VERSION ""

NS_ :

BS_:

BU_: VCU BCM SS IPC ABS ACU

BO_ 872 GW_EDS_Fault: 8 VCU
 SG_ EDS_MotTempSenFault : 0|1@0+ (1,0) [0|1] ""  IPC
 SG_ EDS_EDSOverTempAlarm : 4|1@0+ (1,0) [0|1] ""  IPC
 SG_ EDS_EDSOverTempFault : 5|1@0+ (1,0) [0|1] ""  IPC
 SG_ EDS_LV_VotagtFault : 6|1@0+ (1,0) [0|1] ""  IPC
 SG_ EDS_PhashOverCurrentSWFault : 7|1@0+ (1,0) [0|1] ""  IPC
 SG_ EDS_EDSCurrentSenVFault : 8|1@0+ (1,0) [0|1] ""  IPC
 SG_ EDS_EDSCurrentSenWFault : 9|1@0+ (1,0) [0|1] ""  IPC
 SG_ EDS_EDSHVOverVoltageAlarm : 10|1@0+ (1,0) [0|1] ""  IPC
 SG_ EDS_EDSHVOverVoltageFault : 11|1@0+ (1,0) [0|1] ""  IPC
 SG_ EDS_EDSHVUnderVoltageAlarm : 12|1@0+ (1,0) [0|1] ""  IPC
 SG_ EDS_EDSHVUnderVoltageFault : 13|1@0+ (1,0) [0|1] ""  IPC
 SG_ EDS_MotOverTempAlarm : 14|1@0+ (1,0) [0|1] ""  IPC
 SG_ EDS_MotOverTempFault : 15|1@0+ (1,0) [0|1] ""  IPC
 SG_ EDS_EDSDisChgFault : 16|1@0+ (1,0) [0|1] ""  IPC
 SG_ EDS_EDSHVSenFault : 17|1@0+ (1,0) [0|1] ""  IPC
 SG_ EDS_12VOverVoltageAlarm : 18|1@0+ (1,0) [0|1] ""  IPC
 SG_ EDS_12VUnderVoltageAlarm : 19|1@0+ (1,0) [0|1] ""  IPC
 SG_ EDS_MotOverAlarm : 20|1@0+ (1,0) [0|1] ""  IPC
 SG_ EDS_MotOverFault : 21|1@0+ (1,0) [0|1] ""  IPC
 SG_ EDS_PhashOverCurrentHWFault : 22|1@0+ (1,0) [0|1] ""  IPC
 SG_ EDS_EDSCurrentSenUFault : 23|1@0+ (1,0) [0|1] ""  IPC
 SG_ EDS_VCULostFault : 24|1@0+ (1,0) [0|1] ""  IPC
 SG_ EDS_BMSLostFault : 25|1@0+ (1,0) [0|1] ""  IPC
 SG_ EDS_MotRotSenFault : 26|1@0+ (1,0) [0|1] ""  IPC
 SG_ EDS_MotBlockedFault : 27|1@0+ (1,0) [0|1] ""  IPC
 SG_ EDS_EDSChksumFault : 28|1@0+ (1,0) [0|1] ""  IPC
 SG_ EDS_MotTrqLimtFault : 29|1@0+ (1,0) [0|1] ""  IPC
 SG_ EDS_VCUChksumFault : 30|1@0+ (1,0) [0|1] ""  IPC
 SG_ EDS_EDSEnableFault : 31|1@0+ (1,0) [0|1] ""  IPC
 SG_ EDS_IGBTFault : 38|1@0+ (1,0) [0|1] ""  IPC
 SG_ EDS_CANBUSOFFFault : 39|1@0+ (1,0) [0|1] ""  IPC
 SG_ EDS_EDSTempSensorErr : 43|1@0+ (1,0) [0|1] ""  IPC
 SG_ EDS_HWCapOverVolt : 44|1@0+ (1,0) [0|1] ""  IPC
 SG_ EDS_SWCapOverVolt : 45|1@0+ (1,0) [0|1] ""  IPC
 SG_ EDS_EDSMemoryFlt : 46|1@0+ (1,0) [0|1] ""  IPC
 SG_ EDS_InitMode : 47|1@0+ (1,0) [0|1] ""  IPC
 SG_ EDS_MotorSN : 51|4@0+ (1,0) [0|1] ""  IPC
 SG_ EDS_EDSFaultCode : 63|8@0+ (1,0) [0|255] ""  IPC

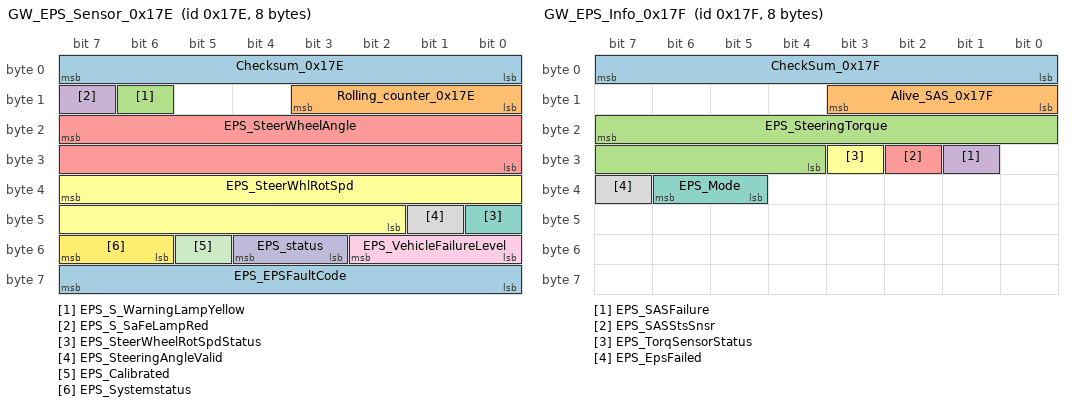
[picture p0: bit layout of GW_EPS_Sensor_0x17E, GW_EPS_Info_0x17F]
BO_ 382 GW_EPS_Sensor_0x17E: 8 VCU
 SG_ Checksum_0x17E : 7|8@0+ (1,0) [0|255] ""  BCM,IPC,ABS,ACU
 SG_ Rolling_counter_0x17E : 11|4@0+ (1,0) [0|15] ""  BCM,IPC,ABS,ACU
 SG_ EPS_S_WarningLampYellow : 14|1@0+ (1,0) [0|1] ""  BCM,IPC,ABS,ACU
 SG_ EPS_S_SaFeLampRed : 15|1@0+ (1,0) [0|1] ""  BCM,IPC,ABS,ACU
 SG_ EPS_SteerWheelAngle : 23|16@0+ (0.0238,-780) [-780|779.7] "deg"  BCM,IPC,ABS,ACU
 SG_ EPS_SteerWhlRotSpd : 39|14@0+ (0.125,-1024) [-1024|1023.75] "degs"  BCM,IPC,ABS,ACU
 SG_ EPS_SteerWheelRotSpdStatus : 40|1@0+ (1,0) [0|1] ""  BCM,IPC,ABS,ACU
 SG_ EPS_SteeringAngleValid : 41|1@0+ (1,0) [0|1] ""  BCM,IPC,ABS,ACU
 SG_ EPS_VehicleFailureLevel : 50|3@0+ (1,0) [0|7] ""  BCM,IPC,ABS,ACU
 SG_ EPS_status : 52|2@0+ (1,0) [0|3] ""  BCM,IPC,ABS,ACU
 SG_ EPS_Calibrated : 53|1@0+ (1,0) [0|1] ""  BCM,IPC,ABS,ACU
 SG_ EPS_Systemstatus : 55|2@0+ (1,0) [0|3] ""  BCM,IPC,ABS,ACU
 SG_ EPS_EPSFaultCode : 63|8@0+ (1,0) [0|63] ""  BCM,IPC,ABS,ACU

BO_ 383 GW_EPS_Info_0x17F: 8 VCU
 SG_ CheckSum_0x17F : 7|8@0+ (1,0) [0|255] ""  BCM,IPC,ABS,ACU
 SG_ Alive_SAS_0x17F : 11|4@0+ (1,0) [0|15] ""  BCM,IPC,ABS,ACU
 SG_ EPS_SteeringTorque : 23|12@0+ (0.01,-10.24) [-10.24|10.23] "N*m"  BCM,IPC,ABS,ACU
 SG_ EPS_SASFailure : 25|1@0+ (1,0) [0|1] ""  BCM,IPC,ABS,ACU
 SG_ EPS_SASStsSnsr : 26|1@0+ (1,0) [0|1] ""  BCM,IPC,ABS,ACU
 SG_ EPS_TorqSensorStatus : 27|1@0+ (1,0) [0|1] ""  BCM,IPC,ABS,ACU
 SG_ EPS_Mode : 38|2@0+ (1,0) [0|3] ""  BCM,IPC,ABS,ACU
 SG_ EPS_EpsFailed : 39|1@0+ (1,0) [0|1] ""  BCM,IPC,ABS,ACU

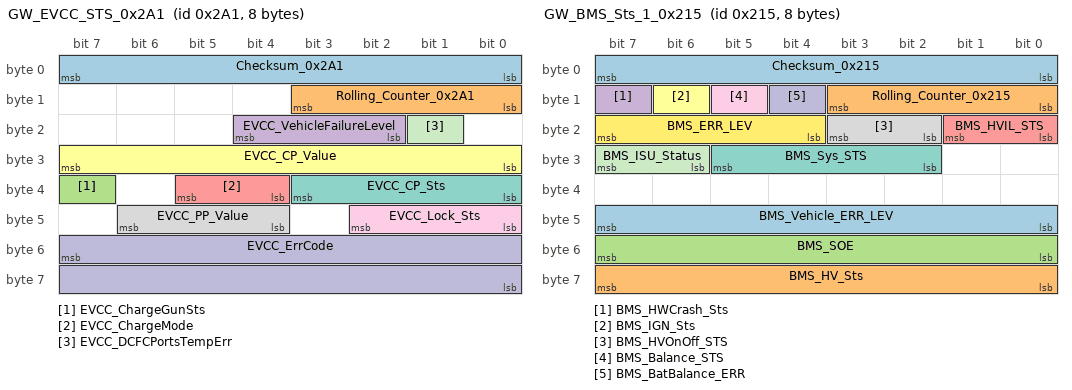
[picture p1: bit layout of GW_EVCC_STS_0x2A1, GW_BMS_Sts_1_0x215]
BO_ 673 GW_EVCC_STS_0x2A1: 8 VCU
 SG_ Checksum_0x2A1 : 7|8@0+ (1,0) [0|255] ""  IPC
 SG_ Rolling_Counter_0x2A1 : 11|4@0+ (1,0) [0|15] ""  IPC
 SG_ EVCC_ChargeGunSts : 39|1@0+ (1,0) [0|1] ""  IPC
 SG_ EVCC_VehicleFailureLevel : 20|3@0+ (1,0) [0|7] ""  IPC
 SG_ EVCC_ChargeMode : 37|2@0+ (1,0) [0|3] ""  IPC
 SG_ EVCC_CP_Value : 31|8@0+ (1,0) [0|100] "%"  IPC
 SG_ EVCC_CP_Sts : 35|4@0+ (1,0) [0|15] ""  IPC
 SG_ EVCC_PP_Value : 46|3@0+ (1,0) [0|7] ""  IPC
 SG_ EVCC_Lock_Sts : 42|3@0+ (1,0) [0|7] ""  IPC
 SG_ EVCC_ErrCode : 55|16@0+ (1,0) [0|65535] ""  IPC
 SG_ EVCC_DCFCPortsTempErr : 17|1@0+ (1,0) [0|1] ""  IPC

BO_ 992 GW_EVCC_HMI_charging_0x3E0: 8 VCU
 SG_ Checksum_0x3E0 : 7|8@0+ (1,0) [0|255] ""  IPC
 SG_ Rolling_Counter_0x3E0 : 11|4@0+ (1,0) [0|15] ""  IPC
 SG_ EVCC_IPC_Ack_ChgSche_stt : 27|2@0+ (1,0) [0|3] ""  IPC
 SG_ EVCC_IPC_Ack_TargetSOC : 39|8@0+ (1,0) [0|100] "%"  IPC

BO_ 537 GW_EVCC_PT_Control_0x219: 8 VCU
 SG_ Checksum_0x219 : 7|8@0+ (1,0) [0|255] ""  BCM,IPC
 SG_ Rolling_Counter_0x219 : 11|4@0+ (1,0) [0|15] ""  BCM,IPC
 SG_ EVCC_ChargeAllow : 54|1@0+ (1,0) [0|1] ""  BCM,IPC
 SG_ EVCC_ChrSOCLitFb : 49|10@0+ (0.1,0) [0|1000] "%"  BCM,IPC

BO_ 293 GW_BMS_Power_0x125: 8 VCU
 SG_ Checksum_0x125 : 7|8@0+ (1,0) [0|255] ""  IPC
 SG_ Rolling_Counter_0x125 : 11|4@0+ (1,0) [0|15] ""  IPC
 SG_ BMS_Actual_ChgPower : 38|15@0+ (0.01,0) [0|100] "Kw"  IPC
 SG_ BMS_Actual_DisChgPower : 54|15@0+ (0.01,0) [0|100] "Kw"  IPC

BO_ 534 GW_BMS_ChgParamReq_0x216: 8 VCU
 SG_ Checksum_0x216 : 7|8@0+ (1,0) [0|255] ""  IPC
 SG_ Rolling_Counter_0x216 : 11|4@0+ (1,0) [0|15] ""  IPC
 SG_ BMS_RemainChargeTime : 21|14@0+ (1,0) [0|16383] "min"  IPC
 SG_ BMS_ChgVoltage_REQ : 37|14@0+ (0.1,0) [0|800] "V"  IPC
 SG_ BMS_ChgCurrent_REQ : 55|16@0+ (0.1,0) [0|1500] "A"  IPC

BO_ 533 GW_BMS_Sts_1_0x215: 8 VCU
 SG_ Checksum_0x215 : 7|8@0+ (1,0) [0|255] ""  BCM,IPC
 SG_ Rolling_Counter_0x215 : 11|4@0+ (1,0) [0|15] ""  BCM,IPC
 SG_ BMS_SOE : 55|8@0+ (0.5,0) [0|100] "%" Vector__XXX
 SG_ BMS_HWCrash_Sts : 15|1@0+ (1,0) [0|1] "" Vector__XXX
 SG_ BMS_HVIL_STS : 17|2@0+ (1,0) [0|3] ""  IPC
 SG_ BMS_IGN_Sts : 14|1@0+ (1,0) [0|1] ""  IPC
 SG_ BMS_Sys_STS : 29|4@0+ (1,0) [0|15] ""  IPC
 SG_ BMS_HVOnOff_STS : 19|2@0+ (1,0) [0|3] ""  IPC
 SG_ BMS_Balance_STS : 13|1@0+ (1,0) [0|1] ""  IPC
 SG_ BMS_BatBalance_ERR : 12|1@0+ (1,0) [0|1] ""  IPC
 SG_ BMS_ISU_Status : 31|2@0+ (1,0) [0|3] ""  IPC
 SG_ BMS_ERR_LEV : 23|4@0+ (1,0) [0|15] ""  IPC
 SG_ BMS_Vehicle_ERR_LEV : 47|8@0+ (1,0) [0|15] ""  IPC
 SG_ BMS_HV_Sts : 63|8@0+ (1,0) [0|255] ""  IPC

BO_ 1171 GW_BMS_WarnMsg_0x493: 8 VCU
 SG_ BMS_Warning_Flag_Reserved_08 : 16|1@0+ (1,0) [0|1] ""  IPC
 SG_ BMS_Warning_Flag_Reserved_07 : 17|1@0+ (1,0) [0|1] ""  IPC
 SG_ BMS_Warning_Flag_Reserved_11 : 47|8@0+ (1,0) [0|255] ""  IPC
 SG_ BMS_Warning_Flag_Reserved_10 : 39|8@0+ (1,0) [0|255] ""  IPC
 SG_ BMS_Warning_Flag_Reserved_09 : 31|8@0+ (1,0) [0|255] ""  IPC
 SG_ BMS_Warning_Flag_Reserved_13 : 63|8@0+ (1,0) [0|255] ""  IPC
 SG_ BMS_Warning_Flag_Reserved_12 : 55|8@0+ (1,0) [0|255] ""  IPC
 SG_ BMS_Warning_Flag_Reserved_06 : 18|1@0+ (1,0) [0|1] ""  IPC
 SG_ BMS_Warning_Flag_Reserved_05 : 19|1@0+ (1,0) [0|1] ""  IPC
 SG_ BMS_Warning_Flag_Reserved_04 : 20|1@0+ (1,0) [0|1] ""  IPC
 SG_ BMS_MalfunctionSts : 21|1@0+ (1,0) [0|1] ""  IPC
 SG_ BMS_LowBattery : 23|2@0+ (1,0) [0|3] ""  IPC
 SG_ BMS_BatteryReplacement : 15|1@0+ (1,0) [0|1] ""  IPC
 SG_ BMS_PackTempSts : 13|2@0+ (1,0) [0|3] ""  IPC
 SG_ BMS_ThermalRunaway : 14|1@0+ (1,0) [0|1] ""  IPC
 SG_ Rolling_Counter_0x493 : 11|4@0+ (1,0) [0|15] ""  IPC
 SG_ Checksum_0x493 : 7|8@0+ (1,0) [0|255] ""  IPC

BO_ 372 GW_BMS_CurMeas_0x174: 8 VCU
 SG_ Checksum_0x174 : 7|8@0+ (1,0) [0|255] ""  IPC
 SG_ Rolling_Counter_0x174 : 11|4@0+ (1,0) [0|15] ""  IPC
 SG_ BMS_PackCur_MEAS : 23|16@0+ (0.1,-3276.8) [-3276.8|3276.7] "A"  IPC
 SG_ BMS_AllowDischgCurr : 39|16@0+ (0.1,0) [0|1500] "A"  IPC
 SG_ BMS_AllowDischgCurrPeak : 55|16@0+ (0.1,0) [0|1500] "A"  IPC

BO_ 374 GW_BMS_HVMeas1_0x176: 8 VCU
 SG_ Checksum_0x176 : 7|8@0+ (1,0) [0|255] ""  IPC
 SG_ Rolling_Counter_0x176 : 11|4@0+ (1,0) [0|15] ""  IPC
 SG_ BMS_HVLinkVol_MEAS : 39|16@0+ (0.1,0) [0|800] "V"  IPC
 SG_ BMS_HVPackVol_MEAS : 23|16@0+ (0.1,0) [0|800] "V"  IPC

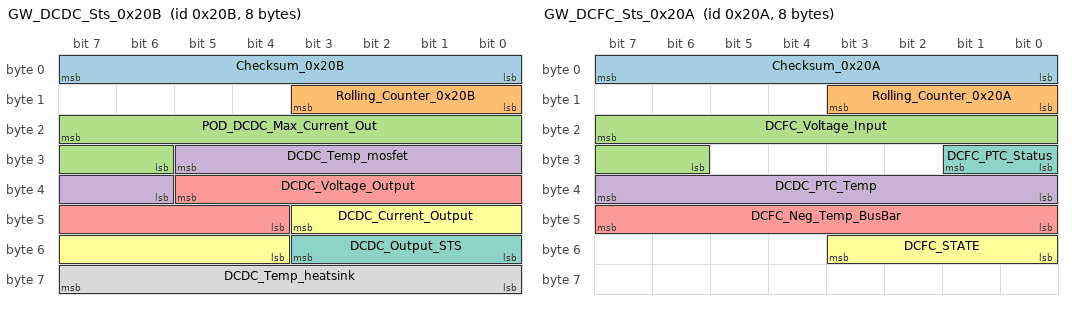
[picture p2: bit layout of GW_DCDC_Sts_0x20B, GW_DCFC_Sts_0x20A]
BO_ 523 GW_DCDC_Sts_0x20B: 8 VCU
 SG_ Checksum_0x20B : 7|8@0+ (1,0) [0|255] ""  IPC
 SG_ Rolling_Counter_0x20B : 11|4@0+ (1,0) [0|15] ""  IPC
 SG_ POD_DCDC_Max_Current_Out : 23|10@0+ (1,0) [0|1000] "A"  IPC
 SG_ DCDC_Temp_mosfet : 29|8@0+ (1,-40) [-40|215] ""  IPC
 SG_ DCDC_Voltage_Output : 37|10@0+ (0.1,0) [0|40] "V"  IPC
 SG_ DCDC_Current_Output : 43|8@0+ (1,0) [0|255] "A"  IPC
 SG_ DCDC_Output_STS : 51|4@0+ (1,0) [0|15] ""  IPC
 SG_ DCDC_Temp_heatsink : 63|8@0+ (1,-40) [-40|215] ""  IPC

BO_ 1030 GW_Error_Level_DCDC_0x406: 8 VCU
 SG_ Checksum_0x406 : 7|8@0+ (1,0) [0|255] ""  IPC
 SG_ Rolling_Counter_0x406 : 11|4@0+ (1,0) [0|15] ""  IPC
 SG_ DCDC_FaultLevel : 19|4@0+ (1,0) [0|15] ""  IPC
 SG_ DCFC_FaultLevel : 23|4@0+ (1,0) [0|15] ""  IPC

BO_ 522 GW_DCFC_Sts_0x20A: 8 VCU
 SG_ Checksum_0x20A : 7|8@0+ (1,0) [0|255] ""  IPC
 SG_ Rolling_Counter_0x20A : 11|4@0+ (1,0) [0|15] ""  IPC
 SG_ DCFC_Voltage_Input : 23|10@0+ (1,0) [0|1000] "V"  IPC
 SG_ DCDC_PTC_Temp : 39|8@0+ (1,-40) [-40|215] ""  IPC
 SG_ DCFC_Neg_Temp_BusBar : 47|8@0+ (1,-40) [-40|215] ""  IPC
 SG_ DCFC_STATE : 51|4@0+ (1,0) [0|15] ""  IPC
 SG_ DCFC_PTC_Status : 25|2@0+ (1,0) [0|3] ""  IPC

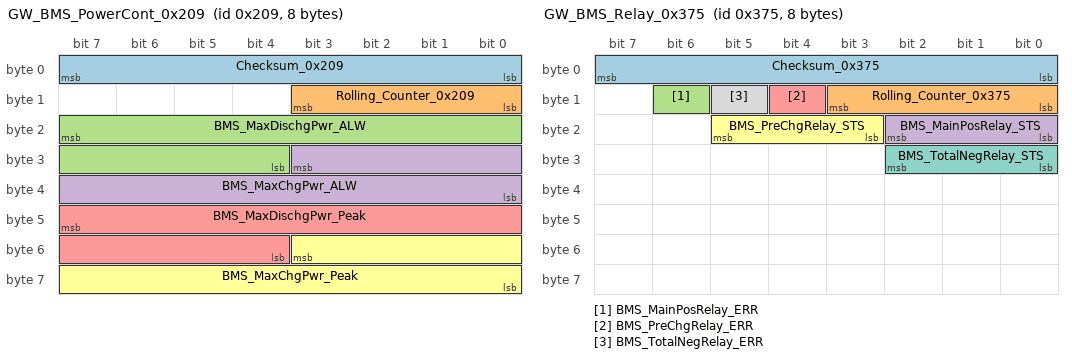
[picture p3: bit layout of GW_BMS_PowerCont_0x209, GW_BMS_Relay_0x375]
BO_ 521 GW_BMS_PowerCont_0x209: 8 VCU
 SG_ Checksum_0x209 : 7|8@0+ (1,0) [0|255] ""  IPC
 SG_ Rolling_Counter_0x209 : 11|4@0+ (1,0) [0|15] ""  IPC
 SG_ BMS_MaxDischgPwr_ALW : 23|12@0+ (0.1,0) [0|400] "KW"  IPC
 SG_ BMS_MaxChgPwr_ALW : 27|12@0+ (0.1,0) [0|400] "KW"  IPC
 SG_ BMS_MaxDischgPwr_Peak : 47|12@0+ (0.2,0) [0|800] "kw"  IPC
 SG_ BMS_MaxChgPwr_Peak : 51|12@0+ (0.2,0) [0|800] "kw"  IPC

BO_ 818 GW_BMS_PackInfo_0x332: 8 VCU
 SG_ Checksum_0x332 : 7|8@0+ (1,0) [0|255] ""  IPC
 SG_ Rolling_Counter_0x332 : 11|4@0+ (1,0) [0|15] ""  IPC
 SG_ BMS_PackTemp_Infor : 39|8@0+ (1,-40) [-40|215] ""  IPC
 SG_ BMS_PackCNom : 23|16@0+ (0.1,0) [0|6553.5] "kwh"  IPC

BO_ 816 GW_BMS_HistData_0x330: 8 VCU
 SG_ Checksum_0x330 : 7|8@0+ (1,0) [0|255] ""  IPC
 SG_ Rolling_Counter_0x330 : 11|4@0+ (1,0) [0|15] ""  IPC
 SG_ BMS_ContactorAging : 23|8@0+ (1,0) [0|100] "%"  IPC

BO_ 375 GW_BMS_HVMeas2_0x177: 8 VCU
 SG_ Checksum_0x177 : 7|8@0+ (1,0) [0|255] ""  IPC
 SG_ Rolling_Counter_0x177 : 11|4@0+ (1,0) [0|15] ""  IPC
 SG_ BMS_HVBusVol_MEAS : 23|16@0+ (0.1,0) [0|800] "V"  IPC
 SG_ BMS_HVFuseVol_MEAS : 39|16@0+ (0.1,0) [0|800] "V"  IPC

BO_ 532 GW_BMS_Sts_0x214: 8 VCU
 SG_ Checksum_0x214 : 7|8@0+ (1,0) [0|255] ""  BCM,IPC
 SG_ Rolling_Counter_0x214 : 11|4@0+ (1,0) [0|15] ""  BCM,IPC
 SG_ BMS_Display_SOC : 21|10@0+ (0.1,0) [0|100] "%"  BCM,IPC
 SG_ BMS_SocActual_EST : 25|10@0+ (0.1,0) [0|100] "percent"  BCM,IPC
 SG_ BMS_SOH : 47|8@0+ (0.5,0) [0|100] "%"  BCM,IPC

BO_ 885 GW_BMS_Relay_0x375: 8 VCU
 SG_ Checksum_0x375 : 7|8@0+ (1,0) [0|255] ""  IPC
 SG_ Rolling_Counter_0x375 : 11|4@0+ (1,0) [0|15] ""  IPC
 SG_ BMS_MainPosRelay_ERR : 14|1@0+ (1,0) [0|1] ""  IPC
 SG_ BMS_MainPosRelay_STS : 18|3@0+ (1,0) [0|7] ""  IPC
 SG_ BMS_PreChgRelay_ERR : 12|1@0+ (1,0) [0|1] ""  IPC
 SG_ BMS_PreChgRelay_STS : 21|3@0+ (1,0) [0|7] ""  IPC
 SG_ BMS_TotalNegRelay_STS : 26|3@0+ (1,0) [0|7] ""  IPC
 SG_ BMS_TotalNegRelay_ERR : 13|1@0+ (1,0) [0|1] ""  IPC

BO_ 773 GW_BMS_Insulation_0x305: 8 VCU
 SG_ Checksum_0x305 : 7|8@0+ (1,0) [0|255] ""  IPC
 SG_ Rolling_Counter_0x305 : 11|4@0+ (1,0) [0|15] ""  IPC
 SG_ BMS_VCU_Insulation_Mon_Sts : 15|1@0+ (1,0) [0|1] ""  IPC
 SG_ BMS_PackInsuRes : 23|16@0+ (1,0) [0|60000] "kOhm"  IPC

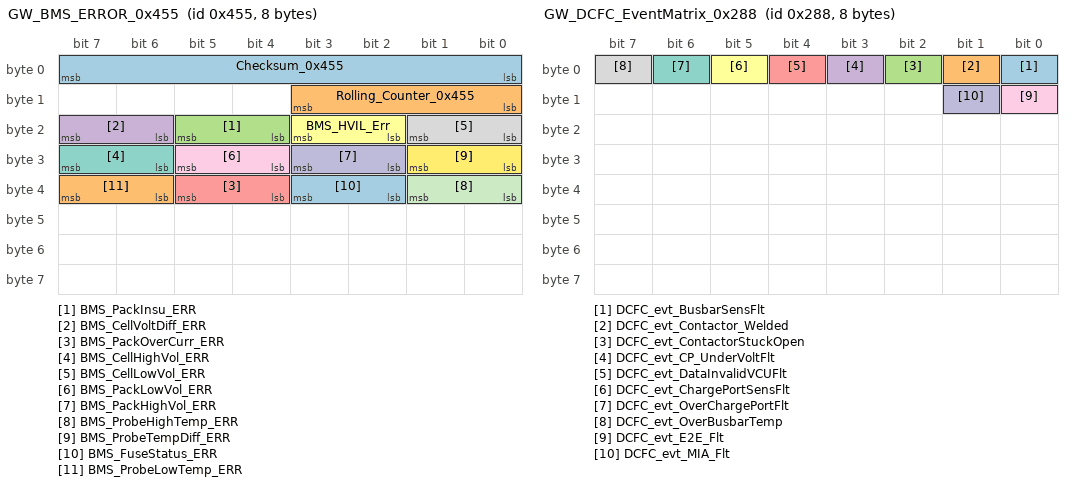
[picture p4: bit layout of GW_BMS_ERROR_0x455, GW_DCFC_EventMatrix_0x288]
BO_ 1109 GW_BMS_ERROR_0x455: 8 VCU
 SG_ Checksum_0x455 : 7|8@0+ (1,0) [0|255] ""  BCM,IPC
 SG_ Rolling_Counter_0x455 : 11|4@0+ (1,0) [0|15] ""  BCM,IPC
 SG_ BMS_PackInsu_ERR : 21|2@0+ (1,0) [0|3] ""  BCM,IPC
 SG_ BMS_CellVoltDiff_ERR : 23|2@0+ (1,0) [0|3] ""  BCM,IPC
 SG_ BMS_PackOverCurr_ERR : 37|2@0+ (1,0) [0|3] ""  BCM,IPC
 SG_ BMS_HVIL_Err : 19|2@0+ (1,0) [0|3] ""  BCM,IPC
 SG_ BMS_CellHighVol_ERR : 31|2@0+ (1,0) [0|3] ""  BCM,IPC
 SG_ BMS_CellLowVol_ERR : 17|2@0+ (1,0) [0|3] ""  BCM,IPC
 SG_ BMS_PackLowVol_ERR : 29|2@0+ (1,0) [0|3] ""  BCM,IPC
 SG_ BMS_PackHighVol_ERR : 27|2@0+ (1,0) [0|3] ""  BCM,IPC
 SG_ BMS_ProbeHighTemp_ERR : 33|2@0+ (1,0) [0|3] ""  BCM,IPC
 SG_ BMS_ProbeTempDiff_ERR : 25|2@0+ (1,0) [0|3] ""  BCM,IPC
 SG_ BMS_FuseStatus_ERR : 35|2@0+ (1,0) [0|1] ""  BCM,IPC
 SG_ BMS_ProbeLowTemp_ERR : 39|2@0+ (1,0) [0|3] ""  BCM,IPC

BO_ 646 GW_DCFC_IO1_0x286: 8 VCU
 SG_ Checksum_0x286 : 7|8@0+ (1,0) [0|255] ""  IPC
 SG_ Rolling_Counter_0x286 : 11|4@0+ (1,0) [0|15] ""  IPC
 SG_ DCFC_OUT_DC_V : 23|16@0+ (0.1,0) [0|6553.5] "V"  IPC
 SG_ DCFC_OUT_DC_I : 39|14@0+ (0.1,0) [0|1000] "A"  IPC
 SG_ DCFC_DCCharge_line_V : 55|16@0+ (0.1,0) [0|6553.5] "V"  IPC

BO_ 647 GW_DCDC_EventMatrix_0x287: 8 VCU
 SG_ DCDC_evt_BUS_OFF : 0|1@0+ (1,0) [0|1] ""  IPC
 SG_ DCDC_evt_MIA : 1|1@0+ (1,0) [0|1] ""  IPC
 SG_ DCDC_evt_E2E : 2|1@0+ (1,0) [0|1] ""  IPC
 SG_ DCDC_evt_Calibration_Flt : 3|1@0+ (1,0) [0|1] ""  IPC
 SG_ DCDC_evt_flash_Failure : 4|1@0+ (1,0) [0|1] ""  IPC
 SG_ DCDC_evt_FaultLatchCircuit : 5|1@0+ (1,0) [0|1] ""  IPC
 SG_ DCDC_evt_HV_VoltSensFlt : 6|1@0+ (1,0) [0|1] ""  IPC
 SG_ DCDC_evt_HV_OverVoltFlt : 7|1@0+ (1,0) [0|1] ""  IPC
 SG_ DCDC_evt_HV_UnderVoltFlt : 8|1@0+ (1,0) [0|1] ""  IPC
 SG_ DCDC_evt_LV_VoltSensFlt : 9|1@0+ (1,0) [0|1] ""  IPC
 SG_ DCDC_evt_LVBatt_OverVoltFlt : 10|1@0+ (1,0) [0|1] ""  IPC
 SG_ DCDC_evt_LVBatt_UnderVoltFlt : 11|1@0+ (1,0) [0|1] ""  IPC
 SG_ DCDC_evt_LVBatt_SensorFlt : 12|1@0+ (1,0) [0|1] ""  IPC
 SG_ DCDC_evt_LV_RedundancyFlt : 13|1@0+ (1,0) [0|1] ""  IPC
 SG_ DCDC_evt_LV_CurrSensFlt : 14|1@0+ (1,0) [0|1] ""  IPC
 SG_ DCDC_evt_LV_OverCurr : 15|1@0+ (1,0) [0|1] ""  IPC
 SG_ DCDC_evt_ReverseCurrFlt : 16|1@0+ (1,0) [0|1] ""  IPC
 SG_ DCDC_evt_Heater_TempSensorFlt : 17|1@0+ (1,0) [0|1] ""  IPC
 SG_ DCDC_evt_Mosfet_TempSensorFlt : 18|1@0+ (1,0) [0|1] ""  IPC
 SG_ DCDC_evt_Mosfet_OverTemp : 19|1@0+ (1,0) [0|1] ""  IPC
 SG_ DCDC_evt_HeatSink_TempSensorFlt : 20|1@0+ (1,0) [0|1] ""  IPC
 SG_ DCDC_evt_HeatSink_OverTemp : 21|1@0+ (1,0) [0|1] ""  IPC
 SG_ DCDC_evt_Heater_OverTempFlt : 22|1@0+ (1,0) [0|1] ""  IPC
 SG_ DCDC_evt_Heater_ShortIGBTFlt : 23|1@0+ (1,0) [0|1] ""  IPC
 SG_ DCDC_evt_LV_ShortOutputFlt : 24|1@0+ (1,0) [0|1] ""  IPC
 SG_ DCDC_evt_sw_BMS_CrashFlt : 25|1@0+ (1,0) [0|1] ""  IPC
 SG_ DCDC_evt_BMS_HVILFlt : 26|1@0+ (1,0) [0|1] ""  IPC

BO_ 648 GW_DCFC_EventMatrix_0x288: 8 VCU
 SG_ DCFC_evt_BusbarSensFlt : 0|1@0+ (1,0) [0|1] ""  IPC
 SG_ DCFC_evt_Contactor_Welded : 1|1@0+ (1,0) [0|1] ""  IPC
 SG_ DCFC_evt_ContactorStuckOpen : 2|1@0+ (1,0) [0|1] ""  IPC
 SG_ DCFC_evt_CP_UnderVoltFlt : 3|1@0+ (1,0) [0|1] ""  IPC
 SG_ DCFC_evt_DataInvalidVCUFlt : 4|1@0+ (1,0) [0|1] ""  IPC
 SG_ DCFC_evt_ChargePortSensFlt : 5|1@0+ (1,0) [0|1] ""  IPC
 SG_ DCFC_evt_OverChargePortFlt : 6|1@0+ (1,0) [0|1] ""  IPC
 SG_ DCFC_evt_OverBusbarTemp : 7|1@0+ (1,0) [0|1] ""  IPC
 SG_ DCFC_evt_E2E_Flt : 8|1@0+ (1,0) [0|1] ""  IPC
 SG_ DCFC_evt_MIA_Flt : 9|1@0+ (1,0) [0|1] ""  IPC

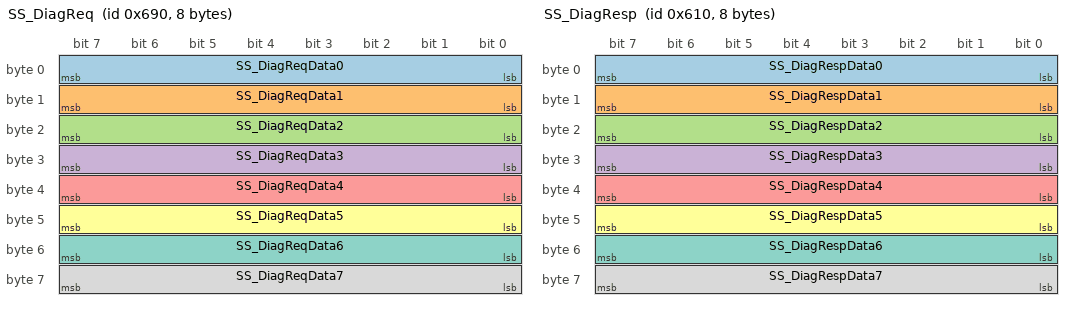
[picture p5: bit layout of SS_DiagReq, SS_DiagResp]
BO_ 1680 SS_DiagReq: 8 VCU
 SG_ SS_DiagReqData0 : 7|8@0+ (1,0) [0|255] ""  SS
 SG_ SS_DiagReqData1 : 15|8@0+ (1,0) [0|255] ""  SS
 SG_ SS_DiagReqData2 : 23|8@0+ (1,0) [0|255] ""  SS
 SG_ SS_DiagReqData3 : 31|8@0+ (1,0) [0|255] ""  SS
 SG_ SS_DiagReqData4 : 39|8@0+ (1,0) [0|255] ""  SS
 SG_ SS_DiagReqData5 : 47|8@0+ (1,0) [0|255] ""  SS
 SG_ SS_DiagReqData6 : 55|8@0+ (1,0) [0|255] ""  SS
 SG_ SS_DiagReqData7 : 63|8@0+ (1,0) [0|255] ""  SS

BO_ 1552 SS_DiagResp: 8 SS
 SG_ SS_DiagRespData0 : 7|8@0+ (1,0) [0|255] ""  VCU,IPC
 SG_ SS_DiagRespData1 : 15|8@0+ (1,0) [0|255] ""  VCU,IPC
 SG_ SS_DiagRespData2 : 23|8@0+ (1,0) [0|255] ""  VCU,IPC
 SG_ SS_DiagRespData3 : 31|8@0+ (1,0) [0|255] ""  VCU,IPC
 SG_ SS_DiagRespData4 : 39|8@0+ (1,0) [0|255] ""  VCU,IPC
 SG_ SS_DiagRespData5 : 47|8@0+ (1,0) [0|255] ""  VCU,IPC
 SG_ SS_DiagRespData6 : 55|8@0+ (1,0) [0|255] ""  VCU,IPC
 SG_ SS_DiagRespData7 : 63|8@0+ (1,0) [0|255] ""  VCU,IPC

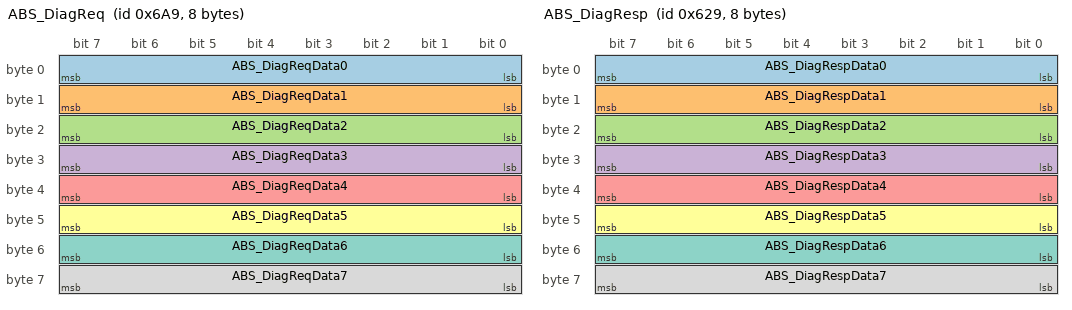
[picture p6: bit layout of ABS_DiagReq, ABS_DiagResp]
BO_ 1705 ABS_DiagReq: 8 VCU
 SG_ ABS_DiagReqData0 : 7|8@0+ (1,0) [0|255] ""  ABS
 SG_ ABS_DiagReqData1 : 15|8@0+ (1,0) [0|255] ""  ABS
 SG_ ABS_DiagReqData2 : 23|8@0+ (1,0) [0|255] ""  ABS
 SG_ ABS_DiagReqData3 : 31|8@0+ (1,0) [0|255] ""  ABS
 SG_ ABS_DiagReqData4 : 39|8@0+ (1,0) [0|255] ""  ABS
 SG_ ABS_DiagReqData5 : 47|8@0+ (1,0) [0|255] ""  ABS
 SG_ ABS_DiagReqData6 : 55|8@0+ (1,0) [0|255] ""  ABS
 SG_ ABS_DiagReqData7 : 63|8@0+ (1,0) [0|255] ""  ABS

BO_ 1577 ABS_DiagResp: 8 ABS
 SG_ ABS_DiagRespData0 : 7|8@0+ (1,0) [0|255] ""  VCU,IPC
 SG_ ABS_DiagRespData1 : 15|8@0+ (1,0) [0|255] ""  VCU,IPC
 SG_ ABS_DiagRespData2 : 23|8@0+ (1,0) [0|255] ""  VCU,IPC
 SG_ ABS_DiagRespData3 : 31|8@0+ (1,0) [0|255] ""  VCU,IPC
 SG_ ABS_DiagRespData4 : 39|8@0+ (1,0) [0|255] ""  VCU,IPC
 SG_ ABS_DiagRespData5 : 47|8@0+ (1,0) [0|255] ""  VCU,IPC
 SG_ ABS_DiagRespData6 : 55|8@0+ (1,0) [0|255] ""  VCU,IPC
 SG_ ABS_DiagRespData7 : 63|8@0+ (1,0) [0|255] ""  VCU,IPC

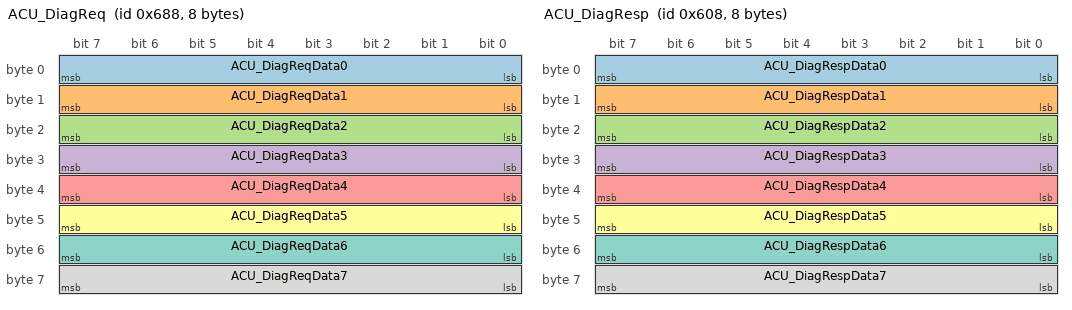
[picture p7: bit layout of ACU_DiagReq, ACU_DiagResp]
BO_ 1672 ACU_DiagReq: 8 VCU
 SG_ ACU_DiagReqData0 : 7|8@0+ (1,0) [0|255] ""  ACU
 SG_ ACU_DiagReqData1 : 15|8@0+ (1,0) [0|255] ""  ACU
 SG_ ACU_DiagReqData2 : 23|8@0+ (1,0) [0|255] ""  ACU
 SG_ ACU_DiagReqData3 : 31|8@0+ (1,0) [0|255] ""  ACU
 SG_ ACU_DiagReqData4 : 39|8@0+ (1,0) [0|255] ""  ACU
 SG_ ACU_DiagReqData5 : 47|8@0+ (1,0) [0|255] ""  ACU
 SG_ ACU_DiagReqData6 : 55|8@0+ (1,0) [0|255] ""  ACU
 SG_ ACU_DiagReqData7 : 63|8@0+ (1,0) [0|255] ""  ACU

BO_ 1544 ACU_DiagResp: 8 ACU
 SG_ ACU_DiagRespData0 : 7|8@0+ (1,0) [0|255] ""  VCU,IPC
 SG_ ACU_DiagRespData1 : 15|8@0+ (1,0) [0|255] ""  VCU,IPC
 SG_ ACU_DiagRespData2 : 23|8@0+ (1,0) [0|255] ""  VCU,IPC
 SG_ ACU_DiagRespData3 : 31|8@0+ (1,0) [0|255] ""  VCU,IPC
 SG_ ACU_DiagRespData4 : 39|8@0+ (1,0) [0|255] ""  VCU,IPC
 SG_ ACU_DiagRespData5 : 47|8@0+ (1,0) [0|255] ""  VCU,IPC
 SG_ ACU_DiagRespData6 : 55|8@0+ (1,0) [0|255] ""  VCU,IPC
 SG_ ACU_DiagRespData7 : 63|8@0+ (1,0) [0|255] ""  VCU,IPC

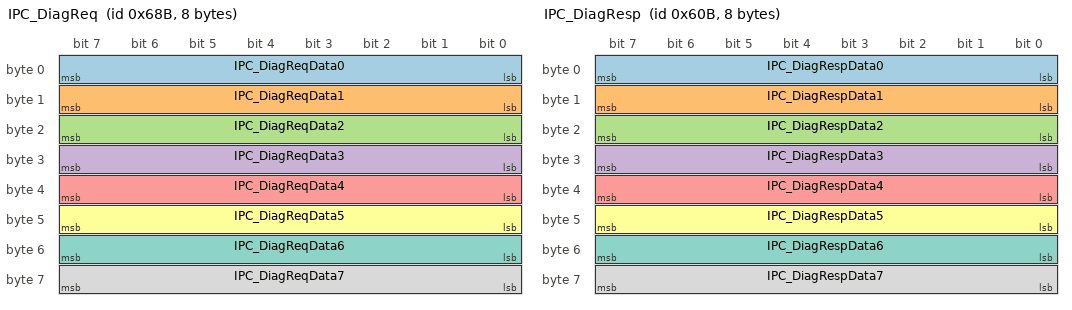
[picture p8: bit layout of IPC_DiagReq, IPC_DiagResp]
BO_ 1675 IPC_DiagReq: 8 VCU
 SG_ IPC_DiagReqData0 : 7|8@0+ (1,0) [0|255] ""  IPC
 SG_ IPC_DiagReqData1 : 15|8@0+ (1,0) [0|255] ""  IPC
 SG_ IPC_DiagReqData2 : 23|8@0+ (1,0) [0|255] ""  IPC
 SG_ IPC_DiagReqData3 : 31|8@0+ (1,0) [0|255] ""  IPC
 SG_ IPC_DiagReqData4 : 39|8@0+ (1,0) [0|255] ""  IPC
 SG_ IPC_DiagReqData5 : 47|8@0+ (1,0) [0|255] ""  IPC
 SG_ IPC_DiagReqData6 : 55|8@0+ (1,0) [0|255] ""  IPC
 SG_ IPC_DiagReqData7 : 63|8@0+ (1,0) [0|255] ""  IPC

BO_ 1547 IPC_DiagResp: 8 IPC
 SG_ IPC_DiagRespData0 : 7|8@0+ (1,0) [0|255] ""  VCU
 SG_ IPC_DiagRespData1 : 15|8@0+ (1,0) [0|255] ""  VCU
 SG_ IPC_DiagRespData2 : 23|8@0+ (1,0) [0|255] ""  VCU
 SG_ IPC_DiagRespData3 : 31|8@0+ (1,0) [0|255] ""  VCU
 SG_ IPC_DiagRespData4 : 39|8@0+ (1,0) [0|255] ""  VCU
 SG_ IPC_DiagRespData5 : 47|8@0+ (1,0) [0|255] ""  VCU
 SG_ IPC_DiagRespData6 : 55|8@0+ (1,0) [0|255] ""  VCU
 SG_ IPC_DiagRespData7 : 63|8@0+ (1,0) [0|255] ""  VCU

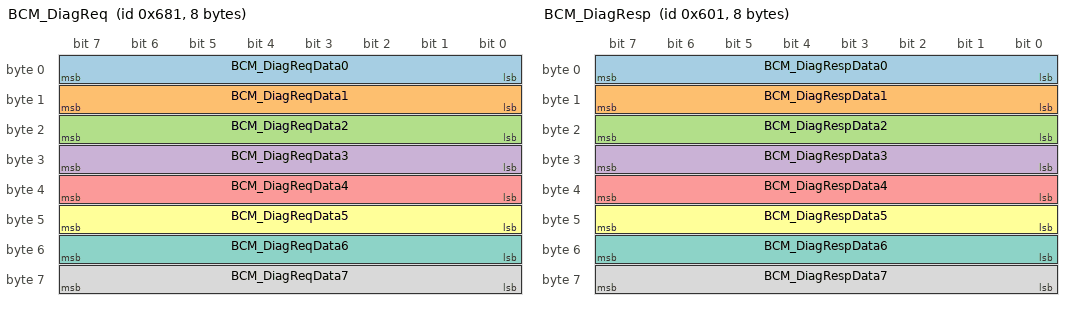
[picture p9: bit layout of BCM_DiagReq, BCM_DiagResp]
BO_ 1665 BCM_DiagReq: 8 VCU
 SG_ BCM_DiagReqData0 : 7|8@0+ (1,0) [0|255] ""  BCM
 SG_ BCM_DiagReqData1 : 15|8@0+ (1,0) [0|255] ""  BCM
 SG_ BCM_DiagReqData2 : 23|8@0+ (1,0) [0|255] ""  BCM
 SG_ BCM_DiagReqData3 : 31|8@0+ (1,0) [0|255] ""  BCM
 SG_ BCM_DiagReqData4 : 39|8@0+ (1,0) [0|255] ""  BCM
 SG_ BCM_DiagReqData5 : 47|8@0+ (1,0) [0|255] ""  BCM
 SG_ BCM_DiagReqData6 : 55|8@0+ (1,0) [0|255] ""  BCM
 SG_ BCM_DiagReqData7 : 63|8@0+ (1,0) [0|255] ""  BCM

BO_ 1537 BCM_DiagResp: 8 BCM
 SG_ BCM_DiagRespData0 : 7|8@0+ (1,0) [0|255] ""  VCU,IPC
 SG_ BCM_DiagRespData1 : 15|8@0+ (1,0) [0|255] ""  VCU,IPC
 SG_ BCM_DiagRespData2 : 23|8@0+ (1,0) [0|255] ""  VCU,IPC
 SG_ BCM_DiagRespData3 : 31|8@0+ (1,0) [0|255] ""  VCU,IPC
 SG_ BCM_DiagRespData4 : 39|8@0+ (1,0) [0|255] ""  VCU,IPC
 SG_ BCM_DiagRespData5 : 47|8@0+ (1,0) [0|255] ""  VCU,IPC
 SG_ BCM_DiagRespData6 : 55|8@0+ (1,0) [0|255] ""  VCU,IPC
 SG_ BCM_DiagRespData7 : 63|8@0+ (1,0) [0|255] ""  VCU,IPC

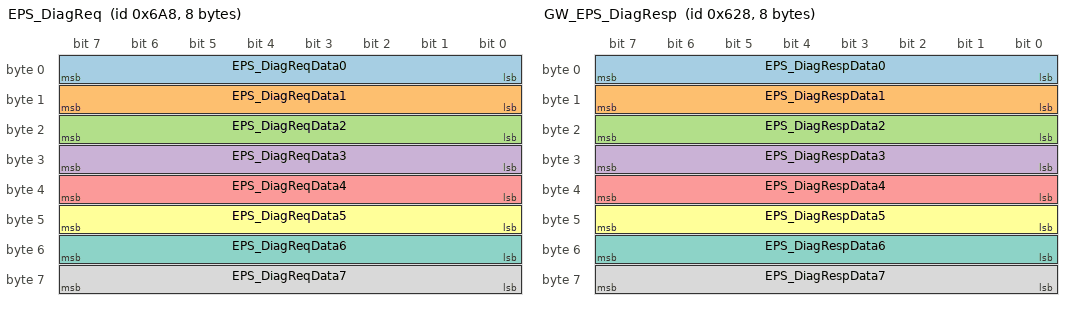
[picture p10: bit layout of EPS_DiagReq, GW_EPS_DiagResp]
BO_ 1704 EPS_DiagReq: 8 IPC
 SG_ EPS_DiagReqData0 : 7|8@0+ (1,0) [0|255] ""  VCU
 SG_ EPS_DiagReqData1 : 15|8@0+ (1,0) [0|255] ""  VCU
 SG_ EPS_DiagReqData2 : 23|8@0+ (1,0) [0|255] ""  VCU
 SG_ EPS_DiagReqData3 : 31|8@0+ (1,0) [0|255] ""  VCU
 SG_ EPS_DiagReqData4 : 39|8@0+ (1,0) [0|255] ""  VCU
 SG_ EPS_DiagReqData5 : 47|8@0+ (1,0) [0|255] ""  VCU
 SG_ EPS_DiagReqData6 : 55|8@0+ (1,0) [0|255] ""  VCU
 SG_ EPS_DiagReqData7 : 63|8@0+ (1,0) [0|255] ""  VCU

BO_ 1576 GW_EPS_DiagResp: 8 VCU
 SG_ EPS_DiagRespData0 : 7|8@0+ (1,0) [0|255] ""  IPC
 SG_ EPS_DiagRespData1 : 15|8@0+ (1,0) [0|255] ""  IPC
 SG_ EPS_DiagRespData2 : 23|8@0+ (1,0) [0|255] ""  IPC
 SG_ EPS_DiagRespData3 : 31|8@0+ (1,0) [0|255] ""  IPC
 SG_ EPS_DiagRespData4 : 39|8@0+ (1,0) [0|255] ""  IPC
 SG_ EPS_DiagRespData5 : 47|8@0+ (1,0) [0|255] ""  IPC
 SG_ EPS_DiagRespData6 : 55|8@0+ (1,0) [0|255] ""  IPC
 SG_ EPS_DiagRespData7 : 63|8@0+ (1,0) [0|255] ""  IPC

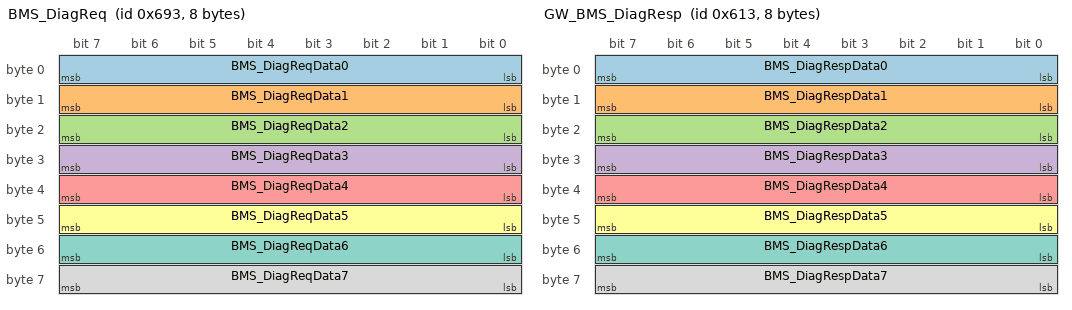
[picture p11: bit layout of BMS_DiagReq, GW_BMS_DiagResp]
BO_ 1683 BMS_DiagReq: 8 IPC
 SG_ BMS_DiagReqData0 : 7|8@0+ (1,0) [0|255] ""  VCU
 SG_ BMS_DiagReqData1 : 15|8@0+ (1,0) [0|255] ""  VCU
 SG_ BMS_DiagReqData2 : 23|8@0+ (1,0) [0|255] ""  VCU
 SG_ BMS_DiagReqData3 : 31|8@0+ (1,0) [0|255] ""  VCU
 SG_ BMS_DiagReqData4 : 39|8@0+ (1,0) [0|255] ""  VCU
 SG_ BMS_DiagReqData5 : 47|8@0+ (1,0) [0|255] ""  VCU
 SG_ BMS_DiagReqData6 : 55|8@0+ (1,0) [0|255] ""  VCU
 SG_ BMS_DiagReqData7 : 63|8@0+ (1,0) [0|255] ""  VCU

BO_ 1555 GW_BMS_DiagResp: 8 VCU
 SG_ BMS_DiagRespData0 : 7|8@0+ (1,0) [0|255] ""  IPC
 SG_ BMS_DiagRespData1 : 15|8@0+ (1,0) [0|255] ""  IPC
 SG_ BMS_DiagRespData2 : 23|8@0+ (1,0) [0|255] ""  IPC
 SG_ BMS_DiagRespData3 : 31|8@0+ (1,0) [0|255] ""  IPC
 SG_ BMS_DiagRespData4 : 39|8@0+ (1,0) [0|255] ""  IPC
 SG_ BMS_DiagRespData5 : 47|8@0+ (1,0) [0|255] ""  IPC
 SG_ BMS_DiagRespData6 : 55|8@0+ (1,0) [0|255] ""  IPC
 SG_ BMS_DiagRespData7 : 63|8@0+ (1,0) [0|255] ""  IPC

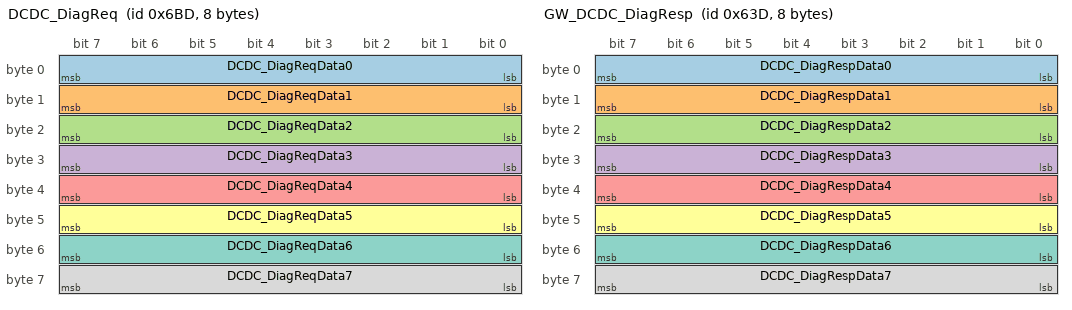
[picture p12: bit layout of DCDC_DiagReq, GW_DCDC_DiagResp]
BO_ 1725 DCDC_DiagReq: 8 IPC
 SG_ DCDC_DiagReqData0 : 7|8@0+ (1,0) [0|255] ""  VCU
 SG_ DCDC_DiagReqData1 : 15|8@0+ (1,0) [0|255] ""  VCU
 SG_ DCDC_DiagReqData2 : 23|8@0+ (1,0) [0|255] ""  VCU
 SG_ DCDC_DiagReqData3 : 31|8@0+ (1,0) [0|255] ""  VCU
 SG_ DCDC_DiagReqData4 : 39|8@0+ (1,0) [0|255] ""  VCU
 SG_ DCDC_DiagReqData5 : 47|8@0+ (1,0) [0|255] ""  VCU
 SG_ DCDC_DiagReqData6 : 55|8@0+ (1,0) [0|255] ""  VCU
 SG_ DCDC_DiagReqData7 : 63|8@0+ (1,0) [0|255] ""  VCU

BO_ 1597 GW_DCDC_DiagResp: 8 VCU
 SG_ DCDC_DiagRespData0 : 7|8@0+ (1,0) [0|255] ""  IPC
 SG_ DCDC_DiagRespData1 : 15|8@0+ (1,0) [0|255] ""  IPC
 SG_ DCDC_DiagRespData2 : 23|8@0+ (1,0) [0|255] ""  IPC
 SG_ DCDC_DiagRespData3 : 31|8@0+ (1,0) [0|255] ""  IPC
 SG_ DCDC_DiagRespData4 : 39|8@0+ (1,0) [0|255] ""  IPC
 SG_ DCDC_DiagRespData5 : 47|8@0+ (1,0) [0|255] ""  IPC
 SG_ DCDC_DiagRespData6 : 55|8@0+ (1,0) [0|255] ""  IPC
 SG_ DCDC_DiagRespData7 : 63|8@0+ (1,0) [0|255] ""  IPC

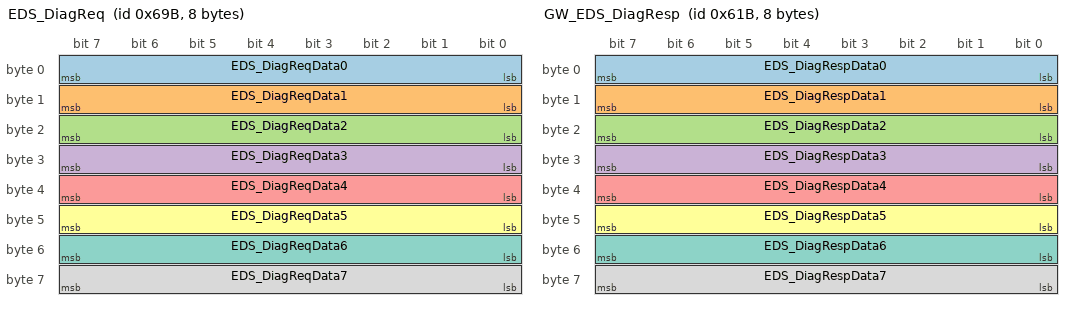
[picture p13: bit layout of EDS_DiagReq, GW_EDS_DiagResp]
BO_ 1691 EDS_DiagReq: 8 IPC
 SG_ EDS_DiagReqData0 : 7|8@0+ (1,0) [0|255] ""  VCU
 SG_ EDS_DiagReqData1 : 15|8@0+ (1,0) [0|255] ""  VCU
 SG_ EDS_DiagReqData2 : 23|8@0+ (1,0) [0|255] ""  VCU
 SG_ EDS_DiagReqData3 : 31|8@0+ (1,0) [0|255] ""  VCU
 SG_ EDS_DiagReqData4 : 39|8@0+ (1,0) [0|255] ""  VCU
 SG_ EDS_DiagReqData5 : 47|8@0+ (1,0) [0|255] ""  VCU
 SG_ EDS_DiagReqData6 : 55|8@0+ (1,0) [0|255] ""  VCU
 SG_ EDS_DiagReqData7 : 63|8@0+ (1,0) [0|255] ""  VCU

BO_ 1563 GW_EDS_DiagResp: 8 VCU
 SG_ EDS_DiagRespData0 : 7|8@0+ (1,0) [0|255] ""  IPC
 SG_ EDS_DiagRespData1 : 15|8@0+ (1,0) [0|255] ""  IPC
 SG_ EDS_DiagRespData2 : 23|8@0+ (1,0) [0|255] ""  IPC
 SG_ EDS_DiagRespData3 : 31|8@0+ (1,0) [0|255] ""  IPC
 SG_ EDS_DiagRespData4 : 39|8@0+ (1,0) [0|255] ""  IPC
 SG_ EDS_DiagRespData5 : 47|8@0+ (1,0) [0|255] ""  IPC
 SG_ EDS_DiagRespData6 : 55|8@0+ (1,0) [0|255] ""  IPC
 SG_ EDS_DiagRespData7 : 63|8@0+ (1,0) [0|255] ""  IPC

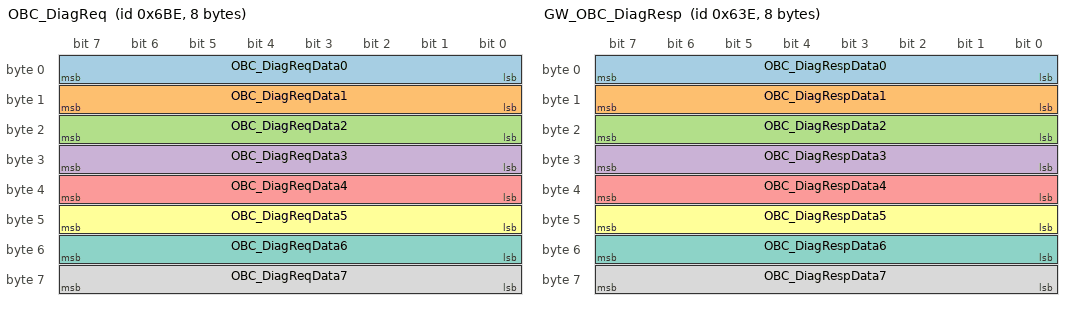
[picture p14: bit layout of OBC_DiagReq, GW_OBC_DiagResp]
BO_ 1726 OBC_DiagReq: 8 IPC
 SG_ OBC_DiagReqData0 : 7|8@0+ (1,0) [0|255] ""  VCU
 SG_ OBC_DiagReqData1 : 15|8@0+ (1,0) [0|255] ""  VCU
 SG_ OBC_DiagReqData2 : 23|8@0+ (1,0) [0|255] ""  VCU
 SG_ OBC_DiagReqData3 : 31|8@0+ (1,0) [0|255] ""  VCU
 SG_ OBC_DiagReqData4 : 39|8@0+ (1,0) [0|255] ""  VCU
 SG_ OBC_DiagReqData5 : 47|8@0+ (1,0) [0|255] ""  VCU
 SG_ OBC_DiagReqData6 : 55|8@0+ (1,0) [0|255] ""  VCU
 SG_ OBC_DiagReqData7 : 63|8@0+ (1,0) [0|255] ""  VCU

BO_ 1598 GW_OBC_DiagResp: 8 VCU
 SG_ OBC_DiagRespData0 : 7|8@0+ (1,0) [0|255] ""  IPC
 SG_ OBC_DiagRespData1 : 15|8@0+ (1,0) [0|255] ""  IPC
 SG_ OBC_DiagRespData2 : 23|8@0+ (1,0) [0|255] ""  IPC
 SG_ OBC_DiagRespData3 : 31|8@0+ (1,0) [0|255] ""  IPC
 SG_ OBC_DiagRespData4 : 39|8@0+ (1,0) [0|255] ""  IPC
 SG_ OBC_DiagRespData5 : 47|8@0+ (1,0) [0|255] ""  IPC
 SG_ OBC_DiagRespData6 : 55|8@0+ (1,0) [0|255] ""  IPC
 SG_ OBC_DiagRespData7 : 63|8@0+ (1,0) [0|255] ""  IPC

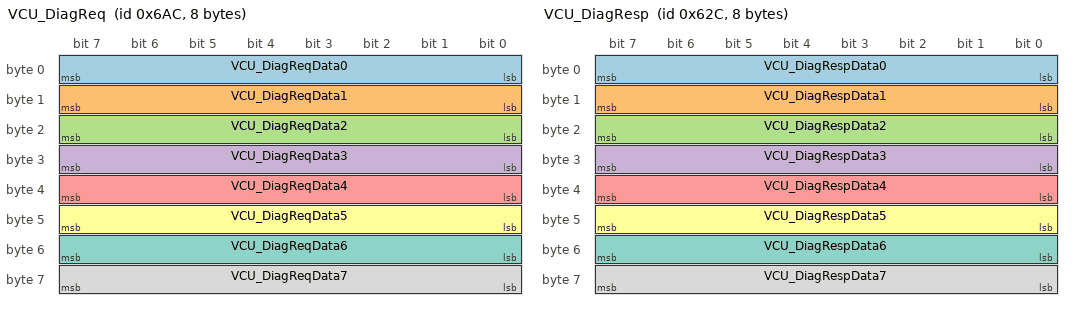
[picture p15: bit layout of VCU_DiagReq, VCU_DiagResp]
BO_ 1708 VCU_DiagReq: 8 IPC
 SG_ VCU_DiagReqData0 : 7|8@0+ (1,0) [0|255] ""  VCU
 SG_ VCU_DiagReqData1 : 15|8@0+ (1,0) [0|255] ""  VCU
 SG_ VCU_DiagReqData2 : 23|8@0+ (1,0) [0|255] ""  VCU
 SG_ VCU_DiagReqData3 : 31|8@0+ (1,0) [0|255] ""  VCU
 SG_ VCU_DiagReqData4 : 39|8@0+ (1,0) [0|255] ""  VCU
 SG_ VCU_DiagReqData5 : 47|8@0+ (1,0) [0|255] ""  VCU
 SG_ VCU_DiagReqData6 : 55|8@0+ (1,0) [0|255] ""  VCU
 SG_ VCU_DiagReqData7 : 63|8@0+ (1,0) [0|255] ""  VCU

BO_ 1580 VCU_DiagResp: 8 VCU
 SG_ VCU_DiagRespData0 : 7|8@0+ (1,0) [0|255] ""  IPC
 SG_ VCU_DiagRespData1 : 15|8@0+ (1,0) [0|255] ""  IPC
 SG_ VCU_DiagRespData2 : 23|8@0+ (1,0) [0|255] ""  IPC
 SG_ VCU_DiagRespData3 : 31|8@0+ (1,0) [0|255] ""  IPC
 SG_ VCU_DiagRespData4 : 39|8@0+ (1,0) [0|255] ""  IPC
 SG_ VCU_DiagRespData5 : 47|8@0+ (1,0) [0|255] ""  IPC
 SG_ VCU_DiagRespData6 : 55|8@0+ (1,0) [0|255] ""  IPC
 SG_ VCU_DiagRespData7 : 63|8@0+ (1,0) [0|255] ""  IPC

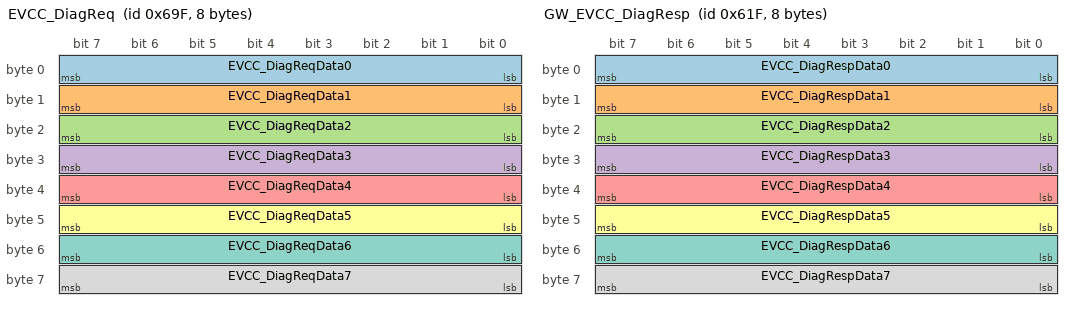
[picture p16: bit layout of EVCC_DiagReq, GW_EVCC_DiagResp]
BO_ 1695 EVCC_DiagReq: 8 IPC
 SG_ EVCC_DiagReqData0 : 7|8@0+ (1,0) [0|255] ""  VCU
 SG_ EVCC_DiagReqData1 : 15|8@0+ (1,0) [0|255] ""  VCU
 SG_ EVCC_DiagReqData2 : 23|8@0+ (1,0) [0|255] ""  VCU
 SG_ EVCC_DiagReqData3 : 31|8@0+ (1,0) [0|255] ""  VCU
 SG_ EVCC_DiagReqData4 : 39|8@0+ (1,0) [0|255] ""  VCU
 SG_ EVCC_DiagReqData5 : 47|8@0+ (1,0) [0|255] ""  VCU
 SG_ EVCC_DiagReqData6 : 55|8@0+ (1,0) [0|255] ""  VCU
 SG_ EVCC_DiagReqData7 : 63|8@0+ (1,0) [0|255] ""  VCU

BO_ 1567 GW_EVCC_DiagResp: 8 VCU
 SG_ EVCC_DiagRespData0 : 7|8@0+ (1,0) [0|255] ""  IPC
 SG_ EVCC_DiagRespData1 : 15|8@0+ (1,0) [0|255] ""  IPC
 SG_ EVCC_DiagRespData2 : 23|8@0+ (1,0) [0|255] ""  IPC
 SG_ EVCC_DiagRespData3 : 31|8@0+ (1,0) [0|255] ""  IPC
 SG_ EVCC_DiagRespData4 : 39|8@0+ (1,0) [0|255] ""  IPC
 SG_ EVCC_DiagRespData5 : 47|8@0+ (1,0) [0|255] ""  IPC
 SG_ EVCC_DiagRespData6 : 55|8@0+ (1,0) [0|255] ""  IPC
 SG_ EVCC_DiagRespData7 : 63|8@0+ (1,0) [0|255] ""  IPC

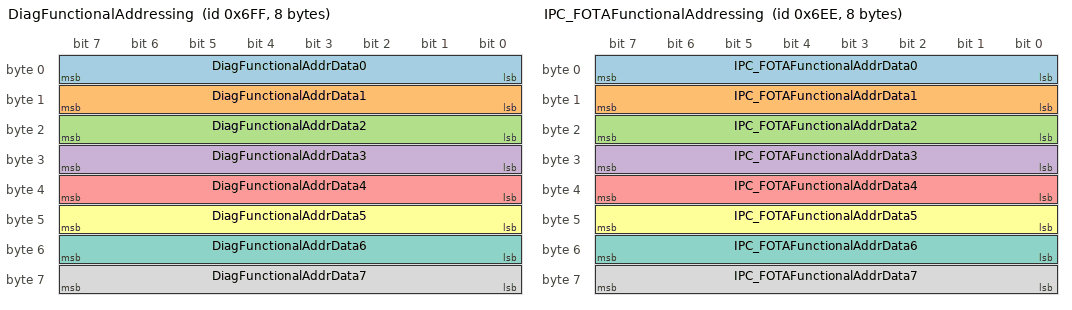
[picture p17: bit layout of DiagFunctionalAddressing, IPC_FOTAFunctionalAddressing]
BO_ 1791 DiagFunctionalAddressing: 8 VCU
 SG_ DiagFunctionalAddrData0 : 7|8@0+ (1,0) [0|255] ""  BCM,SS,IPC,ABS,ACU
 SG_ DiagFunctionalAddrData1 : 15|8@0+ (1,0) [0|255] ""  BCM,SS,IPC,ABS,ACU
 SG_ DiagFunctionalAddrData2 : 23|8@0+ (1,0) [0|255] ""  BCM,SS,IPC,ABS,ACU
 SG_ DiagFunctionalAddrData3 : 31|8@0+ (1,0) [0|255] ""  BCM,SS,IPC,ABS,ACU
 SG_ DiagFunctionalAddrData4 : 39|8@0+ (1,0) [0|255] ""  BCM,SS,IPC,ABS,ACU
 SG_ DiagFunctionalAddrData5 : 47|8@0+ (1,0) [0|255] ""  BCM,SS,IPC,ABS,ACU
 SG_ DiagFunctionalAddrData6 : 55|8@0+ (1,0) [0|255] ""  BCM,SS,IPC,ABS,ACU
 SG_ DiagFunctionalAddrData7 : 63|8@0+ (1,0) [0|255] ""  BCM,SS,IPC,ABS,ACU

BO_ 1774 IPC_FOTAFunctionalAddressing: 8 IPC
 SG_ IPC_FOTAFunctionalAddrData0 : 7|8@0+ (1,0) [0|255] ""  VCU
 SG_ IPC_FOTAFunctionalAddrData1 : 15|8@0+ (1,0) [0|255] ""  VCU
 SG_ IPC_FOTAFunctionalAddrData2 : 23|8@0+ (1,0) [0|255] ""  VCU
 SG_ IPC_FOTAFunctionalAddrData3 : 31|8@0+ (1,0) [0|255] ""  VCU
 SG_ IPC_FOTAFunctionalAddrData4 : 39|8@0+ (1,0) [0|255] ""  VCU
 SG_ IPC_FOTAFunctionalAddrData5 : 47|8@0+ (1,0) [0|255] ""  VCU
 SG_ IPC_FOTAFunctionalAddrData6 : 55|8@0+ (1,0) [0|255] ""  VCU
 SG_ IPC_FOTAFunctionalAddrData7 : 63|8@0+ (1,0) [0|255] ""  VCU

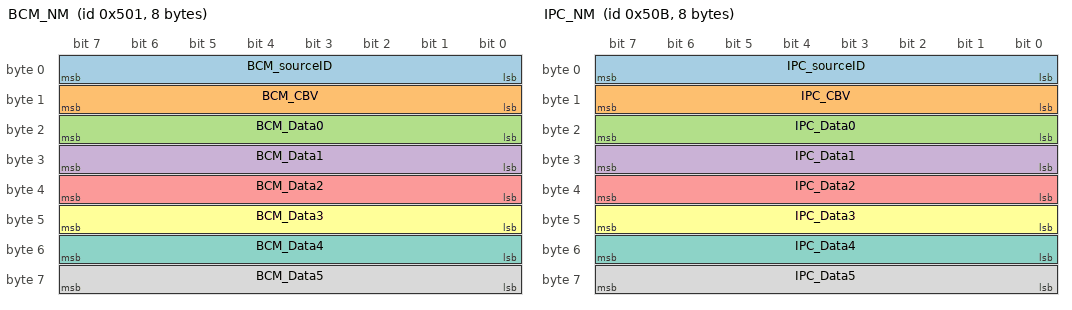
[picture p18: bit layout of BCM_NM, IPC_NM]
BO_ 1281 BCM_NM: 8 BCM
 SG_ BCM_sourceID : 7|8@0+ (1,0) [0|255] ""  VCU,SS,IPC
 SG_ BCM_CBV : 15|8@0+ (1,0) [0|255] ""  VCU,SS,IPC
 SG_ BCM_Data0 : 23|8@0+ (1,0) [0|255] ""  VCU,SS,IPC
 SG_ BCM_Data1 : 31|8@0+ (1,0) [0|255] ""  VCU,SS,IPC
 SG_ BCM_Data2 : 39|8@0+ (1,0) [0|255] ""  VCU,SS,IPC
 SG_ BCM_Data3 : 47|8@0+ (1,0) [0|255] ""  VCU,SS,IPC
 SG_ BCM_Data4 : 55|8@0+ (1,0) [0|255] ""  VCU,SS,IPC
 SG_ BCM_Data5 : 63|8@0+ (1,0) [0|255] ""  VCU,SS,IPC

BO_ 1291 IPC_NM: 8 IPC
 SG_ IPC_sourceID : 7|8@0+ (1,0) [0|255] ""  VCU,BCM,SS
 SG_ IPC_CBV : 15|8@0+ (1,0) [0|255] ""  VCU,BCM,SS
 SG_ IPC_Data0 : 23|8@0+ (1,0) [0|255] ""  VCU,BCM,SS
 SG_ IPC_Data1 : 31|8@0+ (1,0) [0|255] ""  VCU,BCM,SS
 SG_ IPC_Data2 : 39|8@0+ (1,0) [0|255] ""  VCU,BCM,SS
 SG_ IPC_Data3 : 47|8@0+ (1,0) [0|255] ""  VCU,BCM,SS
 SG_ IPC_Data4 : 55|8@0+ (1,0) [0|255] ""  VCU,BCM,SS
 SG_ IPC_Data5 : 63|8@0+ (1,0) [0|255] ""  VCU,BCM,SS

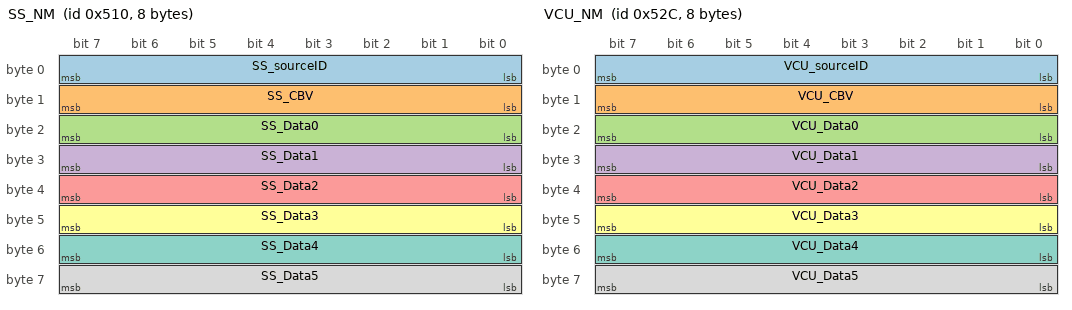
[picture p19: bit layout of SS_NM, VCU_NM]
BO_ 1296 SS_NM: 8 SS
 SG_ SS_sourceID : 7|8@0+ (1,0) [0|255] ""  VCU,BCM,IPC
 SG_ SS_CBV : 15|8@0+ (1,0) [0|255] ""  VCU,BCM,IPC
 SG_ SS_Data0 : 23|8@0+ (1,0) [0|255] ""  VCU,BCM,IPC
 SG_ SS_Data1 : 31|8@0+ (1,0) [0|255] ""  VCU,BCM,IPC
 SG_ SS_Data2 : 39|8@0+ (1,0) [0|255] ""  VCU,BCM,IPC
 SG_ SS_Data3 : 47|8@0+ (1,0) [0|255] ""  VCU,BCM,IPC
 SG_ SS_Data4 : 55|8@0+ (1,0) [0|255] ""  VCU,BCM,IPC
 SG_ SS_Data5 : 63|8@0+ (1,0) [0|255] ""  VCU,BCM,IPC

BO_ 1324 VCU_NM: 8 VCU
 SG_ VCU_sourceID : 7|8@0+ (1,0) [0|255] ""  BCM,SS,IPC
 SG_ VCU_CBV : 15|8@0+ (1,0) [0|255] ""  BCM,SS,IPC
 SG_ VCU_Data0 : 23|8@0+ (1,0) [0|255] ""  BCM,SS,IPC
 SG_ VCU_Data1 : 31|8@0+ (1,0) [0|255] ""  BCM,SS,IPC
 SG_ VCU_Data2 : 39|8@0+ (1,0) [0|255] ""  BCM,SS,IPC
 SG_ VCU_Data3 : 47|8@0+ (1,0) [0|255] ""  BCM,SS,IPC
 SG_ VCU_Data4 : 55|8@0+ (1,0) [0|255] ""  BCM,SS,IPC
 SG_ VCU_Data5 : 63|8@0+ (1,0) [0|255] ""  BCM,SS,IPC

CM_ SG_ 872 EDS_MotTempSenFault "Motor temperature sensor Failure    电机温度传感器故障";
CM_ SG_ 872 EDS_EDSOverTempAlarm "EDS overtemperature alarmEDS过温报警";
CM_ SG_ 872 EDS_EDSOverTempFault "EDS over-temperature FaultEDS过温故障";
CM_ SG_ 872 EDS_LV_VotagtFault "EDS low voltage power supply FailureEDS低压供电故障";
CM_ SG_ 872 EDS_PhashOverCurrentSWFault "Phase current overcurrent software Fault相电流过流软件故障";
CM_ SG_ 872 EDS_EDSCurrentSenVFault "EDS current V sensor FaultEDS电流V传感器故障";
CM_ SG_ 872 EDS_EDSCurrentSenWFault "EDS current W sensor FaultEDS电流W传感器故障";
CM_ SG_ 872 EDS_EDSHVOverVoltageAlarm "High voltage bus voltage alarm高压母线电压过高报警";
CM_ SG_ 872 EDS_EDSHVOverVoltageFault "High voltage bus voltage Fault高压母线电压过高故障";
CM_ SG_ 872 EDS_EDSHVUnderVoltageAlarm "High voltage bus voltage low alarm   高压母线电压过低报警";
CM_ SG_ 872 EDS_EDSHVUnderVoltageFault "Low voltage Fault oF high voltage bus  高压母线电压过低故障";
CM_ SG_ 872 EDS_MotOverTempAlarm "Motor overtemperature alarm电机过温报警";
CM_ SG_ 872 EDS_MotOverTempFault "Motor overtemperature Fault  电机过温故障";
CM_ SG_ 872 EDS_EDSDisChgFault "EDS active discharge FaultEDS主动放电故障";
CM_ SG_ 872 EDS_EDSHVSenFault "EDS high pressure sensor FaultEDS高压传感器故障";
CM_ SG_ 872 EDS_12VOverVoltageAlarm "12V input voltage high alarm12V输入电压过高报警";
CM_ SG_ 872 EDS_12VUnderVoltageAlarm "12V input voltage low alarm12V输入电压过低报警";
CM_ SG_ 872 EDS_MotOverAlarm "High motor speed alarm 电机速度过高报警";
CM_ SG_ 872 EDS_MotOverFault "High motor speed Fault  电机速度过高故障";
CM_ SG_ 872 EDS_PhashOverCurrentHWFault "Phase current overcurrent hardware Failure相电流过流硬件故障";
CM_ SG_ 872 EDS_EDSCurrentSenUFault "EDS current U sensor FaultEDS电流U传感器故障";
CM_ SG_ 872 EDS_VCULostFault "VCU lost communication FailureVCU丢失通信故障";
CM_ SG_ 872 EDS_BMSLostFault "BMS lost Communication FailureBMS丢失通信故障";
CM_ SG_ 872 EDS_MotRotSenFault "Motor transFormer Fault电机变压器故障";
CM_ SG_ 872 EDS_MotBlockedFault "Motor blocking Fault  电机堵转故障";
CM_ SG_ 872 EDS_EDSChksumFault "EDS Torque request checksum error messageEDS扭矩请求checksum报错";
CM_ SG_ 872 EDS_MotTrqLimtFault "Motor torque limit Fault 电机限扭故障";
CM_ SG_ 872 EDS_VCUChksumFault "VCU Checksum error";
CM_ SG_ 872 EDS_EDSEnableFault "EDS enable FailureEDS使能故障";
CM_ SG_ 872 EDS_IGBTFault "IGBT FaultIGBT故障";
CM_ SG_ 872 EDS_CANBUSOFFFault "CAN BUSOFF FaultCAN BUSOFF故障";
CM_ SG_ 872 EDS_EDSTempSensorErr "Controller temperature sensor Failure   控制器温度传感器故障";
CM_ SG_ 872 EDS_HWCapOverVolt "SoFtware detects capacitor overvoltage硬件检测电容过压";
CM_ SG_ 872 EDS_SWCapOverVolt "SoFtware testing capacitor over voltage   软件检测电容过压";
CM_ SG_ 872 EDS_EDSMemoryFlt "Controller memory unit Failure控制器存储单元故障";
CM_ SG_ 872 EDS_InitMode "EDS initializationEDS初始化";
CM_ SG_ 872 EDS_MotorSN "Motor serial number电机序号";
CM_ SG_ 872 EDS_EDSFaultCode "EDSFaultCodeEDS故障码";
CM_ SG_ 382 Checksum_0x17E "Check sum";
CM_ SG_ 382 Rolling_counter_0x17E "Rolling Counter";
CM_ SG_ 382 EPS_S_WarningLampYellow "The warning lamp (yellow)警告灯";
CM_ SG_ 382 EPS_S_SaFeLampRed "The saFe lamp (red)安全指示灯";
CM_ SG_ 382 EPS_SteerWheelAngle "The current angle oF the steering wheel(Positive, to leFt Negative, to right)";
CM_ SG_ 382 EPS_SteerWhlRotSpd "The current rotation speed oF the steering wheel.";
CM_ SG_ 382 EPS_SteerWheelRotSpdStatus "The status oF SteerWheelRotSpd    方向盘转速有效性";
CM_ SG_ 382 EPS_SteeringAngleValid "steeing angle singal valid转角信号有效性";
CM_ SG_ 382 EPS_VehicleFailureLevel "EPS Vehicle Failure Level";
CM_ SG_ 382 EPS_status "EPS statusEPS_状态";
CM_ SG_ 382 EPS_Calibrated "SAS calibration state oF steer angle sensor转向角传感器的SAS校准状态";
CM_ SG_ 382 EPS_Systemstatus "EPS system statusEPS系统状态";
CM_ SG_ 382 EPS_EPSFaultCode "EPSFaultCodeEPSEPS故障码";
CM_ SG_ 383 CheckSum_0x17F "CheckSum_0x17F校验和";
CM_ SG_ 383 Alive_SAS_0x17F "RollingCounter_0x17F循环计数";
CM_ SG_ 383 EPS_SteeringTorque "Steering torque (Positive, to left Negative, to right)";
CM_ SG_ 383 EPS_SASFailure "Angle sensor disabled";
CM_ SG_ 383 EPS_SASStsSnsr "the flag of  SAS status Punch:Steering angle status";
CM_ SG_ 383 EPS_TorqSensorStatus "Validation bit of torsion bar torque";
CM_ SG_ 383 EPS_Mode "Electric steering mode";
CM_ SG_ 383 EPS_EpsFailed "EPS Failed bit";
CM_ SG_ 673 Checksum_0x2A1 "Checksum";
CM_ SG_ 673 Rolling_Counter_0x2A1 "Rolling_Counter";
CM_ SG_ 673 EVCC_ChargeGunSts "charge gun statue";
CM_ SG_ 673 EVCC_VehicleFailureLevel "EVCC error level";
CM_ SG_ 673 EVCC_ChargeMode "charge mode DC";
CM_ SG_ 673 EVCC_CP_Value "CP dutyvalue";
CM_ SG_ 673 EVCC_CP_Sts "CP State";
CM_ SG_ 673 EVCC_PP_Value "PP resistance value or state";
CM_ SG_ 673 EVCC_Lock_Sts "lock state";
CM_ SG_ 673 EVCC_ErrCode "VCU_Error code";
CM_ SG_ 673 EVCC_DCFCPortsTempErr "Fast charge ports over temperature error";
CM_ SG_ 992 Checksum_0x3E0 "Checksum";
CM_ SG_ 992 Rolling_Counter_0x3E0 "Rolling counter";
CM_ SG_ 992 EVCC_IPC_Ack_ChgSche_stt "Status Enabled/ Disabled of Schedule Charging acknowledged by EVCC base on request from IPC IPC_ChargeScheduleSet.When this signal value = Enabled, EVCC to follow IPC,IPC_ChargingRequest = Start / Stop to start/ stop charging or stop charging when reach target SOC / battery full / chag.error.";
CM_ SG_ 992 EVCC_IPC_Ack_TargetSOC "Target SOC acknowledged by EVCC base on request from IPC";
CM_ SG_ 537 Checksum_0x219 "Checksum";
CM_ SG_ 537 Rolling_Counter_0x219 "Rolling Counter";
CM_ SG_ 537 EVCC_ChargeAllow "The flag of VCU allows BMS charging";
CM_ SG_ 537 EVCC_ChrSOCLitFb "SOC charging limit FeedbackSOC充电限制反馈";
CM_ SG_ 293 Checksum_0x125 "Checksum";
CM_ SG_ 293 Rolling_Counter_0x125 "Rolling Counter";
CM_ SG_ 293 BMS_Actual_ChgPower "Actual charging power实际充电功率";
CM_ SG_ 293 BMS_Actual_DisChgPower "BMS Allowed output power实际放电功率";
CM_ SG_ 534 Checksum_0x216 "Checksum";
CM_ SG_ 534 Rolling_Counter_0x216 "Rolling_Counter";
CM_ SG_ 534 BMS_RemainChargeTime "Charge remaining time (VCU - IPC)";
CM_ SG_ 534 BMS_ChgVoltage_REQ "BMS requires charging voltage";
CM_ SG_ 534 BMS_ChgCurrent_REQ "BMS requires charging current";
CM_ SG_ 533 Checksum_0x215 "Checksum";
CM_ SG_ 533 Rolling_Counter_0x215 "Rolling Counter";
CM_ SG_ 533 BMS_SOE "BMS State Of Enegy";
CM_ SG_ 533 BMS_HWCrash_Sts "Battery Pack Hardware Crash signal Status";
CM_ SG_ 533 BMS_HVIL_STS "The HVIL state of BMS";
CM_ SG_ 533 BMS_IGN_Sts "the ignition signal status (on/off)";
CM_ SG_ 533 BMS_Sys_STS "BMS_Status(Self-test after BMS wake-up)";
CM_ SG_ 533 BMS_HVOnOff_STS "BMS High Voltage Status(BMS_HVOnOff_STS to be received by all modules,Used as a flash programming pre-condition (replacement for engine running)";
CM_ SG_ 533 BMS_Balance_STS "BMS Balance Status";
CM_ SG_ 533 BMS_BatBalance_ERR "Battery Balance Error indicates Balancing switch is short or open";
CM_ SG_ 533 BMS_ISU_Status "Insulation status";
CM_ SG_ 533 BMS_ERR_LEV "BMSFailure Level";
CM_ SG_ 533 BMS_Vehicle_ERR_LEV "BMS Vehicle Failure Level";
CM_ SG_ 533 BMS_HV_Sts "BMS High Voltage Status";
CM_ SG_ 1171 BMS_Warning_Flag_Reserved_08 "Warning signal";
CM_ SG_ 1171 BMS_Warning_Flag_Reserved_07 "Warning signal";
CM_ SG_ 1171 BMS_Warning_Flag_Reserved_11 "Warning signal";
CM_ SG_ 1171 BMS_Warning_Flag_Reserved_10 "Warning signal";
CM_ SG_ 1171 BMS_Warning_Flag_Reserved_09 "Warning signal";
CM_ SG_ 1171 BMS_Warning_Flag_Reserved_13 "Warning signal";
CM_ SG_ 1171 BMS_Warning_Flag_Reserved_12 "Warning signal";
CM_ SG_ 1171 BMS_Warning_Flag_Reserved_06 "Warning signal";
CM_ SG_ 1171 BMS_Warning_Flag_Reserved_05 "Warning signal";
CM_ SG_ 1171 BMS_Warning_Flag_Reserved_04 "Warning signal";
CM_ SG_ 1171 BMS_MalfunctionSts "Malfunction status of battery for MHU display";
CM_ SG_ 1171 BMS_LowBattery "Low Battery Warning";
CM_ SG_ 1171 BMS_BatteryReplacement "Separate signal to indicate the battery replacement information(Battery replacement MHU)";
CM_ SG_ 1171 BMS_PackTempSts "Pack temperature warning";
CM_ SG_ 1171 BMS_ThermalRunaway "Thermalrunaway";
CM_ SG_ 1171 Rolling_Counter_0x493 "Rolling Counter";
CM_ SG_ 1171 Checksum_0x493 "Checksum";
CM_ SG_ 372 Checksum_0x174 "Checksum";
CM_ SG_ 372 Rolling_Counter_0x174 "Rolling_Counter";
CM_ SG_ 372 BMS_PackCur_MEAS "Pack Current";
CM_ SG_ 372 BMS_AllowDischgCurr "continuous maximum allowable discharge current of battery";
CM_ SG_ 372 BMS_AllowDischgCurrPeak "Peak maximum allowable discharge current of battery";
CM_ SG_ 374 Checksum_0x176 "Checksum";
CM_ SG_ 374 Rolling_Counter_0x176 "Rolling Counter";
CM_ SG_ 374 BMS_HVLinkVol_MEAS "Link Voltage";
CM_ SG_ 374 BMS_HVPackVol_MEAS "Pack Voltage";
CM_ SG_ 523 Checksum_0x20B "Checksum";
CM_ SG_ 523 Rolling_Counter_0x20B "Rolling counterRolling counter";
CM_ SG_ 523 POD_DCDC_Max_Current_Out "DCDC Current OutputDCDC Current Output";
CM_ SG_ 523 DCDC_Temp_mosfet "DCDC Mosfet tempDCDC Mosfet temp";
CM_ SG_ 523 DCDC_Voltage_Output "DCDC Output VoltageDCDC Output Voltage";
CM_ SG_ 523 DCDC_Current_Output "DCDC Output CurrentDCDC Output Current";
CM_ SG_ 523 DCDC_Output_STS "Status of DCDCStatus of DCDC";
CM_ SG_ 523 DCDC_Temp_heatsink "heatsink Temperatureheatsink Temperature";
CM_ SG_ 1030 Checksum_0x406 "Checksum";
CM_ SG_ 1030 Rolling_Counter_0x406 "Rolling counter";
CM_ SG_ 1030 DCDC_FaultLevel "DCDC error level";
CM_ SG_ 1030 DCFC_FaultLevel "DCFC error level";
CM_ SG_ 522 Checksum_0x20A "Checksum";
CM_ SG_ 522 Rolling_Counter_0x20A "Rolling counter";
CM_ SG_ 522 DCFC_Voltage_Input "FC voltage";
CM_ SG_ 522 DCDC_PTC_Temp "PTC temp";
CM_ SG_ 522 DCFC_Neg_Temp_BusBar "Busbar P temp";
CM_ SG_ 522 DCFC_STATE "DCFC contactor status";
CM_ SG_ 522 DCFC_PTC_Status "VCU indicate PTC on or off status";
CM_ SG_ 521 Checksum_0x209 "Checksum";
CM_ SG_ 521 Rolling_Counter_0x209 "Rolling_Counter";
CM_ SG_ 521 BMS_MaxDischgPwr_ALW "Allow Max Discharge Power";
CM_ SG_ 521 BMS_MaxChgPwr_ALW "Allow Max Regenerative Power";
CM_ SG_ 521 BMS_MaxDischgPwr_Peak "Peak Discharge Power";
CM_ SG_ 521 BMS_MaxChgPwr_Peak "Peak Regenerative Power";
CM_ SG_ 818 Checksum_0x332 "Checksum";
CM_ SG_ 818 Rolling_Counter_0x332 "Rolling Counter";
CM_ SG_ 818 BMS_PackTemp_Infor "Pack Temperature";
CM_ SG_ 818 BMS_PackCNom "Nominal capacity of the battery pack";
CM_ SG_ 816 Checksum_0x330 "Checksum";
CM_ SG_ 816 Rolling_Counter_0x330 "Rolling Counter";
CM_ SG_ 816 BMS_ContactorAging "Aging condition of contactor";
CM_ SG_ 375 Checksum_0x177 "Checksum";
CM_ SG_ 375 Rolling_Counter_0x177 "Rolling Counter";
CM_ SG_ 375 BMS_HVBusVol_MEAS "BUS Voltage, it is informative";
CM_ SG_ 375 BMS_HVFuseVol_MEAS "Measure voltage after fuse to identify the fuse is blown or not";
CM_ SG_ 532 Checksum_0x214 "Checksum";
CM_ SG_ 532 Rolling_Counter_0x214 "Rolling Counter";
CM_ SG_ 532 BMS_Display_SOC "Display SOC";
CM_ SG_ 532 BMS_SocActual_EST "Actual SOC";
CM_ SG_ 532 BMS_SOH "BMS State Of Health";
CM_ SG_ 885 Checksum_0x375 "Checksum";
CM_ SG_ 885 Rolling_Counter_0x375 "Rolling Counter";
CM_ SG_ 885 BMS_MainPosRelay_ERR "Main Position Relay Error";
CM_ SG_ 885 BMS_MainPosRelay_STS "Main Positive Relay Status";
CM_ SG_ 885 BMS_PreChgRelay_ERR "Precahrge relay is not working properly";
CM_ SG_ 885 BMS_PreChgRelay_STS "PreCharge Relay Status";
CM_ SG_ 885 BMS_TotalNegRelay_STS "Main Negative Relay Status";
CM_ SG_ 885 BMS_TotalNegRelay_ERR "Main Negative Relay Error";
CM_ SG_ 773 Checksum_0x305 "Checksum";
CM_ SG_ 773 Rolling_Counter_0x305 "Rolling Counter";
CM_ SG_ 773 BMS_VCU_Insulation_Mon_Sts "Feedback for the Insulation Monitoring signal";
CM_ SG_ 773 BMS_PackInsuRes "Minimum value of BCU_PosInsuRes and BCU_NegInsuRes";
CM_ SG_ 1109 Checksum_0x455 "Checksum";
CM_ SG_ 1109 Rolling_Counter_0x455 "Rolling Counter";
CM_ SG_ 1109 BMS_PackInsu_ERR "Insulation check lines have problems, short to ground or short to bat";
CM_ SG_ 1109 BMS_CellVoltDiff_ERR "max and min cell voltage difference is too large";
CM_ SG_ 1109 BMS_PackOverCurr_ERR "When the over current is detected during charging and discharging for the given period of time, then the BMS_Packovercurr_err will set";
CM_ SG_ 1109 BMS_HVIL_Err "High Voltage Interlock loop circuit error";
CM_ SG_ 1109 BMS_CellHighVol_ERR "Over voltage of the cell is detected";
CM_ SG_ 1109 BMS_CellLowVol_ERR "under voltage of the cell is detected";
CM_ SG_ 1109 BMS_PackLowVol_ERR "Pack voltage is lower than the permittable values";
CM_ SG_ 1109 BMS_PackHighVol_ERR "Pack voltage is higher than the permittable values";
CM_ SG_ 1109 BMS_ProbeHighTemp_ERR "Over temperature of the cell is detected";
CM_ SG_ 1109 BMS_ProbeTempDiff_ERR "The difference in temperture between max and min is beyound the permissable limit";
CM_ SG_ 1109 BMS_FuseStatus_ERR "Fuse and Pyro fuse blowup status";
CM_ SG_ 1109 BMS_ProbeLowTemp_ERR "Under Temperature of the cell is detected";
CM_ SG_ 646 Checksum_0x286 "Checksum";
CM_ SG_ 646 Rolling_Counter_0x286 "Rolling Counter";
CM_ SG_ 646 DCFC_OUT_DC_V "Output Voltage Value of DC High VoltageOutput Voltage Value of DC High Voltage";
CM_ SG_ 646 DCFC_OUT_DC_I "Output Current Value of DC Hight VoltageOutput Current Value of DC Hight Voltage";
CM_ SG_ 646 DCFC_DCCharge_line_V "The voltage between positive and negative DC fast charging high voltage linesThe voltage between positive and negative DC fast charging high voltage lines";
CM_ SG_ 647 DCDC_evt_BUS_OFF "bus off";
CM_ SG_ 647 DCDC_evt_MIA "Not receive Message";
CM_ SG_ 647 DCDC_evt_E2E "wrong check sum or rolling counter";
CM_ SG_ 647 DCDC_evt_Calibration_Flt "chek value calib in flash out of range";
CM_ SG_ 647 DCDC_evt_flash_Failure "not comunication with extern flash";
CM_ SG_ 647 DCDC_evt_FaultLatchCircuit "one of hw error then raise";
CM_ SG_ 647 DCDC_evt_HV_VoltSensFlt "measure value input HV out of range";
CM_ SG_ 647 DCDC_evt_HV_OverVoltFlt "over HV voltage";
CM_ SG_ 647 DCDC_evt_HV_UnderVoltFlt "input hv low or high";
CM_ SG_ 647 DCDC_evt_LV_VoltSensFlt "sensor measure value out lv out of range";
CM_ SG_ 647 DCDC_evt_LVBatt_OverVoltFlt "lv out voltage low or high";
CM_ SG_ 647 DCDC_evt_LVBatt_UnderVoltFlt "LV Bat Under Voltage";
CM_ SG_ 647 DCDC_evt_LVBatt_SensorFlt "sensor measure value battery lv out of range";
CM_ SG_ 647 DCDC_evt_LV_RedundancyFlt "Differential voltage of LV";
CM_ SG_ 647 DCDC_evt_LV_CurrSensFlt "Sensor measure lv current out of range";
CM_ SG_ 647 DCDC_evt_LV_OverCurr "lv current over";
CM_ SG_ 647 DCDC_evt_ReverseCurrFlt "reverse current fault";
CM_ SG_ 647 DCDC_evt_Heater_TempSensorFlt "over temperature heat";
CM_ SG_ 647 DCDC_evt_Mosfet_TempSensorFlt "over temperature fet";
CM_ SG_ 647 DCDC_evt_Mosfet_OverTemp "over temperature fet";
CM_ SG_ 647 DCDC_evt_HeatSink_TempSensorFlt "over temperature heat sink";
CM_ SG_ 647 DCDC_evt_HeatSink_OverTemp "over temperature heat sink";
CM_ SG_ 647 DCDC_evt_Heater_OverTempFlt "ADC fault";
CM_ SG_ 647 DCDC_evt_Heater_ShortIGBTFlt "Clock fault";
CM_ SG_ 647 DCDC_evt_LV_ShortOutputFlt "Mem fault";
CM_ SG_ 647 DCDC_evt_sw_BMS_CrashFlt "BMS crash";
CM_ SG_ 647 DCDC_evt_BMS_HVILFlt "BMS HV fault";
CM_ SG_ 648 DCFC_evt_BusbarSensFlt "busbar temp out of rangr";
CM_ SG_ 648 DCFC_evt_Contactor_Welded "Contactor weld";
CM_ SG_ 648 DCFC_evt_ContactorStuckOpen "contactor stuck open";
CM_ SG_ 648 DCFC_evt_CP_UnderVoltFlt "Charge port over voltage";
CM_ SG_ 648 DCFC_evt_DataInvalidVCUFlt "Data Invalid VCU fault";
CM_ SG_ 648 DCFC_evt_ChargePortSensFlt "Charge port voltage out of range";
CM_ SG_ 648 DCFC_evt_OverChargePortFlt "Charge port over voltage";
CM_ SG_ 648 DCFC_evt_OverBusbarTemp "busbar over temp";
CM_ SG_ 648 DCFC_evt_E2E_Flt "wrong check sum or rolling counter";
CM_ SG_ 648 DCFC_evt_MIA_Flt "Not receive Message";
CM_ SG_ 1680 SS_DiagReqData0 "Data0";
CM_ SG_ 1680 SS_DiagReqData1 "Data1";
CM_ SG_ 1680 SS_DiagReqData2 "Data2";
CM_ SG_ 1680 SS_DiagReqData3 "Data3";
CM_ SG_ 1680 SS_DiagReqData4 "Data4";
CM_ SG_ 1680 SS_DiagReqData5 "Data5";
CM_ SG_ 1680 SS_DiagReqData6 "Data6";
CM_ SG_ 1680 SS_DiagReqData7 "Data7";
CM_ SG_ 1552 SS_DiagRespData0 "Data0";
CM_ SG_ 1552 SS_DiagRespData1 "Data1";
CM_ SG_ 1552 SS_DiagRespData2 "Data2";
CM_ SG_ 1552 SS_DiagRespData3 "Data3";
CM_ SG_ 1552 SS_DiagRespData4 "Data4";
CM_ SG_ 1552 SS_DiagRespData5 "Data5";
CM_ SG_ 1552 SS_DiagRespData6 "Data6";
CM_ SG_ 1552 SS_DiagRespData7 "Data7";
CM_ SG_ 1705 ABS_DiagReqData0 "Data0";
CM_ SG_ 1705 ABS_DiagReqData1 "Data1";
CM_ SG_ 1705 ABS_DiagReqData2 "Data2";
CM_ SG_ 1705 ABS_DiagReqData3 "Data3";
CM_ SG_ 1705 ABS_DiagReqData4 "Data4";
CM_ SG_ 1705 ABS_DiagReqData5 "Data5";
CM_ SG_ 1705 ABS_DiagReqData6 "Data6";
CM_ SG_ 1705 ABS_DiagReqData7 "Data7";
CM_ SG_ 1577 ABS_DiagRespData0 "Data0";
CM_ SG_ 1577 ABS_DiagRespData1 "Data1";
CM_ SG_ 1577 ABS_DiagRespData2 "Data2";
CM_ SG_ 1577 ABS_DiagRespData3 "Data3";
CM_ SG_ 1577 ABS_DiagRespData4 "Data4";
CM_ SG_ 1577 ABS_DiagRespData5 "Data5";
CM_ SG_ 1577 ABS_DiagRespData6 "Data6";
CM_ SG_ 1577 ABS_DiagRespData7 "Data7";
CM_ SG_ 1672 ACU_DiagReqData0 "Data0";
CM_ SG_ 1672 ACU_DiagReqData1 "Data1";
CM_ SG_ 1672 ACU_DiagReqData2 "Data2";
CM_ SG_ 1672 ACU_DiagReqData3 "Data3";
CM_ SG_ 1672 ACU_DiagReqData4 "Data4";
CM_ SG_ 1672 ACU_DiagReqData5 "Data5";
CM_ SG_ 1672 ACU_DiagReqData6 "Data6";
CM_ SG_ 1672 ACU_DiagReqData7 "Data7";
CM_ SG_ 1544 ACU_DiagRespData0 "Data0";
CM_ SG_ 1544 ACU_DiagRespData1 "Data1";
CM_ SG_ 1544 ACU_DiagRespData2 "Data2";
CM_ SG_ 1544 ACU_DiagRespData3 "Data3";
CM_ SG_ 1544 ACU_DiagRespData4 "Data4";
CM_ SG_ 1544 ACU_DiagRespData5 "Data5";
CM_ SG_ 1544 ACU_DiagRespData6 "Data6";
CM_ SG_ 1544 ACU_DiagRespData7 "Data7";
CM_ SG_ 1675 IPC_DiagReqData0 "Data0";
CM_ SG_ 1675 IPC_DiagReqData1 "Data1";
CM_ SG_ 1675 IPC_DiagReqData2 "Data2";
CM_ SG_ 1675 IPC_DiagReqData3 "Data3";
CM_ SG_ 1675 IPC_DiagReqData4 "Data4";
CM_ SG_ 1675 IPC_DiagReqData5 "Data5";
CM_ SG_ 1675 IPC_DiagReqData6 "Data6";
CM_ SG_ 1675 IPC_DiagReqData7 "Data7";
CM_ SG_ 1547 IPC_DiagRespData0 "Data0";
CM_ SG_ 1547 IPC_DiagRespData1 "Data1";
CM_ SG_ 1547 IPC_DiagRespData2 "Data2";
CM_ SG_ 1547 IPC_DiagRespData3 "Data3";
CM_ SG_ 1547 IPC_DiagRespData4 "Data4";
CM_ SG_ 1547 IPC_DiagRespData5 "Data5";
CM_ SG_ 1547 IPC_DiagRespData6 "Data6";
CM_ SG_ 1547 IPC_DiagRespData7 "Data7";
CM_ SG_ 1665 BCM_DiagReqData0 "Data0";
CM_ SG_ 1665 BCM_DiagReqData1 "Data1";
CM_ SG_ 1665 BCM_DiagReqData2 "Data2";
CM_ SG_ 1665 BCM_DiagReqData3 "Data3";
CM_ SG_ 1665 BCM_DiagReqData4 "Data4";
CM_ SG_ 1665 BCM_DiagReqData5 "Data5";
CM_ SG_ 1665 BCM_DiagReqData6 "Data6";
CM_ SG_ 1665 BCM_DiagReqData7 "Data7";
CM_ SG_ 1537 BCM_DiagRespData0 "Data0";
CM_ SG_ 1537 BCM_DiagRespData1 "Data1";
CM_ SG_ 1537 BCM_DiagRespData2 "Data2";
CM_ SG_ 1537 BCM_DiagRespData3 "Data3";
CM_ SG_ 1537 BCM_DiagRespData4 "Data4";
CM_ SG_ 1537 BCM_DiagRespData5 "Data5";
CM_ SG_ 1537 BCM_DiagRespData6 "Data6";
CM_ SG_ 1537 BCM_DiagRespData7 "Data7";
CM_ SG_ 1704 EPS_DiagReqData0 "Data0";
CM_ SG_ 1704 EPS_DiagReqData1 "Data1";
CM_ SG_ 1704 EPS_DiagReqData2 "Data2";
CM_ SG_ 1704 EPS_DiagReqData3 "Data3";
CM_ SG_ 1704 EPS_DiagReqData4 "Data4";
CM_ SG_ 1704 EPS_DiagReqData5 "Data5";
CM_ SG_ 1704 EPS_DiagReqData6 "Data6";
CM_ SG_ 1704 EPS_DiagReqData7 "Data7";
CM_ SG_ 1576 EPS_DiagRespData0 "Data0";
CM_ SG_ 1576 EPS_DiagRespData1 "Data1";
CM_ SG_ 1576 EPS_DiagRespData2 "Data2";
CM_ SG_ 1576 EPS_DiagRespData3 "Data3";
CM_ SG_ 1576 EPS_DiagRespData4 "Data4";
CM_ SG_ 1576 EPS_DiagRespData5 "Data5";
CM_ SG_ 1576 EPS_DiagRespData6 "Data6";
CM_ SG_ 1576 EPS_DiagRespData7 "Data7";
CM_ SG_ 1683 BMS_DiagReqData0 "Data0";
CM_ SG_ 1683 BMS_DiagReqData1 "Data1";
CM_ SG_ 1683 BMS_DiagReqData2 "Data2";
CM_ SG_ 1683 BMS_DiagReqData3 "Data3";
CM_ SG_ 1683 BMS_DiagReqData4 "Data4";
CM_ SG_ 1683 BMS_DiagReqData5 "Data5";
CM_ SG_ 1683 BMS_DiagReqData6 "Data6";
CM_ SG_ 1683 BMS_DiagReqData7 "Data7";
CM_ SG_ 1555 BMS_DiagRespData0 "Data0";
CM_ SG_ 1555 BMS_DiagRespData1 "Data1";
CM_ SG_ 1555 BMS_DiagRespData2 "Data2";
CM_ SG_ 1555 BMS_DiagRespData3 "Data3";
CM_ SG_ 1555 BMS_DiagRespData4 "Data4";
CM_ SG_ 1555 BMS_DiagRespData5 "Data5";
CM_ SG_ 1555 BMS_DiagRespData6 "Data6";
CM_ SG_ 1555 BMS_DiagRespData7 "Data7";
CM_ SG_ 1725 DCDC_DiagReqData0 "Data0";
CM_ SG_ 1725 DCDC_DiagReqData1 "Data1";
CM_ SG_ 1725 DCDC_DiagReqData2 "Data2";
CM_ SG_ 1725 DCDC_DiagReqData3 "Data3";
CM_ SG_ 1725 DCDC_DiagReqData4 "Data4";
CM_ SG_ 1725 DCDC_DiagReqData5 "Data5";
CM_ SG_ 1725 DCDC_DiagReqData6 "Data6";
CM_ SG_ 1725 DCDC_DiagReqData7 "Data7";
CM_ SG_ 1597 DCDC_DiagRespData0 "Data0";
CM_ SG_ 1597 DCDC_DiagRespData1 "Data1";
CM_ SG_ 1597 DCDC_DiagRespData2 "Data2";
CM_ SG_ 1597 DCDC_DiagRespData3 "Data3";
CM_ SG_ 1597 DCDC_DiagRespData4 "Data4";
CM_ SG_ 1597 DCDC_DiagRespData5 "Data5";
CM_ SG_ 1597 DCDC_DiagRespData6 "Data6";
CM_ SG_ 1597 DCDC_DiagRespData7 "Data7";
CM_ SG_ 1691 EDS_DiagReqData0 "Data0";
CM_ SG_ 1691 EDS_DiagReqData1 "Data1";
CM_ SG_ 1691 EDS_DiagReqData2 "Data2";
CM_ SG_ 1691 EDS_DiagReqData3 "Data3";
CM_ SG_ 1691 EDS_DiagReqData4 "Data4";
CM_ SG_ 1691 EDS_DiagReqData5 "Data5";
CM_ SG_ 1691 EDS_DiagReqData6 "Data6";
CM_ SG_ 1691 EDS_DiagReqData7 "Data7";
CM_ SG_ 1563 EDS_DiagRespData0 "Data0";
CM_ SG_ 1563 EDS_DiagRespData1 "Data1";
CM_ SG_ 1563 EDS_DiagRespData2 "Data2";
CM_ SG_ 1563 EDS_DiagRespData3 "Data3";
CM_ SG_ 1563 EDS_DiagRespData4 "Data4";
CM_ SG_ 1563 EDS_DiagRespData5 "Data5";
CM_ SG_ 1563 EDS_DiagRespData6 "Data6";
CM_ SG_ 1563 EDS_DiagRespData7 "Data7";
CM_ SG_ 1726 OBC_DiagReqData0 "Data0";
CM_ SG_ 1726 OBC_DiagReqData1 "Data1";
CM_ SG_ 1726 OBC_DiagReqData2 "Data2";
CM_ SG_ 1726 OBC_DiagReqData3 "Data3";
CM_ SG_ 1726 OBC_DiagReqData4 "Data4";
CM_ SG_ 1726 OBC_DiagReqData5 "Data5";
CM_ SG_ 1726 OBC_DiagReqData6 "Data6";
CM_ SG_ 1726 OBC_DiagReqData7 "Data7";
CM_ SG_ 1598 OBC_DiagRespData0 "Data0";
CM_ SG_ 1598 OBC_DiagRespData1 "Data1";
CM_ SG_ 1598 OBC_DiagRespData2 "Data2";
CM_ SG_ 1598 OBC_DiagRespData3 "Data3";
CM_ SG_ 1598 OBC_DiagRespData4 "Data4";
CM_ SG_ 1598 OBC_DiagRespData5 "Data5";
CM_ SG_ 1598 OBC_DiagRespData6 "Data6";
CM_ SG_ 1598 OBC_DiagRespData7 "Data7";
CM_ SG_ 1708 VCU_DiagReqData0 "Data0";
CM_ SG_ 1708 VCU_DiagReqData1 "Data1";
CM_ SG_ 1708 VCU_DiagReqData2 "Data2";
CM_ SG_ 1708 VCU_DiagReqData3 "Data3";
CM_ SG_ 1708 VCU_DiagReqData4 "Data4";
CM_ SG_ 1708 VCU_DiagReqData5 "Data5";
CM_ SG_ 1708 VCU_DiagReqData6 "Data6";
CM_ SG_ 1708 VCU_DiagReqData7 "Data7";
CM_ SG_ 1580 VCU_DiagRespData0 "Data0";
CM_ SG_ 1580 VCU_DiagRespData1 "Data1";
CM_ SG_ 1580 VCU_DiagRespData2 "Data2";
CM_ SG_ 1580 VCU_DiagRespData3 "Data3";
CM_ SG_ 1580 VCU_DiagRespData4 "Data4";
CM_ SG_ 1580 VCU_DiagRespData5 "Data5";
CM_ SG_ 1580 VCU_DiagRespData6 "Data6";
CM_ SG_ 1580 VCU_DiagRespData7 "Data7";
CM_ SG_ 1695 EVCC_DiagReqData0 "Data0";
CM_ SG_ 1695 EVCC_DiagReqData1 "Data1";
CM_ SG_ 1695 EVCC_DiagReqData2 "Data2";
CM_ SG_ 1695 EVCC_DiagReqData3 "Data3";
CM_ SG_ 1695 EVCC_DiagReqData4 "Data4";
CM_ SG_ 1695 EVCC_DiagReqData5 "Data5";
CM_ SG_ 1695 EVCC_DiagReqData6 "Data6";
CM_ SG_ 1695 EVCC_DiagReqData7 "Data7";
CM_ SG_ 1567 EVCC_DiagRespData0 "Data0";
CM_ SG_ 1567 EVCC_DiagRespData1 "Data1";
CM_ SG_ 1567 EVCC_DiagRespData2 "Data2";
CM_ SG_ 1567 EVCC_DiagRespData3 "Data3";
CM_ SG_ 1567 EVCC_DiagRespData4 "Data4";
CM_ SG_ 1567 EVCC_DiagRespData5 "Data5";
CM_ SG_ 1567 EVCC_DiagRespData6 "Data6";
CM_ SG_ 1567 EVCC_DiagRespData7 "Data7";
CM_ SG_ 1791 DiagFunctionalAddrData0 "Data0";
CM_ SG_ 1791 DiagFunctionalAddrData1 "Data1";
CM_ SG_ 1791 DiagFunctionalAddrData2 "Data2";
CM_ SG_ 1791 DiagFunctionalAddrData3 "Data3";
CM_ SG_ 1791 DiagFunctionalAddrData4 "Data4";
CM_ SG_ 1791 DiagFunctionalAddrData5 "Data5";
CM_ SG_ 1791 DiagFunctionalAddrData6 "Data6";
CM_ SG_ 1791 DiagFunctionalAddrData7 "Data7";
CM_ SG_ 1774 IPC_FOTAFunctionalAddrData0 "Data0";
CM_ SG_ 1774 IPC_FOTAFunctionalAddrData1 "Data1";
CM_ SG_ 1774 IPC_FOTAFunctionalAddrData2 "Data2";
CM_ SG_ 1774 IPC_FOTAFunctionalAddrData3 "Data3";
CM_ SG_ 1774 IPC_FOTAFunctionalAddrData4 "Data4";
CM_ SG_ 1774 IPC_FOTAFunctionalAddrData5 "Data5";
CM_ SG_ 1774 IPC_FOTAFunctionalAddrData6 "Data6";
CM_ SG_ 1774 IPC_FOTAFunctionalAddrData7 "Data7";
CM_ SG_ 1281 BCM_sourceID "BCM_sourceID";
CM_ SG_ 1281 BCM_CBV "BCM_CBV";
CM_ SG_ 1281 BCM_Data0 "BCM_Data0";
CM_ SG_ 1281 BCM_Data1 "BCM_Data1";
CM_ SG_ 1281 BCM_Data2 "BCM_Data2";
CM_ SG_ 1281 BCM_Data3 "BCM_Data3";
CM_ SG_ 1281 BCM_Data4 "BCM_Data4";
CM_ SG_ 1281 BCM_Data5 "BCM_Data5";
CM_ SG_ 1291 IPC_sourceID "sourceID";
CM_ SG_ 1291 IPC_CBV "CBV";
CM_ SG_ 1291 IPC_Data0 "Data0";
CM_ SG_ 1291 IPC_Data1 "Data1";
CM_ SG_ 1291 IPC_Data2 "Data2";
CM_ SG_ 1291 IPC_Data3 "Data3";
CM_ SG_ 1291 IPC_Data4 "Data4";
CM_ SG_ 1291 IPC_Data5 "Data5";
CM_ SG_ 1296 SS_sourceID "source ID";
CM_ SG_ 1296 SS_CBV "CBV";
CM_ SG_ 1296 SS_Data0 "Data0";
CM_ SG_ 1296 SS_Data1 "Data1";
CM_ SG_ 1296 SS_Data2 "Data2";
CM_ SG_ 1296 SS_Data3 "Data3";
CM_ SG_ 1296 SS_Data4 "Data4";
CM_ SG_ 1296 SS_Data5 "Data5";
CM_ SG_ 1324 VCU_sourceID "source ID";
CM_ SG_ 1324 VCU_CBV "CBV";
CM_ SG_ 1324 VCU_Data0 "Data0";
CM_ SG_ 1324 VCU_Data1 "Data1";
CM_ SG_ 1324 VCU_Data2 "Data2";
CM_ SG_ 1324 VCU_Data3 "Data3";
CM_ SG_ 1324 VCU_Data4 "Data4";
CM_ SG_ 1324 VCU_Data5 "Data5";
BA_DEF_ BO_  "DiagRequest" ENUM  "No","Yes";
BA_DEF_ BO_  "DiagResponse" ENUM  "No","Yes";
BA_DEF_ BO_  "GenMsgCycleTime" INT 0 65535;
BA_DEF_ BO_  "GenMsgCycleTimeFast" INT 0 65535;
BA_DEF_ BO_  "GenMsgDelayTime" INT 0 65535;
BA_DEF_ BO_  "GenMsgILSupport" ENUM  "No","Yes";
BA_DEF_ BO_  "GenMsgNrOfRepetition" INT 0 65535;
BA_DEF_ BO_  "GenMsgSendType" ENUM  "Cycle","Event","IfActive","CE","CA";
BA_DEF_ BO_  "NmAsrMessage" ENUM  "No","Yes";
BA_DEF_ BO_  "NmMessage" ENUM  "No","Yes";
BA_DEF_ SG_  "GenSigSendType" ENUM  "Cycle","OnWrite","OnWriteWithRepetition","OnChange","OnChangeWithRepetition","IfActive","IfActiveWithRepetition";
BA_DEF_ SG_  "GenSigStartValue" INT 0 2147483647;
BA_DEF_ SG_  "GenSigInvalidValue" INT 0 2147483647;
BA_DEF_ SG_  "GenSigInactiveValue" INT 0 2147483647;
BA_DEF_DEF_  "DiagRequest" "No";
BA_DEF_DEF_  "DiagResponse" "No";
BA_DEF_DEF_  "GenMsgCycleTime" 0;
BA_DEF_DEF_  "GenMsgCycleTimeFast" 0;
BA_DEF_DEF_  "GenMsgDelayTime" 0;
BA_DEF_DEF_  "GenMsgILSupport" "Yes";
BA_DEF_DEF_  "GenMsgNrOfRepetition" 0;
BA_DEF_DEF_  "GenMsgSendType" "";
BA_DEF_DEF_  "NmAsrMessage" "No";
BA_DEF_DEF_  "NmMessage" "No";
BA_DEF_DEF_  "GenSigSendType" "";
BA_DEF_DEF_  "GenSigStartValue" 0;
BA_DEF_DEF_  "GenSigInvalidValue" 0;
BA_DEF_DEF_  "GenSigInactiveValue" 0;
BA_ "GenMsgCycleTime" BO_ 872 500;
BA_ "GenMsgSendType" BO_ 872 0;
BA_ "GenMsgCycleTime" BO_ 382 10;
BA_ "GenMsgSendType" BO_ 382 0;
BA_ "GenMsgCycleTime" BO_ 383 10;
BA_ "GenMsgSendType" BO_ 383 0;
BA_ "GenMsgCycleTime" BO_ 673 100;
BA_ "GenMsgSendType" BO_ 673 0;
BA_ "GenMsgCycleTime" BO_ 992 100;
BA_ "GenMsgSendType" BO_ 992 0;
BA_ "GenMsgCycleTime" BO_ 537 20;
BA_ "GenMsgSendType" BO_ 537 0;
BA_ "GenMsgCycleTime" BO_ 293 20;
BA_ "GenMsgSendType" BO_ 293 0;
BA_ "GenMsgCycleTime" BO_ 534 50;
BA_ "GenMsgSendType" BO_ 534 0;
BA_ "GenMsgCycleTime" BO_ 533 50;
BA_ "GenMsgSendType" BO_ 533 0;
BA_ "GenMsgCycleTime" BO_ 1171 1000;
BA_ "GenMsgSendType" BO_ 1171 0;
BA_ "GenMsgCycleTime" BO_ 372 20;
BA_ "GenMsgSendType" BO_ 372 0;
BA_ "GenMsgCycleTime" BO_ 374 50;
BA_ "GenMsgSendType" BO_ 374 0;
BA_ "GenMsgCycleTime" BO_ 523 100;
BA_ "GenMsgSendType" BO_ 523 0;
BA_ "GenMsgCycleTime" BO_ 1030 1000;
BA_ "GenMsgSendType" BO_ 1030 0;
BA_ "GenMsgCycleTime" BO_ 522 100;
BA_ "GenMsgSendType" BO_ 522 0;
BA_ "GenMsgCycleTime" BO_ 521 20;
BA_ "GenMsgSendType" BO_ 521 0;
BA_ "GenMsgCycleTime" BO_ 818 100;
BA_ "GenMsgSendType" BO_ 818 0;
BA_ "GenMsgCycleTime" BO_ 816 100;
BA_ "GenMsgSendType" BO_ 816 0;
BA_ "GenMsgCycleTime" BO_ 375 50;
BA_ "GenMsgSendType" BO_ 375 0;
BA_ "GenMsgCycleTime" BO_ 532 50;
BA_ "GenMsgSendType" BO_ 532 0;
BA_ "GenMsgCycleTime" BO_ 885 50;
BA_ "GenMsgSendType" BO_ 885 0;
BA_ "GenMsgCycleTime" BO_ 773 100;
BA_ "GenMsgSendType" BO_ 773 0;
BA_ "GenMsgCycleTime" BO_ 1109 100;
BA_ "GenMsgSendType" BO_ 1109 0;
BA_ "GenMsgCycleTime" BO_ 646 20;
BA_ "GenMsgSendType" BO_ 646 0;
BA_ "GenMsgCycleTime" BO_ 647 100;
BA_ "GenMsgSendType" BO_ 647 0;
BA_ "GenMsgCycleTime" BO_ 648 100;
BA_ "GenMsgSendType" BO_ 648 0;
BA_ "DiagRequest" BO_ 1680 1;
BA_ "GenMsgSendType" BO_ 1680 1;
BA_ "DiagResponse" BO_ 1552 1;
BA_ "GenMsgSendType" BO_ 1552 1;
BA_ "DiagRequest" BO_ 1705 1;
BA_ "GenMsgSendType" BO_ 1705 1;
BA_ "DiagResponse" BO_ 1577 1;
BA_ "GenMsgSendType" BO_ 1577 1;
BA_ "DiagRequest" BO_ 1672 1;
BA_ "GenMsgSendType" BO_ 1672 1;
BA_ "DiagResponse" BO_ 1544 1;
BA_ "GenMsgSendType" BO_ 1544 1;
BA_ "DiagRequest" BO_ 1675 1;
BA_ "GenMsgSendType" BO_ 1675 1;
BA_ "DiagResponse" BO_ 1547 1;
BA_ "GenMsgSendType" BO_ 1547 1;
BA_ "DiagRequest" BO_ 1665 1;
BA_ "GenMsgSendType" BO_ 1665 1;
BA_ "DiagResponse" BO_ 1537 1;
BA_ "GenMsgSendType" BO_ 1537 1;
BA_ "DiagRequest" BO_ 1704 1;
BA_ "GenMsgSendType" BO_ 1704 1;
BA_ "DiagResponse" BO_ 1576 1;
BA_ "GenMsgSendType" BO_ 1576 1;
BA_ "DiagRequest" BO_ 1683 1;
BA_ "GenMsgSendType" BO_ 1683 1;
BA_ "DiagResponse" BO_ 1555 1;
BA_ "GenMsgSendType" BO_ 1555 1;
BA_ "DiagRequest" BO_ 1725 1;
BA_ "GenMsgSendType" BO_ 1725 1;
BA_ "DiagResponse" BO_ 1597 1;
BA_ "GenMsgSendType" BO_ 1597 1;
BA_ "DiagRequest" BO_ 1691 1;
BA_ "GenMsgSendType" BO_ 1691 1;
BA_ "DiagResponse" BO_ 1563 1;
BA_ "GenMsgSendType" BO_ 1563 1;
BA_ "DiagRequest" BO_ 1726 1;
BA_ "GenMsgSendType" BO_ 1726 1;
BA_ "DiagResponse" BO_ 1598 1;
BA_ "GenMsgSendType" BO_ 1598 1;
BA_ "DiagRequest" BO_ 1708 1;
BA_ "GenMsgSendType" BO_ 1708 1;
BA_ "DiagResponse" BO_ 1580 1;
BA_ "GenMsgSendType" BO_ 1580 1;
BA_ "DiagRequest" BO_ 1695 1;
BA_ "GenMsgSendType" BO_ 1695 1;
BA_ "DiagResponse" BO_ 1567 1;
BA_ "GenMsgSendType" BO_ 1567 1;
BA_ "DiagRequest" BO_ 1791 1;
BA_ "GenMsgSendType" BO_ 1791 1;
BA_ "DiagRequest" BO_ 1774 1;
BA_ "GenMsgSendType" BO_ 1774 1;
BA_ "NmMessage" BO_ 1281 1;
BA_ "NmAsrMessage" BO_ 1281 1;
BA_ "GenMsgCycleTime" BO_ 1281 640;
BA_ "GenMsgSendType" BO_ 1281 0;
BA_ "NmMessage" BO_ 1291 1;
BA_ "NmAsrMessage" BO_ 1291 1;
BA_ "GenMsgCycleTime" BO_ 1291 640;
BA_ "GenMsgSendType" BO_ 1291 0;
BA_ "NmMessage" BO_ 1296 1;
BA_ "NmAsrMessage" BO_ 1296 1;
BA_ "GenMsgCycleTime" BO_ 1296 640;
BA_ "GenMsgSendType" BO_ 1296 0;
BA_ "NmMessage" BO_ 1324 1;
BA_ "NmAsrMessage" BO_ 1324 1;
BA_ "GenMsgCycleTime" BO_ 1324 640;
BA_ "GenMsgSendType" BO_ 1324 0;
BA_ "GenSigSendType" SG_ 872 EDS_MotTempSenFault 0;
BA_ "GenSigSendType" SG_ 872 EDS_EDSOverTempAlarm 0;
BA_ "GenSigSendType" SG_ 872 EDS_EDSOverTempFault 0;
BA_ "GenSigSendType" SG_ 872 EDS_LV_VotagtFault 0;
BA_ "GenSigSendType" SG_ 872 EDS_PhashOverCurrentSWFault 0;
BA_ "GenSigSendType" SG_ 872 EDS_EDSCurrentSenVFault 0;
BA_ "GenSigSendType" SG_ 872 EDS_EDSCurrentSenWFault 0;
BA_ "GenSigSendType" SG_ 872 EDS_EDSHVOverVoltageAlarm 0;
BA_ "GenSigSendType" SG_ 872 EDS_EDSHVOverVoltageFault 0;
BA_ "GenSigSendType" SG_ 872 EDS_EDSHVUnderVoltageAlarm 0;
BA_ "GenSigSendType" SG_ 872 EDS_EDSHVUnderVoltageFault 0;
BA_ "GenSigSendType" SG_ 872 EDS_MotOverTempAlarm 0;
BA_ "GenSigSendType" SG_ 872 EDS_MotOverTempFault 0;
BA_ "GenSigSendType" SG_ 872 EDS_EDSDisChgFault 0;
BA_ "GenSigSendType" SG_ 872 EDS_EDSHVSenFault 0;
BA_ "GenSigSendType" SG_ 872 EDS_12VOverVoltageAlarm 0;
BA_ "GenSigSendType" SG_ 872 EDS_12VUnderVoltageAlarm 0;
BA_ "GenSigSendType" SG_ 872 EDS_MotOverAlarm 0;
BA_ "GenSigSendType" SG_ 872 EDS_MotOverFault 0;
BA_ "GenSigSendType" SG_ 872 EDS_PhashOverCurrentHWFault 0;
BA_ "GenSigSendType" SG_ 872 EDS_EDSCurrentSenUFault 0;
BA_ "GenSigSendType" SG_ 872 EDS_VCULostFault 0;
BA_ "GenSigSendType" SG_ 872 EDS_BMSLostFault 0;
BA_ "GenSigSendType" SG_ 872 EDS_MotRotSenFault 0;
BA_ "GenSigSendType" SG_ 872 EDS_MotBlockedFault 0;
BA_ "GenSigSendType" SG_ 872 EDS_EDSChksumFault 0;
BA_ "GenSigSendType" SG_ 872 EDS_MotTrqLimtFault 0;
BA_ "GenSigSendType" SG_ 872 EDS_VCUChksumFault 0;
BA_ "GenSigSendType" SG_ 872 EDS_EDSEnableFault 0;
BA_ "GenSigSendType" SG_ 872 EDS_IGBTFault 0;
BA_ "GenSigSendType" SG_ 872 EDS_CANBUSOFFFault 0;
BA_ "GenSigSendType" SG_ 872 EDS_EDSTempSensorErr 0;
BA_ "GenSigSendType" SG_ 872 EDS_HWCapOverVolt 0;
BA_ "GenSigSendType" SG_ 872 EDS_SWCapOverVolt 0;
BA_ "GenSigSendType" SG_ 872 EDS_EDSMemoryFlt 0;
BA_ "GenSigSendType" SG_ 872 EDS_InitMode 0;
BA_ "GenSigSendType" SG_ 872 EDS_MotorSN 0;
BA_ "GenSigSendType" SG_ 872 EDS_EDSFaultCode 0;
BA_ "GenSigStartValue" SG_ 382 Checksum_0x17E 255;
BA_ "GenSigSendType" SG_ 382 Checksum_0x17E 0;
BA_ "GenSigInvalidValue" SG_ 382 Rolling_counter_0x17E 15;
BA_ "GenSigSendType" SG_ 382 Rolling_counter_0x17E 0;
BA_ "GenSigSendType" SG_ 382 EPS_S_WarningLampYellow 0;
BA_ "GenSigStartValue" SG_ 382 EPS_S_SaFeLampRed 1;
BA_ "GenSigSendType" SG_ 382 EPS_S_SaFeLampRed 0;
BA_ "GenSigStartValue" SG_ 382 EPS_SteerWheelAngle 32773;
BA_ "GenSigInvalidValue" SG_ 382 EPS_SteerWheelAngle 65535;
BA_ "GenSigSendType" SG_ 382 EPS_SteerWheelAngle 0;
BA_ "GenSigStartValue" SG_ 382 EPS_SteerWhlRotSpd 8192;
BA_ "GenSigInvalidValue" SG_ 382 EPS_SteerWhlRotSpd 16383;
BA_ "GenSigSendType" SG_ 382 EPS_SteerWhlRotSpd 0;
BA_ "GenSigInvalidValue" SG_ 382 EPS_SteerWheelRotSpdStatus 1;
BA_ "GenSigSendType" SG_ 382 EPS_SteerWheelRotSpdStatus 0;
BA_ "GenSigInvalidValue" SG_ 382 EPS_SteeringAngleValid 1;
BA_ "GenSigSendType" SG_ 382 EPS_SteeringAngleValid 0;
BA_ "GenSigSendType" SG_ 382 EPS_VehicleFailureLevel 0;
BA_ "GenSigSendType" SG_ 382 EPS_status 0;
BA_ "GenSigSendType" SG_ 382 EPS_Calibrated 0;
BA_ "GenSigSendType" SG_ 382 EPS_Systemstatus 0;
BA_ "GenSigSendType" SG_ 382 EPS_EPSFaultCode 0;
BA_ "GenSigStartValue" SG_ 383 CheckSum_0x17F 255;
BA_ "GenSigSendType" SG_ 383 CheckSum_0x17F 0;
BA_ "GenSigInvalidValue" SG_ 383 Alive_SAS_0x17F 15;
BA_ "GenSigSendType" SG_ 383 Alive_SAS_0x17F 0;
BA_ "GenSigStartValue" SG_ 383 EPS_SteeringTorque 1024;
BA_ "GenSigInvalidValue" SG_ 383 EPS_SteeringTorque 4095;
BA_ "GenSigSendType" SG_ 383 EPS_SteeringTorque 0;
BA_ "GenSigSendType" SG_ 383 EPS_SASFailure 0;
BA_ "GenSigSendType" SG_ 383 EPS_SASStsSnsr 0;
BA_ "GenSigSendType" SG_ 383 EPS_TorqSensorStatus 0;
BA_ "GenSigInvalidValue" SG_ 383 EPS_Mode 3;
BA_ "GenSigSendType" SG_ 383 EPS_Mode 0;
BA_ "GenSigStartValue" SG_ 383 EPS_EpsFailed 1;
BA_ "GenSigInvalidValue" SG_ 383 EPS_EpsFailed 1;
BA_ "GenSigSendType" SG_ 383 EPS_EpsFailed 0;
BA_ "GenSigStartValue" SG_ 673 Checksum_0x2A1 255;
BA_ "GenSigSendType" SG_ 673 Checksum_0x2A1 0;
BA_ "GenSigInvalidValue" SG_ 673 Rolling_Counter_0x2A1 15;
BA_ "GenSigSendType" SG_ 673 Rolling_Counter_0x2A1 0;
BA_ "GenSigSendType" SG_ 673 EVCC_ChargeGunSts 0;
BA_ "GenSigInvalidValue" SG_ 673 EVCC_VehicleFailureLevel 7;
BA_ "GenSigSendType" SG_ 673 EVCC_VehicleFailureLevel 0;
BA_ "GenSigSendType" SG_ 673 EVCC_ChargeMode 0;
BA_ "GenSigInvalidValue" SG_ 673 EVCC_CP_Value 255;
BA_ "GenSigSendType" SG_ 673 EVCC_CP_Value 0;
BA_ "GenSigInvalidValue" SG_ 673 EVCC_CP_Sts 15;
BA_ "GenSigSendType" SG_ 673 EVCC_CP_Sts 0;
BA_ "GenSigSendType" SG_ 673 EVCC_PP_Value 0;
BA_ "GenSigSendType" SG_ 673 EVCC_Lock_Sts 0;
BA_ "GenSigSendType" SG_ 673 EVCC_ErrCode 0;
BA_ "GenSigInvalidValue" SG_ 673 EVCC_DCFCPortsTempErr 1;
BA_ "GenSigSendType" SG_ 673 EVCC_DCFCPortsTempErr 0;
BA_ "GenSigStartValue" SG_ 992 Checksum_0x3E0 255;
BA_ "GenSigSendType" SG_ 992 Checksum_0x3E0 0;
BA_ "GenSigInvalidValue" SG_ 992 Rolling_Counter_0x3E0 15;
BA_ "GenSigSendType" SG_ 992 Rolling_Counter_0x3E0 0;
BA_ "GenSigSendType" SG_ 992 EVCC_IPC_Ack_ChgSche_stt 0;
BA_ "GenSigStartValue" SG_ 992 EVCC_IPC_Ack_TargetSOC 100;
BA_ "GenSigSendType" SG_ 992 EVCC_IPC_Ack_TargetSOC 0;
BA_ "GenSigStartValue" SG_ 537 Checksum_0x219 255;
BA_ "GenSigSendType" SG_ 537 Checksum_0x219 0;
BA_ "GenSigInvalidValue" SG_ 537 Rolling_Counter_0x219 15;
BA_ "GenSigSendType" SG_ 537 Rolling_Counter_0x219 0;
BA_ "GenSigSendType" SG_ 537 EVCC_ChargeAllow 0;
BA_ "GenSigStartValue" SG_ 537 EVCC_ChrSOCLitFb 1000;
BA_ "GenSigSendType" SG_ 537 EVCC_ChrSOCLitFb 0;
BA_ "GenSigStartValue" SG_ 293 Checksum_0x125 255;
BA_ "GenSigSendType" SG_ 293 Checksum_0x125 0;
BA_ "GenSigInvalidValue" SG_ 293 Rolling_Counter_0x125 15;
BA_ "GenSigSendType" SG_ 293 Rolling_Counter_0x125 0;
BA_ "GenSigInvalidValue" SG_ 293 BMS_Actual_ChgPower 32767;
BA_ "GenSigSendType" SG_ 293 BMS_Actual_ChgPower 0;
BA_ "GenSigInvalidValue" SG_ 293 BMS_Actual_DisChgPower 32767;
BA_ "GenSigSendType" SG_ 293 BMS_Actual_DisChgPower 0;
BA_ "GenSigStartValue" SG_ 534 Checksum_0x216 255;
BA_ "GenSigSendType" SG_ 534 Checksum_0x216 0;
BA_ "GenSigInvalidValue" SG_ 534 Rolling_Counter_0x216 15;
BA_ "GenSigSendType" SG_ 534 Rolling_Counter_0x216 0;
BA_ "GenSigInvalidValue" SG_ 534 BMS_RemainChargeTime 16383;
BA_ "GenSigSendType" SG_ 534 BMS_RemainChargeTime 0;
BA_ "GenSigInvalidValue" SG_ 534 BMS_ChgVoltage_REQ 16383;
BA_ "GenSigSendType" SG_ 534 BMS_ChgVoltage_REQ 0;
BA_ "GenSigInvalidValue" SG_ 534 BMS_ChgCurrent_REQ 65535;
BA_ "GenSigSendType" SG_ 534 BMS_ChgCurrent_REQ 0;
BA_ "GenSigStartValue" SG_ 533 Checksum_0x215 255;
BA_ "GenSigSendType" SG_ 533 Checksum_0x215 0;
BA_ "GenSigInvalidValue" SG_ 533 Rolling_Counter_0x215 15;
BA_ "GenSigSendType" SG_ 533 Rolling_Counter_0x215 0;
BA_ "GenSigStartValue" SG_ 533 BMS_SOE 54;
BA_ "GenSigSendType" SG_ 533 BMS_SOE 0;
BA_ "GenSigSendType" SG_ 533 BMS_HWCrash_Sts 0;
BA_ "GenSigSendType" SG_ 533 BMS_HVIL_STS 0;
BA_ "GenSigSendType" SG_ 533 BMS_IGN_Sts 0;
BA_ "GenSigSendType" SG_ 533 BMS_Sys_STS 0;
BA_ "GenSigSendType" SG_ 533 BMS_HVOnOff_STS 0;
BA_ "GenSigSendType" SG_ 533 BMS_Balance_STS 0;
BA_ "GenSigSendType" SG_ 533 BMS_BatBalance_ERR 0;
BA_ "GenSigSendType" SG_ 533 BMS_ISU_Status 0;
BA_ "GenSigSendType" SG_ 533 BMS_ERR_LEV 0;
BA_ "GenSigSendType" SG_ 533 BMS_Vehicle_ERR_LEV 0;
BA_ "GenSigSendType" SG_ 533 BMS_HV_Sts 0;
BA_ "GenSigSendType" SG_ 1171 BMS_Warning_Flag_Reserved_08 0;
BA_ "GenSigSendType" SG_ 1171 BMS_Warning_Flag_Reserved_07 0;
BA_ "GenSigSendType" SG_ 1171 BMS_Warning_Flag_Reserved_11 0;
BA_ "GenSigSendType" SG_ 1171 BMS_Warning_Flag_Reserved_10 0;
BA_ "GenSigSendType" SG_ 1171 BMS_Warning_Flag_Reserved_09 0;
BA_ "GenSigSendType" SG_ 1171 BMS_Warning_Flag_Reserved_13 0;
BA_ "GenSigSendType" SG_ 1171 BMS_Warning_Flag_Reserved_12 0;
BA_ "GenSigSendType" SG_ 1171 BMS_Warning_Flag_Reserved_06 0;
BA_ "GenSigSendType" SG_ 1171 BMS_Warning_Flag_Reserved_05 0;
BA_ "GenSigSendType" SG_ 1171 BMS_Warning_Flag_Reserved_04 0;
BA_ "GenSigSendType" SG_ 1171 BMS_MalfunctionSts 0;
BA_ "GenSigInvalidValue" SG_ 1171 BMS_LowBattery 3;
BA_ "GenSigSendType" SG_ 1171 BMS_LowBattery 0;
BA_ "GenSigSendType" SG_ 1171 BMS_BatteryReplacement 0;
BA_ "GenSigSendType" SG_ 1171 BMS_PackTempSts 0;
BA_ "GenSigSendType" SG_ 1171 BMS_ThermalRunaway 0;
BA_ "GenSigInvalidValue" SG_ 1171 Rolling_Counter_0x493 15;
BA_ "GenSigSendType" SG_ 1171 Rolling_Counter_0x493 0;
BA_ "GenSigStartValue" SG_ 1171 Checksum_0x493 255;
BA_ "GenSigSendType" SG_ 1171 Checksum_0x493 0;
BA_ "GenSigStartValue" SG_ 372 Checksum_0x174 255;
BA_ "GenSigSendType" SG_ 372 Checksum_0x174 0;
BA_ "GenSigInvalidValue" SG_ 372 Rolling_Counter_0x174 15;
BA_ "GenSigSendType" SG_ 372 Rolling_Counter_0x174 0;
BA_ "GenSigStartValue" SG_ 372 BMS_PackCur_MEAS 32768;
BA_ "GenSigInvalidValue" SG_ 372 BMS_PackCur_MEAS 65535;
BA_ "GenSigSendType" SG_ 372 BMS_PackCur_MEAS 0;
BA_ "GenSigInvalidValue" SG_ 372 BMS_AllowDischgCurr 65535;
BA_ "GenSigSendType" SG_ 372 BMS_AllowDischgCurr 0;
BA_ "GenSigInvalidValue" SG_ 372 BMS_AllowDischgCurrPeak 65535;
BA_ "GenSigSendType" SG_ 372 BMS_AllowDischgCurrPeak 0;
BA_ "GenSigStartValue" SG_ 374 Checksum_0x176 255;
BA_ "GenSigSendType" SG_ 374 Checksum_0x176 0;
BA_ "GenSigInvalidValue" SG_ 374 Rolling_Counter_0x176 15;
BA_ "GenSigSendType" SG_ 374 Rolling_Counter_0x176 0;
BA_ "GenSigInvalidValue" SG_ 374 BMS_HVLinkVol_MEAS 65535;
BA_ "GenSigSendType" SG_ 374 BMS_HVLinkVol_MEAS 0;
BA_ "GenSigInvalidValue" SG_ 374 BMS_HVPackVol_MEAS 65535;
BA_ "GenSigSendType" SG_ 374 BMS_HVPackVol_MEAS 0;
BA_ "GenSigStartValue" SG_ 523 Checksum_0x20B 255;
BA_ "GenSigSendType" SG_ 523 Checksum_0x20B 0;
BA_ "GenSigInvalidValue" SG_ 523 Rolling_Counter_0x20B 15;
BA_ "GenSigSendType" SG_ 523 Rolling_Counter_0x20B 0;
BA_ "GenSigInvalidValue" SG_ 523 POD_DCDC_Max_Current_Out 1023;
BA_ "GenSigSendType" SG_ 523 POD_DCDC_Max_Current_Out 0;
BA_ "GenSigInvalidValue" SG_ 523 DCDC_Temp_mosfet 255;
BA_ "GenSigSendType" SG_ 523 DCDC_Temp_mosfet 0;
BA_ "GenSigInvalidValue" SG_ 523 DCDC_Voltage_Output 1023;
BA_ "GenSigSendType" SG_ 523 DCDC_Voltage_Output 0;
BA_ "GenSigInvalidValue" SG_ 523 DCDC_Current_Output 255;
BA_ "GenSigSendType" SG_ 523 DCDC_Current_Output 0;
BA_ "GenSigSendType" SG_ 523 DCDC_Output_STS 0;
BA_ "GenSigStartValue" SG_ 523 DCDC_Temp_heatsink 40;
BA_ "GenSigInvalidValue" SG_ 523 DCDC_Temp_heatsink 255;
BA_ "GenSigSendType" SG_ 523 DCDC_Temp_heatsink 0;
BA_ "GenSigStartValue" SG_ 1030 Checksum_0x406 255;
BA_ "GenSigSendType" SG_ 1030 Checksum_0x406 0;
BA_ "GenSigInvalidValue" SG_ 1030 Rolling_Counter_0x406 15;
BA_ "GenSigSendType" SG_ 1030 Rolling_Counter_0x406 0;
BA_ "GenSigSendType" SG_ 1030 DCDC_FaultLevel 0;
BA_ "GenSigSendType" SG_ 1030 DCFC_FaultLevel 0;
BA_ "GenSigStartValue" SG_ 522 Checksum_0x20A 255;
BA_ "GenSigSendType" SG_ 522 Checksum_0x20A 0;
BA_ "GenSigInvalidValue" SG_ 522 Rolling_Counter_0x20A 15;
BA_ "GenSigSendType" SG_ 522 Rolling_Counter_0x20A 0;
BA_ "GenSigInvalidValue" SG_ 522 DCFC_Voltage_Input 1023;
BA_ "GenSigSendType" SG_ 522 DCFC_Voltage_Input 0;
BA_ "GenSigSendType" SG_ 522 DCDC_PTC_Temp 0;
BA_ "GenSigSendType" SG_ 522 DCFC_Neg_Temp_BusBar 0;
BA_ "GenSigSendType" SG_ 522 DCFC_STATE 0;
BA_ "GenSigInvalidValue" SG_ 522 DCFC_PTC_Status 3;
BA_ "GenSigSendType" SG_ 522 DCFC_PTC_Status 0;
BA_ "GenSigStartValue" SG_ 521 Checksum_0x209 255;
BA_ "GenSigSendType" SG_ 521 Checksum_0x209 0;
BA_ "GenSigInvalidValue" SG_ 521 Rolling_Counter_0x209 15;
BA_ "GenSigSendType" SG_ 521 Rolling_Counter_0x209 0;
BA_ "GenSigInvalidValue" SG_ 521 BMS_MaxDischgPwr_ALW 4095;
BA_ "GenSigSendType" SG_ 521 BMS_MaxDischgPwr_ALW 0;
BA_ "GenSigInvalidValue" SG_ 521 BMS_MaxChgPwr_ALW 4095;
BA_ "GenSigSendType" SG_ 521 BMS_MaxChgPwr_ALW 0;
BA_ "GenSigInvalidValue" SG_ 521 BMS_MaxDischgPwr_Peak 4095;
BA_ "GenSigSendType" SG_ 521 BMS_MaxDischgPwr_Peak 0;
BA_ "GenSigInvalidValue" SG_ 521 BMS_MaxChgPwr_Peak 4095;
BA_ "GenSigSendType" SG_ 521 BMS_MaxChgPwr_Peak 0;
BA_ "GenSigStartValue" SG_ 818 Checksum_0x332 255;
BA_ "GenSigSendType" SG_ 818 Checksum_0x332 0;
BA_ "GenSigInvalidValue" SG_ 818 Rolling_Counter_0x332 15;
BA_ "GenSigSendType" SG_ 818 Rolling_Counter_0x332 0;
BA_ "GenSigStartValue" SG_ 818 BMS_PackTemp_Infor 80;
BA_ "GenSigInvalidValue" SG_ 818 BMS_PackTemp_Infor 255;
BA_ "GenSigSendType" SG_ 818 BMS_PackTemp_Infor 0;
BA_ "GenSigInvalidValue" SG_ 818 BMS_PackCNom 65535;
BA_ "GenSigSendType" SG_ 818 BMS_PackCNom 0;
BA_ "GenSigStartValue" SG_ 816 Checksum_0x330 255;
BA_ "GenSigSendType" SG_ 816 Checksum_0x330 0;
BA_ "GenSigInvalidValue" SG_ 816 Rolling_Counter_0x330 15;
BA_ "GenSigSendType" SG_ 816 Rolling_Counter_0x330 0;
BA_ "GenSigInvalidValue" SG_ 816 BMS_ContactorAging 255;
BA_ "GenSigSendType" SG_ 816 BMS_ContactorAging 0;
BA_ "GenSigStartValue" SG_ 375 Checksum_0x177 255;
BA_ "GenSigSendType" SG_ 375 Checksum_0x177 0;
BA_ "GenSigInvalidValue" SG_ 375 Rolling_Counter_0x177 15;
BA_ "GenSigSendType" SG_ 375 Rolling_Counter_0x177 0;
BA_ "GenSigInvalidValue" SG_ 375 BMS_HVBusVol_MEAS 65535;
BA_ "GenSigSendType" SG_ 375 BMS_HVBusVol_MEAS 0;
BA_ "GenSigInvalidValue" SG_ 375 BMS_HVFuseVol_MEAS 65535;
BA_ "GenSigSendType" SG_ 375 BMS_HVFuseVol_MEAS 0;
BA_ "GenSigStartValue" SG_ 532 Checksum_0x214 255;
BA_ "GenSigSendType" SG_ 532 Checksum_0x214 0;
BA_ "GenSigInvalidValue" SG_ 532 Rolling_Counter_0x214 15;
BA_ "GenSigSendType" SG_ 532 Rolling_Counter_0x214 0;
BA_ "GenSigStartValue" SG_ 532 BMS_Display_SOC 100;
BA_ "GenSigInvalidValue" SG_ 532 BMS_Display_SOC 1023;
BA_ "GenSigSendType" SG_ 532 BMS_Display_SOC 0;
BA_ "GenSigSendType" SG_ 532 BMS_SocActual_EST 0;
BA_ "GenSigStartValue" SG_ 532 BMS_SOH 54;
BA_ "GenSigSendType" SG_ 532 BMS_SOH 0;
BA_ "GenSigStartValue" SG_ 885 Checksum_0x375 255;
BA_ "GenSigSendType" SG_ 885 Checksum_0x375 0;
BA_ "GenSigInvalidValue" SG_ 885 Rolling_Counter_0x375 15;
BA_ "GenSigSendType" SG_ 885 Rolling_Counter_0x375 0;
BA_ "GenSigSendType" SG_ 885 BMS_MainPosRelay_ERR 0;
BA_ "GenSigInvalidValue" SG_ 885 BMS_MainPosRelay_STS 7;
BA_ "GenSigSendType" SG_ 885 BMS_MainPosRelay_STS 0;
BA_ "GenSigSendType" SG_ 885 BMS_PreChgRelay_ERR 0;
BA_ "GenSigInvalidValue" SG_ 885 BMS_PreChgRelay_STS 7;
BA_ "GenSigSendType" SG_ 885 BMS_PreChgRelay_STS 0;
BA_ "GenSigInvalidValue" SG_ 885 BMS_TotalNegRelay_STS 7;
BA_ "GenSigSendType" SG_ 885 BMS_TotalNegRelay_STS 0;
BA_ "GenSigSendType" SG_ 885 BMS_TotalNegRelay_ERR 0;
BA_ "GenSigStartValue" SG_ 773 Checksum_0x305 255;
BA_ "GenSigSendType" SG_ 773 Checksum_0x305 0;
BA_ "GenSigInvalidValue" SG_ 773 Rolling_Counter_0x305 15;
BA_ "GenSigSendType" SG_ 773 Rolling_Counter_0x305 0;
BA_ "GenSigSendType" SG_ 773 BMS_VCU_Insulation_Mon_Sts 0;
BA_ "GenSigStartValue" SG_ 773 BMS_PackInsuRes 5535;
BA_ "GenSigSendType" SG_ 773 BMS_PackInsuRes 0;
BA_ "GenSigStartValue" SG_ 1109 Checksum_0x455 255;
BA_ "GenSigSendType" SG_ 1109 Checksum_0x455 0;
BA_ "GenSigInvalidValue" SG_ 1109 Rolling_Counter_0x455 15;
BA_ "GenSigSendType" SG_ 1109 Rolling_Counter_0x455 0;
BA_ "GenSigSendType" SG_ 1109 BMS_PackInsu_ERR 0;
BA_ "GenSigSendType" SG_ 1109 BMS_CellVoltDiff_ERR 0;
BA_ "GenSigSendType" SG_ 1109 BMS_PackOverCurr_ERR 0;
BA_ "GenSigSendType" SG_ 1109 BMS_HVIL_Err 0;
BA_ "GenSigSendType" SG_ 1109 BMS_CellHighVol_ERR 0;
BA_ "GenSigSendType" SG_ 1109 BMS_CellLowVol_ERR 0;
BA_ "GenSigSendType" SG_ 1109 BMS_PackLowVol_ERR 0;
BA_ "GenSigSendType" SG_ 1109 BMS_PackHighVol_ERR 0;
BA_ "GenSigSendType" SG_ 1109 BMS_ProbeHighTemp_ERR 0;
BA_ "GenSigSendType" SG_ 1109 BMS_ProbeTempDiff_ERR 0;
BA_ "GenSigSendType" SG_ 1109 BMS_FuseStatus_ERR 0;
BA_ "GenSigSendType" SG_ 1109 BMS_ProbeLowTemp_ERR 0;
BA_ "GenSigStartValue" SG_ 646 Checksum_0x286 255;
BA_ "GenSigSendType" SG_ 646 Checksum_0x286 0;
BA_ "GenSigInvalidValue" SG_ 646 Rolling_Counter_0x286 15;
BA_ "GenSigSendType" SG_ 646 Rolling_Counter_0x286 0;
BA_ "GenSigInvalidValue" SG_ 646 DCFC_OUT_DC_V 65535;
BA_ "GenSigSendType" SG_ 646 DCFC_OUT_DC_V 0;
BA_ "GenSigInvalidValue" SG_ 646 DCFC_OUT_DC_I 16383;
BA_ "GenSigSendType" SG_ 646 DCFC_OUT_DC_I 0;
BA_ "GenSigInvalidValue" SG_ 646 DCFC_DCCharge_line_V 65535;
BA_ "GenSigSendType" SG_ 646 DCFC_DCCharge_line_V 0;
BA_ "GenSigSendType" SG_ 647 DCDC_evt_BUS_OFF 0;
BA_ "GenSigSendType" SG_ 647 DCDC_evt_MIA 0;
BA_ "GenSigSendType" SG_ 647 DCDC_evt_E2E 0;
BA_ "GenSigSendType" SG_ 647 DCDC_evt_Calibration_Flt 0;
BA_ "GenSigSendType" SG_ 647 DCDC_evt_flash_Failure 0;
BA_ "GenSigSendType" SG_ 647 DCDC_evt_FaultLatchCircuit 0;
BA_ "GenSigSendType" SG_ 647 DCDC_evt_HV_VoltSensFlt 0;
BA_ "GenSigSendType" SG_ 647 DCDC_evt_HV_OverVoltFlt 0;
BA_ "GenSigSendType" SG_ 647 DCDC_evt_HV_UnderVoltFlt 0;
BA_ "GenSigSendType" SG_ 647 DCDC_evt_LV_VoltSensFlt 0;
BA_ "GenSigSendType" SG_ 647 DCDC_evt_LVBatt_OverVoltFlt 0;
BA_ "GenSigSendType" SG_ 647 DCDC_evt_LVBatt_UnderVoltFlt 0;
BA_ "GenSigSendType" SG_ 647 DCDC_evt_LVBatt_SensorFlt 0;
BA_ "GenSigSendType" SG_ 647 DCDC_evt_LV_RedundancyFlt 0;
BA_ "GenSigSendType" SG_ 647 DCDC_evt_LV_CurrSensFlt 0;
BA_ "GenSigSendType" SG_ 647 DCDC_evt_LV_OverCurr 0;
BA_ "GenSigSendType" SG_ 647 DCDC_evt_ReverseCurrFlt 0;
BA_ "GenSigSendType" SG_ 647 DCDC_evt_Heater_TempSensorFlt 0;
BA_ "GenSigSendType" SG_ 647 DCDC_evt_Mosfet_TempSensorFlt 0;
BA_ "GenSigSendType" SG_ 647 DCDC_evt_Mosfet_OverTemp 0;
BA_ "GenSigSendType" SG_ 647 DCDC_evt_HeatSink_TempSensorFlt 0;
BA_ "GenSigSendType" SG_ 647 DCDC_evt_HeatSink_OverTemp 0;
BA_ "GenSigSendType" SG_ 647 DCDC_evt_Heater_OverTempFlt 0;
BA_ "GenSigSendType" SG_ 647 DCDC_evt_Heater_ShortIGBTFlt 0;
BA_ "GenSigSendType" SG_ 647 DCDC_evt_LV_ShortOutputFlt 0;
BA_ "GenSigSendType" SG_ 647 DCDC_evt_sw_BMS_CrashFlt 0;
BA_ "GenSigSendType" SG_ 647 DCDC_evt_BMS_HVILFlt 0;
BA_ "GenSigSendType" SG_ 648 DCFC_evt_BusbarSensFlt 0;
BA_ "GenSigSendType" SG_ 648 DCFC_evt_Contactor_Welded 0;
BA_ "GenSigSendType" SG_ 648 DCFC_evt_ContactorStuckOpen 0;
BA_ "GenSigSendType" SG_ 648 DCFC_evt_CP_UnderVoltFlt 0;
BA_ "GenSigSendType" SG_ 648 DCFC_evt_DataInvalidVCUFlt 0;
BA_ "GenSigSendType" SG_ 648 DCFC_evt_ChargePortSensFlt 0;
BA_ "GenSigSendType" SG_ 648 DCFC_evt_OverChargePortFlt 0;
BA_ "GenSigSendType" SG_ 648 DCFC_evt_OverBusbarTemp 0;
BA_ "GenSigSendType" SG_ 648 DCFC_evt_E2E_Flt 0;
BA_ "GenSigSendType" SG_ 648 DCFC_evt_MIA_Flt 0;
BA_ "GenSigSendType" SG_ 1680 SS_DiagReqData0 0;
BA_ "GenSigSendType" SG_ 1680 SS_DiagReqData1 0;
BA_ "GenSigSendType" SG_ 1680 SS_DiagReqData2 0;
BA_ "GenSigSendType" SG_ 1680 SS_DiagReqData3 0;
BA_ "GenSigSendType" SG_ 1680 SS_DiagReqData4 0;
BA_ "GenSigSendType" SG_ 1680 SS_DiagReqData5 0;
BA_ "GenSigSendType" SG_ 1680 SS_DiagReqData6 0;
BA_ "GenSigSendType" SG_ 1680 SS_DiagReqData7 0;
BA_ "GenSigSendType" SG_ 1552 SS_DiagRespData0 0;
BA_ "GenSigSendType" SG_ 1552 SS_DiagRespData1 0;
BA_ "GenSigSendType" SG_ 1552 SS_DiagRespData2 0;
BA_ "GenSigSendType" SG_ 1552 SS_DiagRespData3 0;
BA_ "GenSigSendType" SG_ 1552 SS_DiagRespData4 0;
BA_ "GenSigSendType" SG_ 1552 SS_DiagRespData5 0;
BA_ "GenSigSendType" SG_ 1552 SS_DiagRespData6 0;
BA_ "GenSigSendType" SG_ 1552 SS_DiagRespData7 0;
BA_ "GenSigSendType" SG_ 1705 ABS_DiagReqData0 0;
BA_ "GenSigSendType" SG_ 1705 ABS_DiagReqData1 0;
BA_ "GenSigSendType" SG_ 1705 ABS_DiagReqData2 0;
BA_ "GenSigSendType" SG_ 1705 ABS_DiagReqData3 0;
BA_ "GenSigSendType" SG_ 1705 ABS_DiagReqData4 0;
BA_ "GenSigSendType" SG_ 1705 ABS_DiagReqData5 0;
BA_ "GenSigSendType" SG_ 1705 ABS_DiagReqData6 0;
BA_ "GenSigSendType" SG_ 1705 ABS_DiagReqData7 0;
BA_ "GenSigSendType" SG_ 1577 ABS_DiagRespData0 0;
BA_ "GenSigSendType" SG_ 1577 ABS_DiagRespData1 0;
BA_ "GenSigSendType" SG_ 1577 ABS_DiagRespData2 0;
BA_ "GenSigSendType" SG_ 1577 ABS_DiagRespData3 0;
BA_ "GenSigSendType" SG_ 1577 ABS_DiagRespData4 0;
BA_ "GenSigSendType" SG_ 1577 ABS_DiagRespData5 0;
BA_ "GenSigSendType" SG_ 1577 ABS_DiagRespData6 0;
BA_ "GenSigSendType" SG_ 1577 ABS_DiagRespData7 0;
BA_ "GenSigSendType" SG_ 1672 ACU_DiagReqData0 0;
BA_ "GenSigSendType" SG_ 1672 ACU_DiagReqData1 0;
BA_ "GenSigSendType" SG_ 1672 ACU_DiagReqData2 0;
BA_ "GenSigSendType" SG_ 1672 ACU_DiagReqData3 0;
BA_ "GenSigSendType" SG_ 1672 ACU_DiagReqData4 0;
BA_ "GenSigSendType" SG_ 1672 ACU_DiagReqData5 0;
BA_ "GenSigSendType" SG_ 1672 ACU_DiagReqData6 0;
BA_ "GenSigSendType" SG_ 1672 ACU_DiagReqData7 0;
BA_ "GenSigSendType" SG_ 1544 ACU_DiagRespData0 0;
BA_ "GenSigSendType" SG_ 1544 ACU_DiagRespData1 0;
BA_ "GenSigSendType" SG_ 1544 ACU_DiagRespData2 0;
BA_ "GenSigSendType" SG_ 1544 ACU_DiagRespData3 0;
BA_ "GenSigSendType" SG_ 1544 ACU_DiagRespData4 0;
BA_ "GenSigSendType" SG_ 1544 ACU_DiagRespData5 0;
BA_ "GenSigSendType" SG_ 1544 ACU_DiagRespData6 0;
BA_ "GenSigSendType" SG_ 1544 ACU_DiagRespData7 0;
BA_ "GenSigSendType" SG_ 1675 IPC_DiagReqData0 0;
BA_ "GenSigSendType" SG_ 1675 IPC_DiagReqData1 0;
BA_ "GenSigSendType" SG_ 1675 IPC_DiagReqData2 0;
BA_ "GenSigSendType" SG_ 1675 IPC_DiagReqData3 0;
BA_ "GenSigSendType" SG_ 1675 IPC_DiagReqData4 0;
BA_ "GenSigSendType" SG_ 1675 IPC_DiagReqData5 0;
BA_ "GenSigSendType" SG_ 1675 IPC_DiagReqData6 0;
BA_ "GenSigSendType" SG_ 1675 IPC_DiagReqData7 0;
BA_ "GenSigSendType" SG_ 1547 IPC_DiagRespData0 0;
BA_ "GenSigSendType" SG_ 1547 IPC_DiagRespData1 0;
BA_ "GenSigSendType" SG_ 1547 IPC_DiagRespData2 0;
BA_ "GenSigSendType" SG_ 1547 IPC_DiagRespData3 0;
BA_ "GenSigSendType" SG_ 1547 IPC_DiagRespData4 0;
BA_ "GenSigSendType" SG_ 1547 IPC_DiagRespData5 0;
BA_ "GenSigSendType" SG_ 1547 IPC_DiagRespData6 0;
BA_ "GenSigSendType" SG_ 1547 IPC_DiagRespData7 0;
BA_ "GenSigSendType" SG_ 1665 BCM_DiagReqData0 0;
BA_ "GenSigSendType" SG_ 1665 BCM_DiagReqData1 0;
BA_ "GenSigSendType" SG_ 1665 BCM_DiagReqData2 0;
BA_ "GenSigSendType" SG_ 1665 BCM_DiagReqData3 0;
BA_ "GenSigSendType" SG_ 1665 BCM_DiagReqData4 0;
BA_ "GenSigSendType" SG_ 1665 BCM_DiagReqData5 0;
BA_ "GenSigSendType" SG_ 1665 BCM_DiagReqData6 0;
BA_ "GenSigSendType" SG_ 1665 BCM_DiagReqData7 0;
BA_ "GenSigSendType" SG_ 1537 BCM_DiagRespData0 0;
BA_ "GenSigSendType" SG_ 1537 BCM_DiagRespData1 0;
BA_ "GenSigSendType" SG_ 1537 BCM_DiagRespData2 0;
BA_ "GenSigSendType" SG_ 1537 BCM_DiagRespData3 0;
BA_ "GenSigSendType" SG_ 1537 BCM_DiagRespData4 0;
BA_ "GenSigSendType" SG_ 1537 BCM_DiagRespData5 0;
BA_ "GenSigSendType" SG_ 1537 BCM_DiagRespData6 0;
BA_ "GenSigSendType" SG_ 1537 BCM_DiagRespData7 0;
BA_ "GenSigSendType" SG_ 1704 EPS_DiagReqData0 0;
BA_ "GenSigSendType" SG_ 1704 EPS_DiagReqData1 0;
BA_ "GenSigSendType" SG_ 1704 EPS_DiagReqData2 0;
BA_ "GenSigSendType" SG_ 1704 EPS_DiagReqData3 0;
BA_ "GenSigSendType" SG_ 1704 EPS_DiagReqData4 0;
BA_ "GenSigSendType" SG_ 1704 EPS_DiagReqData5 0;
BA_ "GenSigSendType" SG_ 1704 EPS_DiagReqData6 0;
BA_ "GenSigSendType" SG_ 1704 EPS_DiagReqData7 0;
BA_ "GenSigSendType" SG_ 1576 EPS_DiagRespData0 0;
BA_ "GenSigSendType" SG_ 1576 EPS_DiagRespData1 0;
BA_ "GenSigSendType" SG_ 1576 EPS_DiagRespData2 0;
BA_ "GenSigSendType" SG_ 1576 EPS_DiagRespData3 0;
BA_ "GenSigSendType" SG_ 1576 EPS_DiagRespData4 0;
BA_ "GenSigSendType" SG_ 1576 EPS_DiagRespData5 0;
BA_ "GenSigSendType" SG_ 1576 EPS_DiagRespData6 0;
BA_ "GenSigSendType" SG_ 1576 EPS_DiagRespData7 0;
BA_ "GenSigSendType" SG_ 1683 BMS_DiagReqData0 0;
BA_ "GenSigSendType" SG_ 1683 BMS_DiagReqData1 0;
BA_ "GenSigSendType" SG_ 1683 BMS_DiagReqData2 0;
BA_ "GenSigSendType" SG_ 1683 BMS_DiagReqData3 0;
BA_ "GenSigSendType" SG_ 1683 BMS_DiagReqData4 0;
BA_ "GenSigSendType" SG_ 1683 BMS_DiagReqData5 0;
BA_ "GenSigSendType" SG_ 1683 BMS_DiagReqData6 0;
BA_ "GenSigSendType" SG_ 1683 BMS_DiagReqData7 0;
BA_ "GenSigSendType" SG_ 1555 BMS_DiagRespData0 0;
BA_ "GenSigSendType" SG_ 1555 BMS_DiagRespData1 0;
BA_ "GenSigSendType" SG_ 1555 BMS_DiagRespData2 0;
BA_ "GenSigSendType" SG_ 1555 BMS_DiagRespData3 0;
BA_ "GenSigSendType" SG_ 1555 BMS_DiagRespData4 0;
BA_ "GenSigSendType" SG_ 1555 BMS_DiagRespData5 0;
BA_ "GenSigSendType" SG_ 1555 BMS_DiagRespData6 0;
BA_ "GenSigSendType" SG_ 1555 BMS_DiagRespData7 0;
BA_ "GenSigSendType" SG_ 1725 DCDC_DiagReqData0 0;
BA_ "GenSigSendType" SG_ 1725 DCDC_DiagReqData1 0;
BA_ "GenSigSendType" SG_ 1725 DCDC_DiagReqData2 0;
BA_ "GenSigSendType" SG_ 1725 DCDC_DiagReqData3 0;
BA_ "GenSigSendType" SG_ 1725 DCDC_DiagReqData4 0;
BA_ "GenSigSendType" SG_ 1725 DCDC_DiagReqData5 0;
BA_ "GenSigSendType" SG_ 1725 DCDC_DiagReqData6 0;
BA_ "GenSigSendType" SG_ 1725 DCDC_DiagReqData7 0;
BA_ "GenSigSendType" SG_ 1597 DCDC_DiagRespData0 0;
BA_ "GenSigSendType" SG_ 1597 DCDC_DiagRespData1 0;
BA_ "GenSigSendType" SG_ 1597 DCDC_DiagRespData2 0;
BA_ "GenSigSendType" SG_ 1597 DCDC_DiagRespData3 0;
BA_ "GenSigSendType" SG_ 1597 DCDC_DiagRespData4 0;
BA_ "GenSigSendType" SG_ 1597 DCDC_DiagRespData5 0;
BA_ "GenSigSendType" SG_ 1597 DCDC_DiagRespData6 0;
BA_ "GenSigSendType" SG_ 1597 DCDC_DiagRespData7 0;
BA_ "GenSigSendType" SG_ 1691 EDS_DiagReqData0 0;
BA_ "GenSigSendType" SG_ 1691 EDS_DiagReqData1 0;
BA_ "GenSigSendType" SG_ 1691 EDS_DiagReqData2 0;
BA_ "GenSigSendType" SG_ 1691 EDS_DiagReqData3 0;
BA_ "GenSigSendType" SG_ 1691 EDS_DiagReqData4 0;
BA_ "GenSigSendType" SG_ 1691 EDS_DiagReqData5 0;
BA_ "GenSigSendType" SG_ 1691 EDS_DiagReqData6 0;
BA_ "GenSigSendType" SG_ 1691 EDS_DiagReqData7 0;
BA_ "GenSigSendType" SG_ 1563 EDS_DiagRespData0 0;
BA_ "GenSigSendType" SG_ 1563 EDS_DiagRespData1 0;
BA_ "GenSigSendType" SG_ 1563 EDS_DiagRespData2 0;
BA_ "GenSigSendType" SG_ 1563 EDS_DiagRespData3 0;
BA_ "GenSigSendType" SG_ 1563 EDS_DiagRespData4 0;
BA_ "GenSigSendType" SG_ 1563 EDS_DiagRespData5 0;
BA_ "GenSigSendType" SG_ 1563 EDS_DiagRespData6 0;
BA_ "GenSigSendType" SG_ 1563 EDS_DiagRespData7 0;
BA_ "GenSigSendType" SG_ 1726 OBC_DiagReqData0 0;
BA_ "GenSigSendType" SG_ 1726 OBC_DiagReqData1 0;
BA_ "GenSigSendType" SG_ 1726 OBC_DiagReqData2 0;
BA_ "GenSigSendType" SG_ 1726 OBC_DiagReqData3 0;
BA_ "GenSigSendType" SG_ 1726 OBC_DiagReqData4 0;
BA_ "GenSigSendType" SG_ 1726 OBC_DiagReqData5 0;
BA_ "GenSigSendType" SG_ 1726 OBC_DiagReqData6 0;
BA_ "GenSigSendType" SG_ 1726 OBC_DiagReqData7 0;
BA_ "GenSigSendType" SG_ 1598 OBC_DiagRespData0 0;
BA_ "GenSigSendType" SG_ 1598 OBC_DiagRespData1 0;
BA_ "GenSigSendType" SG_ 1598 OBC_DiagRespData2 0;
BA_ "GenSigSendType" SG_ 1598 OBC_DiagRespData3 0;
BA_ "GenSigSendType" SG_ 1598 OBC_DiagRespData4 0;
BA_ "GenSigSendType" SG_ 1598 OBC_DiagRespData5 0;
BA_ "GenSigSendType" SG_ 1598 OBC_DiagRespData6 0;
BA_ "GenSigSendType" SG_ 1598 OBC_DiagRespData7 0;
BA_ "GenSigSendType" SG_ 1708 VCU_DiagReqData0 0;
BA_ "GenSigSendType" SG_ 1708 VCU_DiagReqData1 0;
BA_ "GenSigSendType" SG_ 1708 VCU_DiagReqData2 0;
BA_ "GenSigSendType" SG_ 1708 VCU_DiagReqData3 0;
BA_ "GenSigSendType" SG_ 1708 VCU_DiagReqData4 0;
BA_ "GenSigSendType" SG_ 1708 VCU_DiagReqData5 0;
BA_ "GenSigSendType" SG_ 1708 VCU_DiagReqData6 0;
BA_ "GenSigSendType" SG_ 1708 VCU_DiagReqData7 0;
BA_ "GenSigSendType" SG_ 1580 VCU_DiagRespData0 0;
BA_ "GenSigSendType" SG_ 1580 VCU_DiagRespData1 0;
BA_ "GenSigSendType" SG_ 1580 VCU_DiagRespData2 0;
BA_ "GenSigSendType" SG_ 1580 VCU_DiagRespData3 0;
BA_ "GenSigSendType" SG_ 1580 VCU_DiagRespData4 0;
BA_ "GenSigSendType" SG_ 1580 VCU_DiagRespData5 0;
BA_ "GenSigSendType" SG_ 1580 VCU_DiagRespData6 0;
BA_ "GenSigSendType" SG_ 1580 VCU_DiagRespData7 0;
BA_ "GenSigSendType" SG_ 1695 EVCC_DiagReqData0 0;
BA_ "GenSigSendType" SG_ 1695 EVCC_DiagReqData1 0;
BA_ "GenSigSendType" SG_ 1695 EVCC_DiagReqData2 0;
BA_ "GenSigSendType" SG_ 1695 EVCC_DiagReqData3 0;
BA_ "GenSigSendType" SG_ 1695 EVCC_DiagReqData4 0;
BA_ "GenSigSendType" SG_ 1695 EVCC_DiagReqData5 0;
BA_ "GenSigSendType" SG_ 1695 EVCC_DiagReqData6 0;
BA_ "GenSigSendType" SG_ 1695 EVCC_DiagReqData7 0;
BA_ "GenSigSendType" SG_ 1567 EVCC_DiagRespData0 0;
BA_ "GenSigSendType" SG_ 1567 EVCC_DiagRespData1 0;
BA_ "GenSigSendType" SG_ 1567 EVCC_DiagRespData2 0;
BA_ "GenSigSendType" SG_ 1567 EVCC_DiagRespData3 0;
BA_ "GenSigSendType" SG_ 1567 EVCC_DiagRespData4 0;
BA_ "GenSigSendType" SG_ 1567 EVCC_DiagRespData5 0;
BA_ "GenSigSendType" SG_ 1567 EVCC_DiagRespData6 0;
BA_ "GenSigSendType" SG_ 1567 EVCC_DiagRespData7 0;
BA_ "GenSigSendType" SG_ 1791 DiagFunctionalAddrData0 0;
BA_ "GenSigSendType" SG_ 1791 DiagFunctionalAddrData1 0;
BA_ "GenSigSendType" SG_ 1791 DiagFunctionalAddrData2 0;
BA_ "GenSigSendType" SG_ 1791 DiagFunctionalAddrData3 0;
BA_ "GenSigSendType" SG_ 1791 DiagFunctionalAddrData4 0;
BA_ "GenSigSendType" SG_ 1791 DiagFunctionalAddrData5 0;
BA_ "GenSigSendType" SG_ 1791 DiagFunctionalAddrData6 0;
BA_ "GenSigSendType" SG_ 1791 DiagFunctionalAddrData7 0;
BA_ "GenSigSendType" SG_ 1774 IPC_FOTAFunctionalAddrData0 0;
BA_ "GenSigSendType" SG_ 1774 IPC_FOTAFunctionalAddrData1 0;
BA_ "GenSigSendType" SG_ 1774 IPC_FOTAFunctionalAddrData2 0;
BA_ "GenSigSendType" SG_ 1774 IPC_FOTAFunctionalAddrData3 0;
BA_ "GenSigSendType" SG_ 1774 IPC_FOTAFunctionalAddrData4 0;
BA_ "GenSigSendType" SG_ 1774 IPC_FOTAFunctionalAddrData5 0;
BA_ "GenSigSendType" SG_ 1774 IPC_FOTAFunctionalAddrData6 0;
BA_ "GenSigSendType" SG_ 1774 IPC_FOTAFunctionalAddrData7 0;
BA_ "GenSigSendType" SG_ 1281 BCM_sourceID 0;
BA_ "GenSigSendType" SG_ 1281 BCM_CBV 0;
BA_ "GenSigSendType" SG_ 1281 BCM_Data0 0;
BA_ "GenSigSendType" SG_ 1281 BCM_Data1 0;
BA_ "GenSigSendType" SG_ 1281 BCM_Data2 0;
BA_ "GenSigSendType" SG_ 1281 BCM_Data3 0;
BA_ "GenSigSendType" SG_ 1281 BCM_Data4 0;
BA_ "GenSigSendType" SG_ 1281 BCM_Data5 0;
BA_ "GenSigSendType" SG_ 1291 IPC_sourceID 0;
BA_ "GenSigSendType" SG_ 1291 IPC_CBV 0;
BA_ "GenSigSendType" SG_ 1291 IPC_Data0 0;
BA_ "GenSigSendType" SG_ 1291 IPC_Data1 0;
BA_ "GenSigSendType" SG_ 1291 IPC_Data2 0;
BA_ "GenSigSendType" SG_ 1291 IPC_Data3 0;
BA_ "GenSigSendType" SG_ 1291 IPC_Data4 0;
BA_ "GenSigSendType" SG_ 1291 IPC_Data5 0;
BA_ "GenSigSendType" SG_ 1296 SS_sourceID 0;
BA_ "GenSigSendType" SG_ 1296 SS_CBV 0;
BA_ "GenSigSendType" SG_ 1296 SS_Data0 0;
BA_ "GenSigSendType" SG_ 1296 SS_Data1 0;
BA_ "GenSigSendType" SG_ 1296 SS_Data2 0;
BA_ "GenSigSendType" SG_ 1296 SS_Data3 0;
BA_ "GenSigSendType" SG_ 1296 SS_Data4 0;
BA_ "GenSigSendType" SG_ 1296 SS_Data5 0;
BA_ "GenSigSendType" SG_ 1324 VCU_sourceID 0;
BA_ "GenSigSendType" SG_ 1324 VCU_CBV 0;
BA_ "GenSigSendType" SG_ 1324 VCU_Data0 0;
BA_ "GenSigSendType" SG_ 1324 VCU_Data1 0;
BA_ "GenSigSendType" SG_ 1324 VCU_Data2 0;
BA_ "GenSigSendType" SG_ 1324 VCU_Data3 0;
BA_ "GenSigSendType" SG_ 1324 VCU_Data4 0;
BA_ "GenSigSendType" SG_ 1324 VCU_Data5 0;
VAL_ 872 EDS_MotTempSenFault 0 "Normal" 1 "Error" ;
VAL_ 872 EDS_EDSOverTempAlarm 0 "Normal" 1 "Error" ;
VAL_ 872 EDS_EDSOverTempFault 0 "Normal" 1 "Error" ;
VAL_ 872 EDS_LV_VotagtFault 0 "Normal" 1 "Error" ;
VAL_ 872 EDS_PhashOverCurrentSWFault 0 "Normal" 1 "Error" ;
VAL_ 872 EDS_EDSCurrentSenVFault 0 "Normal" 1 "Error" ;
VAL_ 872 EDS_EDSCurrentSenWFault 0 "Normal" 1 "Error" ;
VAL_ 872 EDS_EDSHVOverVoltageAlarm 0 "Normal" 1 "Error" ;
VAL_ 872 EDS_EDSHVOverVoltageFault 0 "Normal" 1 "Error" ;
VAL_ 872 EDS_EDSHVUnderVoltageAlarm 0 "Normal" 1 "Error" ;
VAL_ 872 EDS_EDSHVUnderVoltageFault 0 "Normal" 1 "Error" ;
VAL_ 872 EDS_MotOverTempAlarm 0 "Normal" 1 "Error" ;
VAL_ 872 EDS_MotOverTempFault 0 "Normal" 1 "Error" ;
VAL_ 872 EDS_EDSDisChgFault 0 "Normal" 1 "Error" ;
VAL_ 872 EDS_EDSHVSenFault 0 "Normal" 1 "Error" ;
VAL_ 872 EDS_12VOverVoltageAlarm 0 "Normal" 1 "Error" ;
VAL_ 872 EDS_12VUnderVoltageAlarm 0 "Normal" 1 "Error" ;
VAL_ 872 EDS_MotOverAlarm 0 "Normal" 1 "Error" ;
VAL_ 872 EDS_MotOverFault 0 "Normal" 1 "Error" ;
VAL_ 872 EDS_PhashOverCurrentHWFault 0 "Normal" 1 "Error" ;
VAL_ 872 EDS_EDSCurrentSenUFault 0 "Normal" 1 "Error" ;
VAL_ 872 EDS_VCULostFault 0 "Normal" 1 "Error" ;
VAL_ 872 EDS_BMSLostFault 0 "Normal" 1 "Error" ;
VAL_ 872 EDS_MotRotSenFault 0 "Normal" 1 "Error" ;
VAL_ 872 EDS_MotBlockedFault 0 "Normal" 1 "Error" ;
VAL_ 872 EDS_EDSChksumFault 0 "Normal" 1 "Error" ;
VAL_ 872 EDS_MotTrqLimtFault 0 "Normal" 1 "Error" ;
VAL_ 872 EDS_VCUChksumFault 0 "Normal" 1 "Error" ;
VAL_ 872 EDS_EDSEnableFault 0 "Normal" 1 "Error" ;
VAL_ 872 EDS_IGBTFault 0 "Normal" 1 "Error" ;
VAL_ 872 EDS_CANBUSOFFFault 0 "Normal" 1 "Error" ;
VAL_ 872 EDS_EDSTempSensorErr 0 "Normal" 1 "Error" ;
VAL_ 872 EDS_HWCapOverVolt 0 "Normal" 1 "Error" ;
VAL_ 872 EDS_SWCapOverVolt 0 "Normal" 1 "Error" ;
VAL_ 872 EDS_EDSMemoryFlt 0 "Normal" 1 "Error" ;
VAL_ 872 EDS_InitMode 0 "Normal" 1 "Error" ;
VAL_ 382 Rolling_counter_0x17E 15 "Invalid" ;
VAL_ 382 EPS_S_WarningLampYellow 0 "OFF" 1 "ON" ;
VAL_ 382 EPS_S_SaFeLampRed 0 "OFF" 1 "ON" ;
VAL_ 382 EPS_SteerWheelAngle 65535 "Invalid" ;
VAL_ 382 EPS_SteerWhlRotSpd 16383 "Invalid" ;
VAL_ 382 EPS_SteerWheelRotSpdStatus 0 "Valid" 1 "Invalid" ;
VAL_ 382 EPS_SteeringAngleValid 0 "Valid" 1 "Invalid" ;
VAL_ 382 EPS_VehicleFailureLevel 0 "Normal" 1 "Slight Fault" 2 "Minor fault" 3 "General fault" 4 "Serious Fault" 5 "Fatal fault" ;
VAL_ 382 EPS_status 0 "NoFailure" 1 "SlightFailure" 2 "CriticalFailure" 3 "FatalFailure" ;
VAL_ 382 EPS_Calibrated 0 "NotCalibrated" 1 "Calibrated" ;
VAL_ 382 EPS_Systemstatus 0 "NoFailure" 1 "SlightFailure" 2 "CriticalFailure" 3 "FatalFailure" ;
VAL_ 383 Alive_SAS_0x17F 15 "Invalid" ;
VAL_ 383 EPS_SteeringTorque 4095 "Invalid" ;
VAL_ 383 EPS_SASFailure 0 "Failure" 1 "No failure" ;
VAL_ 383 EPS_SASStsSnsr 1 "sensor value valid" 0 "sensor value Invalid" ;
VAL_ 383 EPS_TorqSensorStatus 0 "Valid" 1 "Invalid" ;
VAL_ 383 EPS_Mode 3 " Invalid" 1 "low assist" 0 "Full assist" ;
VAL_ 383 EPS_EpsFailed 1 "Failed" 0 "not Failed" ;
VAL_ 673 Rolling_Counter_0x2A1 15 "Invalid" ;
VAL_ 673 EVCC_ChargeGunSts 1 "Plug In" 0 "no Plug in" ;
VAL_ 673 EVCC_VehicleFailureLevel 0 "Normal" 1 "Slight Fault" 2 "Minor fault" 3 "General fault" 4 "Serious Fault" 5 "Fatal fault" ;
VAL_ 673 EVCC_ChargeMode 2 "DC Mode " 1 "AC Mode " 0 "Default" ;
VAL_ 673 EVCC_CP_Sts 12 "F~" 11 "E~" 10 "D~" 9 "C~" 8 "B~" 7 "A~" 6 "F" 5 "E" 4 "D" 3 "C" 2 "B" 1 "A" 0 "No CP" ;
VAL_ 673 EVCC_PP_Value 7 "CC GND" 6 "1500" 5 "680" 4 "220" 3 "100" 2 "Connection" 1 "Half Connection " 0 "No Connection" ;
VAL_ 673 EVCC_Lock_Sts 4 "Error" 3 "Unlocking" 2 "Locked" 1 "Locking " 0 "Unlock" ;
VAL_ 673 EVCC_DCFCPortsTempErr 1 "Error" 0 "Normal" ;
VAL_ 992 Rolling_Counter_0x3E0 15 "Invalid" ;
VAL_ 992 EVCC_IPC_Ack_ChgSche_stt 0 "Disabled" 1 "Enabled" 2 "Reserved" 3 "Invalid" ;
VAL_ 537 Rolling_Counter_0x219 15 "Invalid" ;
VAL_ 537 EVCC_ChargeAllow 1 "Allow " 0 "Not allow" ;
VAL_ 293 Rolling_Counter_0x125 15 "Invalid" ;
VAL_ 534 Rolling_Counter_0x216 15 "Invalid" ;
VAL_ 534 BMS_RemainChargeTime 16383 "Invalid" ;
VAL_ 534 BMS_ChgVoltage_REQ 16383 "Invalid" ;
VAL_ 534 BMS_ChgCurrent_REQ 65535 "Invalid" ;
VAL_ 533 Rolling_Counter_0x215 15 "Invalid" ;
VAL_ 533 BMS_SOE 255 "Invalid" ;
VAL_ 533 BMS_HWCrash_Sts 1 "Crash " 0 "No Crash" ;
VAL_ 533 BMS_HVIL_STS 2 "out of range" 1 "Open" 0 "Closed" ;
VAL_ 533 BMS_IGN_Sts 1 "ON " 0 "OFF" ;
VAL_ 533 BMS_Sys_STS 8 "Invalid" 7 "Failure, unable to operate" 6 "BCU Sleep mode" 5 "Successful Power Down" 4 "Power Down process" 3 "Successful Power Down of HV" 2 "Successful High Voltage Power Up" 1 "Self-check passes, can be high-voltage" 0 "Initialization of power on, self-checking" ;
VAL_ 533 BMS_HVOnOff_STS 3 "Fail to HV on " 2 "HV On " 1 "Precharge " 0 "HV Off" ;
VAL_ 533 BMS_Balance_STS 1 "active " 0 "Inactive" ;
VAL_ 533 BMS_BatBalance_ERR 1 "normal " 0 "Error" ;
VAL_ 533 BMS_ISU_Status 3 "Level3(<100 Ohms/V)" 2 "Level2(<200 Ohms/V)" 1 "Level1 <500 Ohms/V ~ >200 Ohms/V" 0 "Normal (> 500 Ohms/V)" ;
VAL_ 533 BMS_ERR_LEV 7 "Battery locked -Reserved" 6 "Fault, needs Shutdown and Wakeup" 5 "Emergency off condition" 4 "Delayed power down with FTTI" 3 "Power down without FTTI" 2 "Limp Home" 1 " Warning (any warning in system)" 0 "No error" ;
VAL_ 533 BMS_Vehicle_ERR_LEV 0 "Normal" 1 "Slight Fault" 2 "Minor fault" 3 "General fault" 4 "Serious Fault" 5 "Fatal fault" ;
VAL_ 533 BMS_HV_Sts 4 "AC Charging" 3 "DC Charging" 2 "HV ON" 1 "Precharge" 0 "HV Off" ;
VAL_ 1171 BMS_Warning_Flag_Reserved_08 1 "Warning" 0 "No warning" ;
VAL_ 1171 BMS_Warning_Flag_Reserved_07 1 "Warning" 0 "No warning" ;
VAL_ 1171 BMS_Warning_Flag_Reserved_11 1 "Warning" 0 "No warning" ;
VAL_ 1171 BMS_Warning_Flag_Reserved_10 1 "Warning" 0 "No warning" ;
VAL_ 1171 BMS_Warning_Flag_Reserved_09 1 "Warning" 0 "No warning" ;
VAL_ 1171 BMS_Warning_Flag_Reserved_13 1 "Warning" 0 "No warning" ;
VAL_ 1171 BMS_Warning_Flag_Reserved_12 1 "Warning" 0 "No warning" ;
VAL_ 1171 BMS_Warning_Flag_Reserved_06 1 "Warning" 0 "No warning" ;
VAL_ 1171 BMS_Warning_Flag_Reserved_05 1 "Warning" 0 "No warning" ;
VAL_ 1171 BMS_Warning_Flag_Reserved_04 1 "Warning" 0 "No warning" ;
VAL_ 1171 BMS_MalfunctionSts 1 "Malfunction indicator lamp ON" 0 "Malfunction indicator lamp OFF" ;
VAL_ 1171 BMS_LowBattery 2 "Extremely low level" 1 "Low level" 0 "No warning" ;
VAL_ 1171 BMS_BatteryReplacement 1 "Warning" 0 "No warning" ;
VAL_ 1171 BMS_PackTempSts 2 "Under Temperature Warning" 1 "Over Temperature Warning" 0 "No warning" ;
VAL_ 1171 BMS_ThermalRunaway 1 "Warning" 0 "No warning" ;
VAL_ 1171 Rolling_Counter_0x493 15 "Invalid" ;
VAL_ 372 Rolling_Counter_0x174 15 "Invalid" ;
VAL_ 372 BMS_PackCur_MEAS 65535 "Invalid" ;
VAL_ 372 BMS_AllowDischgCurr 65535 "Invalid" ;
VAL_ 372 BMS_AllowDischgCurrPeak 65535 "Invalid" ;
VAL_ 374 Rolling_Counter_0x176 15 "Invalid" ;
VAL_ 374 BMS_HVLinkVol_MEAS 65535 "Invalid" ;
VAL_ 374 BMS_HVPackVol_MEAS 65535 "Invalid" ;
VAL_ 523 Rolling_Counter_0x20B 15 "Invalid" ;
VAL_ 523 POD_DCDC_Max_Current_Out 1023 "Invalid" ;
VAL_ 523 DCDC_Temp_mosfet 255 "Invalid" ;
VAL_ 523 DCDC_Voltage_Output 1023 "Invalid" ;
VAL_ 523 DCDC_Current_Output 255 "Invalid" ;
VAL_ 523 DCDC_Output_STS 0 "DCDC_OFF" 1 "DCDC_STANDBY" 2 "DCDC_ON" 3 "DCDC_RESERVED" 4 "DCDC_DEGRAEDED" 5 "DCDC_FAULT_SHUTDOWN" 6 "DCDC_EMEGENCY_SHUTDOWN" 7 "DCDC_SNA" ;
VAL_ 523 DCDC_Temp_heatsink 255 "Invalid" ;
VAL_ 1030 Rolling_Counter_0x406 15 "Invalid" ;
VAL_ 1030 DCDC_FaultLevel 5 "Level5,Fatal fault" 4 "Level4,Serious fault" 3 "Level3,General fault" 2 "Level2,Minor fault" 1 "Level1,slight fault" 0 "No Fault" ;
VAL_ 1030 DCFC_FaultLevel 0 "No Fault" 2 "Level2: Serous Fault " 3 "Level3: Fatal Fault" ;
VAL_ 522 Rolling_Counter_0x20A 15 "Invalid" ;
VAL_ 522 DCFC_Voltage_Input 1023 "Invalid" ;
VAL_ 522 DCDC_PTC_Temp 255 "Invalid" ;
VAL_ 522 DCFC_Neg_Temp_BusBar 255 "Invalid" ;
VAL_ 522 DCFC_STATE 0 "DCFC_Contactors_Open_e" 1 "DCFC_Contactors_Closing" 2 "DCFC_Contactors_Close" 3 "DCFC_Contactors_Opening" 4 "DCFC_Contactors_Weld" 7 "DCFC_SNA" ;
VAL_ 522 DCFC_PTC_Status 3 "invalid" 2 "reserved" 1 "ON" 0 "OFF" ;
VAL_ 521 Rolling_Counter_0x209 15 "Invalid" ;
VAL_ 521 BMS_MaxDischgPwr_ALW 4095 "Invalid" ;
VAL_ 521 BMS_MaxChgPwr_ALW 4095 "Invalid" ;
VAL_ 521 BMS_MaxDischgPwr_Peak 4095 "Invalid" ;
VAL_ 521 BMS_MaxChgPwr_Peak 4095 "Invalid" ;
VAL_ 818 Rolling_Counter_0x332 15 "Invalid" ;
VAL_ 818 BMS_PackTemp_Infor 255 "Invalid" ;
VAL_ 816 Rolling_Counter_0x330 15 "Invalid" ;
VAL_ 816 BMS_ContactorAging 2 "Fault: counter reach 98%" 1 "Warning: counter reach 90%" 0 "Normal" ;
VAL_ 375 Rolling_Counter_0x177 15 "Invalid" ;
VAL_ 375 BMS_HVBusVol_MEAS 65535 "Invalid" ;
VAL_ 375 BMS_HVFuseVol_MEAS 65535 "Invalid" ;
VAL_ 532 Rolling_Counter_0x214 15 "Invalid" ;
VAL_ 532 BMS_Display_SOC 1023 "Invalid" ;
VAL_ 885 Rolling_Counter_0x375 15 "Invalid" ;
VAL_ 885 BMS_MainPosRelay_ERR 1 "normal " 0 "Error" ;
VAL_ 885 BMS_MainPosRelay_STS 4 "stuck open" 3 "stuck closed" 2 "closed" 1 "open" 0 "reserved" ;
VAL_ 885 BMS_PreChgRelay_ERR 1 "normal " 0 "error" ;
VAL_ 885 BMS_PreChgRelay_STS 4 "stuck open" 3 "stuck closed" 2 "closed" 1 "open" 0 "reserved" ;
VAL_ 885 BMS_TotalNegRelay_STS 4 "stuck open" 3 "stuck closed" 2 "closed" 1 "open" 0 "reserved" ;
VAL_ 885 BMS_TotalNegRelay_ERR 1 "normal " 0 "Error" ;
VAL_ 773 Rolling_Counter_0x305 15 "Invalid" ;
VAL_ 773 BMS_VCU_Insulation_Mon_Sts 1 "OFF" 0 "ON" ;
VAL_ 1109 Rolling_Counter_0x455 15 "Invalid" ;
VAL_ 1109 BMS_PackInsu_ERR 2 "Lv2-Short to vbat and open line" 1 "Lv1 - Short to ground" 0 "Lv0-No Err" ;
VAL_ 1109 BMS_CellVoltDiff_ERR 3 "Level3 Reserve" 2 "Level2 Serious alarm value" 1 "Level1 General alarm value" 0 "Level0 Normal" ;
VAL_ 1109 BMS_PackOverCurr_ERR 2 "Serious Alarm value" 1 "General Alarm Value" 0 "Normal" ;
VAL_ 1109 BMS_HVIL_Err 3 "Level3" 2 "Level2" 1 "Level1" 0 "Normal" ;
VAL_ 1109 BMS_CellHighVol_ERR 3 "Level3 Reserve" 2 "Level2 Serious alarm value" 1 "Level1 General alarm value" 0 "Level0 Normal" ;
VAL_ 1109 BMS_CellLowVol_ERR 3 "Level3 Reserve" 2 "Level2 Serious alarm value" 1 "Level1 General alarm value" 0 "Level0 Normal" ;
VAL_ 1109 BMS_PackLowVol_ERR 3 "Level3 Reserve" 2 "Level2 Serious alarm value" 1 "Level1 General alarm value" 0 "Level0 Normal" ;
VAL_ 1109 BMS_PackHighVol_ERR 3 "Level3 Reserve" 2 "Level2 Serious alarm value" 1 "Level1 General alarm value" 0 "Level0 Normal" ;
VAL_ 1109 BMS_ProbeHighTemp_ERR 3 "Level3 Reserve" 2 "Level2 Serious alarm value" 1 "Level1 General alarm value" 0 "Level0 Normal" ;
VAL_ 1109 BMS_ProbeTempDiff_ERR 3 "Level3 Reserve" 2 "Level2 Serious alarm value" 1 "Level1 General alarm value" 0 "Level0 Normal" ;
VAL_ 1109 BMS_FuseStatus_ERR 1 "Fuse blow" 0 "Normal" ;
VAL_ 1109 BMS_ProbeLowTemp_ERR 3 "Level3 Reserve" 2 "Level2 Serious alarm value" 1 "Level1 General alarm value" 0 "Level0 Normal" ;
VAL_ 646 Rolling_Counter_0x286 15 "Invalid" ;
VAL_ 646 DCFC_OUT_DC_V 65535 "Invalid" ;
VAL_ 646 DCFC_OUT_DC_I 16383 "Invalid" ;
VAL_ 646 DCFC_DCCharge_line_V 65535 "Invalid" ;
VAL_ 647 DCDC_evt_BUS_OFF 1 "Error" 0 "Normal" ;
VAL_ 647 DCDC_evt_MIA 1 "Error" 0 "Normal" ;
VAL_ 647 DCDC_evt_E2E 1 "Error" 0 "Normal" ;
VAL_ 647 DCDC_evt_Calibration_Flt 1 "Error" 0 "Normal" ;
VAL_ 647 DCDC_evt_flash_Failure 1 "Error" 0 "Normal" ;
VAL_ 647 DCDC_evt_FaultLatchCircuit 1 "Error" 0 "Normal" ;
VAL_ 647 DCDC_evt_HV_VoltSensFlt 1 "Error" 0 "Normal" ;
VAL_ 647 DCDC_evt_HV_OverVoltFlt 1 "Error" 0 "Normal" ;
VAL_ 647 DCDC_evt_HV_UnderVoltFlt 1 "Error" 0 "Normal" ;
VAL_ 647 DCDC_evt_LV_VoltSensFlt 1 "Error" 0 "Normal" ;
VAL_ 647 DCDC_evt_LVBatt_OverVoltFlt 1 "Error" 0 "Normal" ;
VAL_ 647 DCDC_evt_LVBatt_UnderVoltFlt 1 "Error" 0 "Normal" ;
VAL_ 647 DCDC_evt_LVBatt_SensorFlt 1 "Error" 0 "Normal" ;
VAL_ 647 DCDC_evt_LV_RedundancyFlt 1 "Error" 0 "Normal" ;
VAL_ 647 DCDC_evt_LV_CurrSensFlt 1 "Error" 0 "Normal" ;
VAL_ 647 DCDC_evt_LV_OverCurr 1 "Error" 0 "Normal" ;
VAL_ 647 DCDC_evt_ReverseCurrFlt 1 "Error" 0 "Normal" ;
VAL_ 647 DCDC_evt_Heater_TempSensorFlt 1 "Error" 0 "Normal" ;
VAL_ 647 DCDC_evt_Mosfet_TempSensorFlt 1 "Error" 0 "Normal" ;
VAL_ 647 DCDC_evt_Mosfet_OverTemp 1 "Error" 0 "Normal" ;
VAL_ 647 DCDC_evt_HeatSink_TempSensorFlt 1 "Error" 0 "Normal" ;
VAL_ 647 DCDC_evt_HeatSink_OverTemp 1 "Error" 0 "Normal" ;
VAL_ 647 DCDC_evt_Heater_OverTempFlt 1 "Error" 0 "Normal" ;
VAL_ 647 DCDC_evt_Heater_ShortIGBTFlt 1 "Error" 0 "Normal" ;
VAL_ 647 DCDC_evt_LV_ShortOutputFlt 1 "Error" 0 "Normal" ;
VAL_ 647 DCDC_evt_sw_BMS_CrashFlt 1 "Error" 0 "Normal" ;
VAL_ 647 DCDC_evt_BMS_HVILFlt 1 "Error" 0 "Normal" ;
VAL_ 648 DCFC_evt_BusbarSensFlt 1 "Error" 0 "Normal" ;
VAL_ 648 DCFC_evt_Contactor_Welded 1 "Error" 0 "Normal" ;
VAL_ 648 DCFC_evt_ContactorStuckOpen 1 "Error" 0 "Normal" ;
VAL_ 648 DCFC_evt_CP_UnderVoltFlt 1 "Error" 0 "Normal" ;
VAL_ 648 DCFC_evt_DataInvalidVCUFlt 1 "Error" 0 "Normal" ;
VAL_ 648 DCFC_evt_ChargePortSensFlt 1 "Error" 0 "Normal" ;
VAL_ 648 DCFC_evt_OverChargePortFlt 1 "Error" 0 "Normal" ;
VAL_ 648 DCFC_evt_OverBusbarTemp 1 "Error" 0 "Normal" ;
VAL_ 648 DCFC_evt_E2E_Flt 1 "Error" 0 "Normal" ;
VAL_ 648 DCFC_evt_MIA_Flt 1 "Error" 0 "Normal" ;
